VERSION ""

NS_ :

BS_:

BU_: ALARMS_RELAY RUR RUF LOGBOX HVAC CP6 CP10 RUC BC BMS1_SDB BMS2_SDB BMS0_SDB _TESTER NC_SENSOR IVS
VAL_TABLE_ Vis_Activation 1 "ON" 0 "OFF" ;
VAL_TABLE_ Vis_Blackout 1 "BLACKOUT" 0 "NO_BLACKOUT" ;
VAL_TABLE_ ___spare___ 3 "_SPARE_3" 2 "_SPARE_2" 1 "_SPARE_1" 0 "_SPARE_0" ;
VAL_TABLE_ HeaterWaterTemp 255 "NOT AVAILABLE" 254 "ERROR" ;

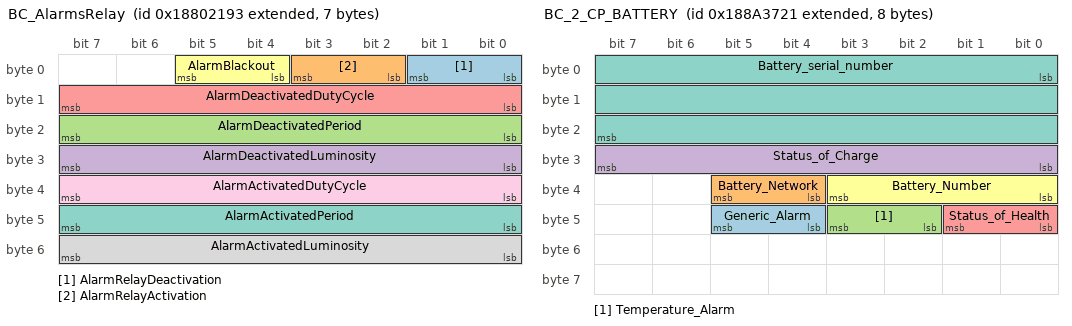
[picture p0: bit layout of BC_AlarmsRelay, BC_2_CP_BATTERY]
BO_ 2558534035 BC_AlarmsRelay: 7 BC
 SG_ AlarmRelayDeactivation : 0|2@1+ (1,0) [0|0] "bit"  ALARMS_RELAY
 SG_ AlarmRelayActivation : 2|2@1+ (1,0) [0|0] "bit"  ALARMS_RELAY
 SG_ AlarmDeactivatedPeriod : 16|8@1+ (1,0) [0|250] "1/10sec"  ALARMS_RELAY
 SG_ AlarmDeactivatedLuminosity : 24|8@1+ (0.4,0) [0|100] "%"  ALARMS_RELAY
 SG_ AlarmDeactivatedDutyCycle : 8|8@1+ (0.4,0) [0|100] "%"  ALARMS_RELAY
 SG_ AlarmBlackout : 4|2@1+ (1,0) [0|0] ""  ALARMS_RELAY
 SG_ AlarmActivatedPeriod : 40|8@1+ (1,0) [0|250] "1/10sec"  ALARMS_RELAY
 SG_ AlarmActivatedLuminosity : 48|8@1+ (0.4,0) [0|100] "%"  ALARMS_RELAY
 SG_ AlarmActivatedDutyCycle : 32|8@1+ (0.4,0) [0|100] "%"  ALARMS_RELAY

BO_ 2559194913 BC_2_CP_BATTERY: 8 BC
 SG_ Generic_Alarm : 44|2@1+ (1,0) [0|3] "-"  CP6,CP10,LOGBOX
 SG_ Battery_Network : 36|2@1+ (1,0) [0|3] "-"  CP6,CP10,LOGBOX
 SG_ Temperature_Alarm : 42|2@1+ (1,0) [0|3] "-"  CP6,CP10,LOGBOX
 SG_ Status_of_Charge : 24|8@1+ (1,0) [0|100] "%"  CP6,CP10,LOGBOX
 SG_ Status_of_Health : 40|2@1+ (1,0) [0|3] "-"  CP6,CP10,LOGBOX
 SG_ Battery_Number : 32|4@1+ (1,0) [0|15] "-"  CP6,CP10,LOGBOX
 SG_ Battery_serial_number : 0|24@1+ (1,0) [0|16777214] "-"  CP6,CP10,LOGBOX

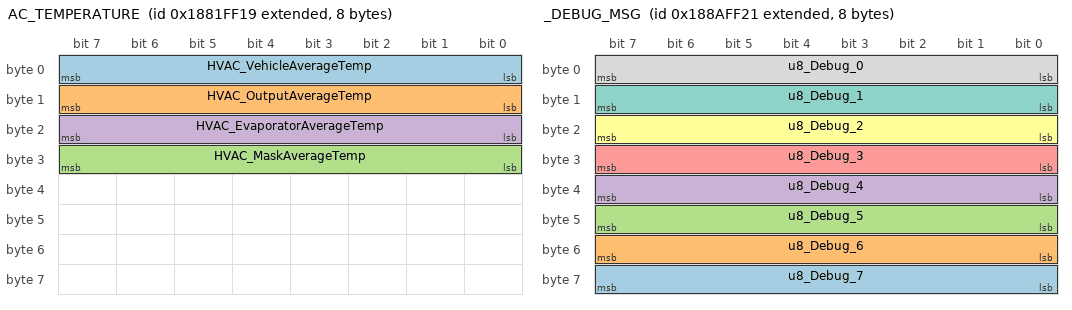
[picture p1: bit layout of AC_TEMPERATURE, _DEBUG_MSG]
BO_ 2558656281 AC_TEMPERATURE: 8 HVAC
 SG_ HVAC_VehicleAverageTemp : 0|8@1+ (1,-40) [-40|210] "°C"  BC,LOGBOX
 SG_ HVAC_OutputAverageTemp : 8|8@1+ (1,-40) [-40|210] "°C"  BC,LOGBOX
 SG_ HVAC_MaskAverageTemp : 24|8@1+ (1,-40) [-40|210] "°C"  BC,LOGBOX
 SG_ HVAC_EvaporatorAverageTemp : 16|8@1+ (1,-40) [-40|210] "°C"  BC,LOGBOX

BO_ 2559246113 _DEBUG_MSG: 8 BC
 SG_ u8_Debug_7 : 56|8@1+ (1,0) [0|255] "-"  LOGBOX
 SG_ u8_Debug_6 : 48|8@1+ (1,0) [0|255] "-"  LOGBOX
 SG_ u8_Debug_5 : 40|8@1+ (1,0) [0|255] "-"  LOGBOX
 SG_ u8_Debug_4 : 32|8@1+ (1,0) [0|255] "-"  LOGBOX
 SG_ u8_Debug_3 : 24|8@1+ (1,0) [0|255] "-"  LOGBOX
 SG_ u8_Debug_2 : 16|8@1+ (1,0) [0|255] "-"  LOGBOX
 SG_ u8_Debug_1 : 8|8@1+ (1,0) [0|255] "-"  LOGBOX
 SG_ u8_Debug_0 : 0|8@1+ (1,0) [0|255] "-"  LOGBOX

BO_ 2559129377 TRIP_PARTIALS: 8 BC
 SG_ Partial_km : 0|16@1+ (0.1,0) [0|6400] "km"  LOGBOX,CP6,CP10
 SG_ Partial_h : 16|16@1+ (0.1,0) [0|6400] "h"  LOGBOX,CP6,CP10

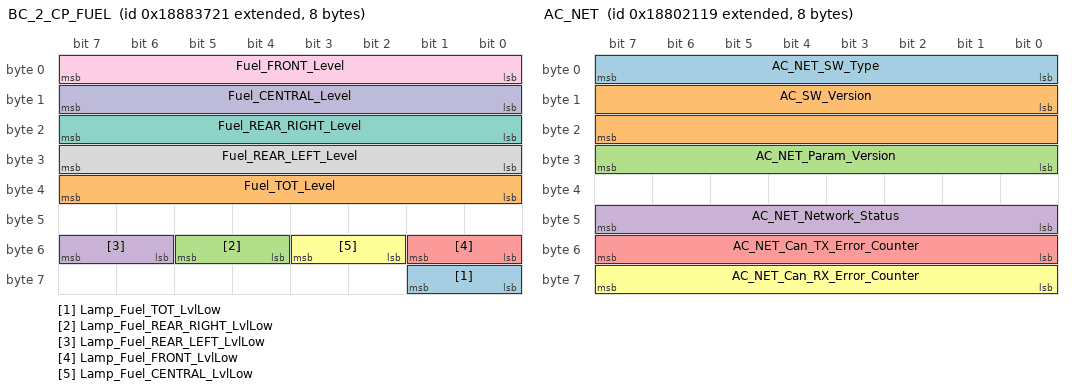
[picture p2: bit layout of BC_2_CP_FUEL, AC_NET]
BO_ 2559063841 BC_2_CP_FUEL: 8 BC
 SG_ Lamp_Fuel_TOT_LvlLow : 56|2@1+ (1,0) [0|3] "-"  IVS,LOGBOX,CP6,CP10
 SG_ Fuel_TOT_Level : 32|8@1+ (0.4,0) [0|100] "%"  LOGBOX,CP6,CP10
 SG_ Lamp_Fuel_REAR_RIGHT_LvlLow : 52|2@1+ (1,0) [0|3] "-"  LOGBOX,CP6,CP10
 SG_ Lamp_Fuel_REAR_LEFT_LvlLow : 54|2@1+ (1,0) [0|3] "-"  LOGBOX,CP6,CP10
 SG_ Lamp_Fuel_FRONT_LvlLow : 48|2@1+ (1,0) [0|3] "-"  LOGBOX,CP6,CP10
 SG_ Lamp_Fuel_CENTRAL_LvlLow : 50|2@1+ (1,0) [0|3] "-"  LOGBOX,CP6,CP10
 SG_ Fuel_REAR_RIGHT_Level : 16|8@1+ (0.4,0) [0|100] "%"  LOGBOX,CP6,CP10
 SG_ Fuel_REAR_LEFT_Level : 24|8@1+ (0.4,0) [0|100] "%"  LOGBOX,CP6,CP10
 SG_ Fuel_FRONT_Level : 0|8@1+ (0.4,0) [0|100] "%"  LOGBOX,CP6,CP10
 SG_ Fuel_CENTRAL_Level : 8|8@1+ (0.4,0) [0|100] "%"  LOGBOX,CP6,CP10

BO_ 2566834942 _DM1: 42 Vector__XXX
 SG_ SPN10_Low : 320|16@1+ (1,0) [0|65536] "-"  CP6,CP10,LOGBOX
 SG_ SPN9_Low : 288|16@1+ (1,0) [0|65536] "-"  CP6,CP10,LOGBOX
 SG_ SPN8_Low : 256|16@1+ (1,0) [0|65536] "-"  CP6,CP10,LOGBOX
 SG_ SPN7_Low : 224|16@1+ (1,0) [0|65536] "-"  CP6,CP10,LOGBOX
 SG_ SPN6_Low : 192|16@1+ (1,0) [0|65536] "-"  CP6,CP10,LOGBOX
 SG_ SPN5_Low : 144|16@1+ (1,0) [0|65536] "-"  CP6,CP10,LOGBOX
 SG_ SPN4_Low : 112|16@1+ (1,0) [0|65536] "-"  CP6,CP10,LOGBOX
 SG_ SPN3_Low : 80|16@1+ (1,0) [0|65536] "-"  CP6,CP10,LOGBOX
 SG_ SPN2_Low : 48|16@1+ (1,0) [0|65536] "-"  CP6,CP10,LOGBOX
 SG_ FailureModeIdentifier10 : 304|5@1+ (1,0) [0|31] "-"  CP6,CP10,LOGBOX
 SG_ FailureModeIdentifier9 : 272|5@1+ (1,0) [0|31] "-"  CP6,CP10,LOGBOX
 SG_ FailureModeIdentifier8 : 240|5@1+ (1,0) [0|31] "-"  CP6,CP10,LOGBOX
 SG_ FailureModeIdentifier7 : 208|5@1+ (1,0) [0|31] "-"  CP6,CP10,LOGBOX
 SG_ FailureModeIdentifier6 : 176|5@1+ (1,0) [0|31] "-"  CP6,CP10,LOGBOX
 SG_ FailureModeIdentifier5 : 160|5@1+ (1,0) [0|31] "-"  CP6,CP10,LOGBOX
 SG_ FailureModeIdentifier4 : 128|5@1+ (1,0) [0|31] "-"  CP6,CP10,LOGBOX
 SG_ FailureModeIdentifier3 : 96|5@1+ (1,0) [0|31] "-"  CP6,CP10,LOGBOX
 SG_ FlashRedStopLamp : 12|2@1+ (1,0) [0|3] "-"  CP6,CP10,LOGBOX
 SG_ FlashProtectLamp : 8|2@1+ (1,0) [0|3] "-"  CP6,CP10,LOGBOX
 SG_ FlashMalfuncIndicatorLamp : 14|2@1+ (1,0) [0|3] "-"  CP6,CP10,LOGBOX
 SG_ FlashAmberWarningLamp : 10|2@1+ (1,0) [0|3] "-"  CP6,CP10,LOGBOX
 SG_ MalfunctionIndicatorLampStatus : 6|2@1+ (1,0) [0|3] "-"  CP6,CP10,LOGBOX
 SG_ AmberWarningLampStatus : 2|2@1+ (1,0) [0|3] "-"  CP6,CP10,LOGBOX
 SG_ OccurenceCount1 : 40|7@1+ (1,0) [0|126] "-"  CP6,CP10,LOGBOX
 SG_ SPNConversionMethod1 : 47|1@1+ (1,0) [0|1] "-"  CP6,CP10,LOGBOX
 SG_ FailureModeIdentifier1 : 32|5@1+ (1,0) [0|31] "-"  CP6,CP10,LOGBOX
 SG_ SPN1_Low : 16|16@1+ (1,0) [0|65536] "-"  CP6,CP10,LOGBOX
 SG_ RedStopLampState : 4|2@1+ (1,0) [0|3] "-"  CP6,CP10,LOGBOX
 SG_ ProtectLampStatus : 0|2@1+ (1,0) [0|3] "-"  CP6,CP10,LOGBOX
 SG_ FailureModeIdentifier2 : 64|5@1+ (1,0) [0|31] "-"  CP6,CP10,LOGBOX
 SG_ SPNConversionMethod10 : 319|1@1+ (1,0) [0|1] "-"  CP6,CP10,LOGBOX
 SG_ SPNConversionMethod9 : 287|1@1+ (1,0) [0|1] "-"  CP6,CP10,LOGBOX
 SG_ SPNConversionMethod8 : 255|1@1+ (1,0) [0|1] "-"  CP6,CP10,LOGBOX
 SG_ SPNConversionMethod7 : 223|1@1+ (1,0) [0|1] "-"  CP6,CP10,LOGBOX
 SG_ SPNConversionMethod6 : 191|1@1+ (1,0) [0|1] "-"  CP6,CP10,LOGBOX
 SG_ SPNConversionMethod5 : 175|1@1+ (1,0) [0|1] "-"  CP6,CP10,LOGBOX
 SG_ SPNConversionMethod4 : 143|1@1+ (1,0) [0|1] "-"  CP6,CP10,LOGBOX
 SG_ SPNConversionMethod3 : 111|1@1+ (1,0) [0|1] "-"  CP6,CP10,LOGBOX
 SG_ SPNConversionMethod2 : 79|1@1+ (1,0) [0|1] "-"  CP6,CP10,LOGBOX
 SG_ OccurenceCount10 : 312|7@1+ (1,0) [0|126] "-"  CP6,CP10,LOGBOX
 SG_ OccurenceCount9 : 280|7@1+ (1,0) [0|126] "-"  CP6,CP10,LOGBOX
 SG_ OccurenceCount8 : 248|7@1+ (1,0) [0|126] "-"  CP6,CP10,LOGBOX
 SG_ OccurenceCount7 : 216|7@1+ (1,0) [0|126] "-"  CP6,CP10,LOGBOX
 SG_ OccurenceCount6 : 184|7@1+ (1,0) [0|126] "-"  CP6,CP10,LOGBOX
 SG_ OccurenceCount5 : 168|7@1+ (1,0) [0|126] "-"  CP6,CP10,LOGBOX
 SG_ OccurenceCount4 : 136|7@1+ (1,0) [0|126] "-"  CP6,CP10,LOGBOX
 SG_ OccurenceCount3 : 104|7@1+ (1,0) [0|126] "-"  CP6,CP10,LOGBOX
 SG_ OccurenceCount2 : 72|7@1+ (1,0) [0|126] "-"  CP6,CP10,LOGBOX
 SG_ SPN10_High : 309|3@1+ (1,0) [0|7] "-"  CP6,CP10,LOGBOX
 SG_ SPN9_High : 277|3@1+ (1,0) [0|7] "-"  CP6,CP10,LOGBOX
 SG_ SPN8_High : 245|3@1+ (1,0) [0|7] "-"  CP6,CP10,LOGBOX
 SG_ SPN7_High : 213|3@1+ (1,0) [0|7] "-"  CP6,CP10,LOGBOX
 SG_ SPN6_High : 181|3@1+ (1,0) [0|7] "-"  CP6,CP10,LOGBOX
 SG_ SPN5_High : 165|3@1+ (1,0) [0|7] "-"  CP6,CP10,LOGBOX
 SG_ SPN4_High : 133|3@1+ (1,0) [0|7] "-"  CP6,CP10,LOGBOX
 SG_ SPN3_High : 101|3@1+ (1,0) [0|7] "-"  CP6,CP10,LOGBOX
 SG_ SPN2_High : 69|3@1+ (1,0) [0|7] "-"  CP6,CP10,LOGBOX
 SG_ SPN1_High : 37|3@1+ (1,0) [0|7] "-"  CP6,CP10,LOGBOX

BO_ 2558533913 AC_NET: 8 HVAC
 SG_ AC_NET_SW_Type : 0|8@1+ (1,0) [0|255] "-"  LOGBOX,BC
 SG_ AC_SW_Version : 8|16@1+ (1,0) [0|65535] "-"  LOGBOX,BC
 SG_ AC_NET_Param_Version : 24|8@1+ (1,0) [0|0] "-"  LOGBOX,BC
 SG_ AC_NET_Network_Status : 40|8@1+ (1,0) [0|0] "-"  LOGBOX,BC
 SG_ AC_NET_Can_TX_Error_Counter : 48|8@1+ (1,0) [0|255] "-"  LOGBOX,BC
 SG_ AC_NET_Can_RX_Error_Counter : 56|8@1+ (1,0) [0|255] "-"  LOGBOX,BC

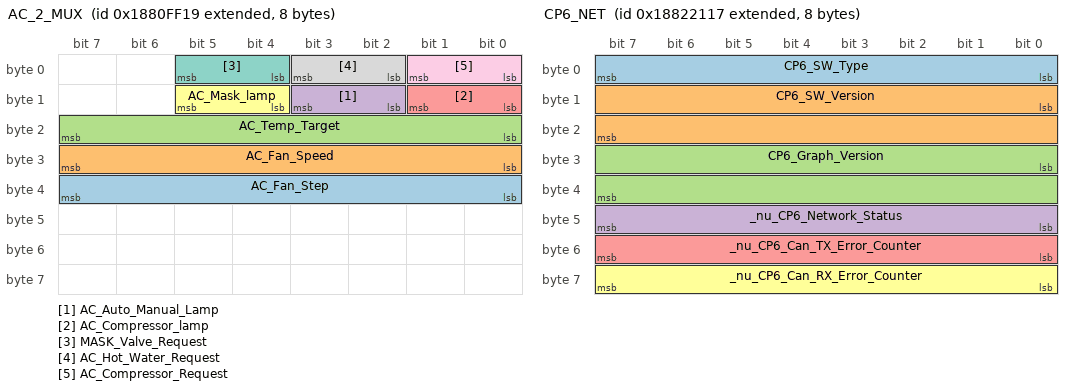
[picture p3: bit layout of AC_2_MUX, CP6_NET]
BO_ 2558590745 AC_2_MUX: 8 HVAC
 SG_ AC_Fan_Step : 32|8@1+ (1,0) [0|10] "step"  LOGBOX,CP6,CP10,BC
 SG_ AC_Fan_Speed : 24|8@1+ (0.4,0) [0|100] "%"  LOGBOX,CP6,CP10,BC
 SG_ AC_Temp_Target : 16|8@1+ (0.5,0) [0|30] "°C"  LOGBOX,CP6,CP10,BC
 SG_ AC_Auto_Manual_Lamp : 10|2@1+ (1,0) [0|3] "-"  LOGBOX,CP6,CP10,BC
 SG_ AC_Compressor_lamp : 8|2@1+ (1,0) [0|3] "-"  LOGBOX,CP6,CP10,BC
 SG_ AC_Mask_lamp : 12|2@1+ (1,0) [0|3] "-"  LOGBOX,CP6,CP10,BC
 SG_ MASK_Valve_Request : 4|2@1+ (1,0) [0|3] "-"  LOGBOX,CP6,CP10,BC
 SG_ AC_Hot_Water_Request : 2|2@1+ (1,0) [0|3] "-"  LOGBOX,CP6,CP10,BC
 SG_ AC_Compressor_Request : 0|2@1+ (1,0) [0|3] "-"  LOGBOX,CP6,CP10,BC

BO_ 2558664983 CP6_NET: 8 CP6
 SG_ CP6_SW_Type : 0|8@1+ (1,0) [0|255] "-"  LOGBOX,BC
 SG_ CP6_SW_Version : 8|16@1+ (1,0) [0|65535] "-"  LOGBOX,BC
 SG_ CP6_Graph_Version : 24|16@1+ (1,0) [0|65535] "-"  LOGBOX,BC
 SG_ _nu_CP6_Network_Status : 40|8@1+ (1,0) [0|255] "-"  LOGBOX,BC
 SG_ _nu_CP6_Can_TX_Error_Counter : 48|8@1+ (1,0) [0|255] "-"  LOGBOX,BC
 SG_ _nu_CP6_Can_RX_Error_Counter : 56|8@1+ (1,0) [0|255] "-"  LOGBOX,BC

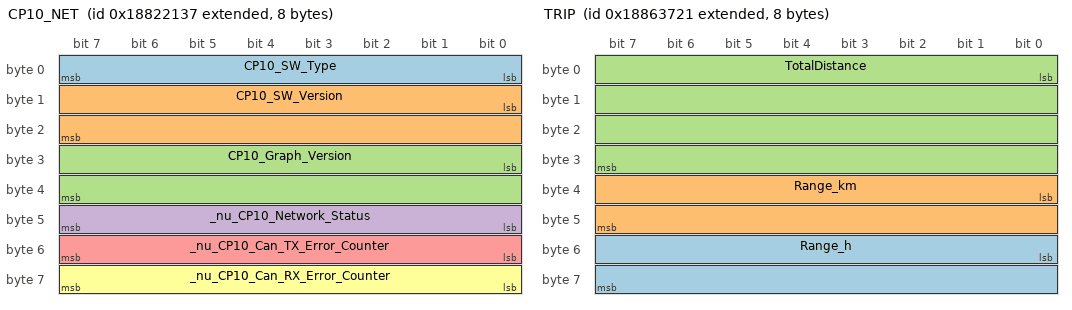
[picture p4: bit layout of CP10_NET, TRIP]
BO_ 2558665015 CP10_NET: 8 CP10
 SG_ CP10_SW_Type : 0|8@1+ (1,0) [0|255] "-"  LOGBOX,BC
 SG_ CP10_SW_Version : 8|16@1+ (1,0) [0|65535] "-"  LOGBOX,BC
 SG_ CP10_Graph_Version : 24|16@1+ (1,0) [0|65535] "-"  LOGBOX,BC
 SG_ _nu_CP10_Network_Status : 40|8@1+ (1,0) [0|255] "-"  LOGBOX,BC
 SG_ _nu_CP10_Can_TX_Error_Counter : 48|8@1+ (1,0) [0|255] "-"  LOGBOX,BC
 SG_ _nu_CP10_Can_RX_Error_Counter : 56|8@1+ (1,0) [0|255] "-"  LOGBOX,BC

BO_ 2558656289 BC_GATEWAY: 8 BC
 SG_ TachographVehicleSpeed_GTW : 16|16@1+ (0.00390625,0) [0|250.996] "km/h"  RUC,RUF,RUR,HVAC,LOGBOX,CP6,CP10
 SG_ EngSpeed_GTW : 0|16@1+ (0.125,0) [0|8031.875] "rpm"  RUC,RUF,RUR,HVAC,LOGBOX,CP6,CP10

BO_ 2566846241 VEP: 8 BC
 SG_ BatteryPotential : 0|8@1+ (0.2,0) [0|50] "V"  RUC,RUF,RUR,LOGBOX,CP6,CP10

BO_ 2558932769 TRIP: 8 BC
 SG_ Range_h : 48|16@1+ (0.1,0) [0|6400] "h"  LOGBOX,CP6,CP10
 SG_ Range_km : 32|16@1+ (0.1,0) [0|6400] "km"  LOGBOX,CP6,CP10
 SG_ TotalDistance : 0|32@1+ (0.005,0) [0|999999.9] "km"  HVAC,LOGBOX,CP6,CP10

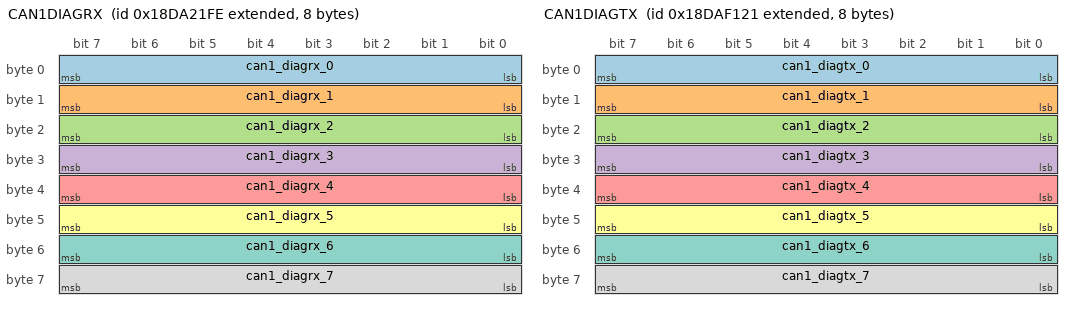
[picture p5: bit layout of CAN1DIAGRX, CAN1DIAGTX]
BO_ 2564432382 CAN1DIAGRX: 8 _TESTER
 SG_ can1_diagrx_0 : 0|8@1+ (1,0) [0|0] "-"  LOGBOX,BC
 SG_ can1_diagrx_1 : 8|8@1+ (1,0) [0|0] "-"  LOGBOX,BC
 SG_ can1_diagrx_2 : 16|8@1+ (1,0) [0|0] "-"  LOGBOX,BC
 SG_ can1_diagrx_3 : 24|8@1+ (1,0) [0|0] "-"  LOGBOX,BC
 SG_ can1_diagrx_4 : 32|8@1+ (1,0) [0|0] "-"  LOGBOX,BC
 SG_ can1_diagrx_5 : 40|8@1+ (1,0) [0|0] "-"  LOGBOX,BC
 SG_ can1_diagrx_6 : 48|8@1+ (1,0) [0|0] "-"  LOGBOX,BC
 SG_ can1_diagrx_7 : 56|8@1+ (1,0) [0|0] "-"  LOGBOX,BC

BO_ 2564485409 CAN1DIAGTX: 8 BC
 SG_ can1_diagtx_0 : 0|8@1+ (1,0) [0|0] "-"  LOGBOX,_TESTER
 SG_ can1_diagtx_1 : 8|8@1+ (1,0) [0|0] "-"  LOGBOX,_TESTER
 SG_ can1_diagtx_2 : 16|8@1+ (1,0) [0|0] "-"  LOGBOX,_TESTER
 SG_ can1_diagtx_3 : 24|8@1+ (1,0) [0|0] "-"  LOGBOX,_TESTER
 SG_ can1_diagtx_4 : 32|8@1+ (1,0) [0|0] "-"  LOGBOX,_TESTER
 SG_ can1_diagtx_5 : 40|8@1+ (1,0) [0|0] "-"  LOGBOX,_TESTER
 SG_ can1_diagtx_6 : 48|8@1+ (1,0) [0|0] "-"  LOGBOX,_TESTER
 SG_ can1_diagtx_7 : 56|8@1+ (1,0) [0|0] "-"  LOGBOX,_TESTER

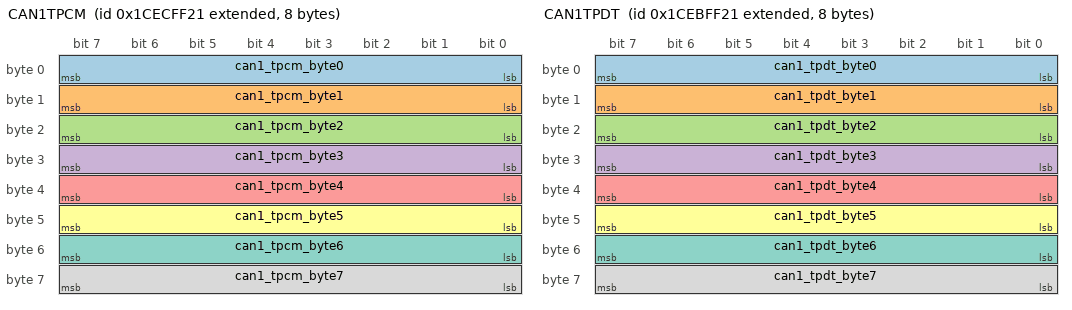
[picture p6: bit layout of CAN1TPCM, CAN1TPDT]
BO_ 2632777505 CAN1TPCM: 8 BC
 SG_ can1_tpcm_byte0 : 0|8@1+ (1,0) [0|0] "-"  LOGBOX,_TESTER
 SG_ can1_tpcm_byte1 : 8|8@1+ (1,0) [0|0] "-"  LOGBOX,_TESTER
 SG_ can1_tpcm_byte2 : 16|8@1+ (1,0) [0|0] "-"  LOGBOX,_TESTER
 SG_ can1_tpcm_byte3 : 24|8@1+ (1,0) [0|0] "-"  LOGBOX,_TESTER
 SG_ can1_tpcm_byte4 : 32|8@1+ (1,0) [0|0] "-"  LOGBOX,_TESTER
 SG_ can1_tpcm_byte5 : 40|8@1+ (1,0) [0|0] "-"  LOGBOX,_TESTER
 SG_ can1_tpcm_byte6 : 48|8@1+ (1,0) [0|0] "-"  LOGBOX,_TESTER
 SG_ can1_tpcm_byte7 : 56|8@1+ (1,0) [0|0] "-"  LOGBOX,_TESTER

BO_ 2632711969 CAN1TPDT: 8 BC
 SG_ can1_tpdt_byte0 : 0|8@1+ (1,0) [0|0] "-"  LOGBOX,_TESTER
 SG_ can1_tpdt_byte1 : 8|8@1+ (1,0) [0|0] "-"  LOGBOX,_TESTER
 SG_ can1_tpdt_byte2 : 16|8@1+ (1,0) [0|0] "-"  LOGBOX,_TESTER
 SG_ can1_tpdt_byte3 : 24|8@1+ (1,0) [0|0] "-"  LOGBOX,_TESTER
 SG_ can1_tpdt_byte4 : 32|8@1+ (1,0) [0|0] "-"  LOGBOX,_TESTER
 SG_ can1_tpdt_byte5 : 40|8@1+ (1,0) [0|0] "-"  LOGBOX,_TESTER
 SG_ can1_tpdt_byte6 : 48|8@1+ (1,0) [0|0] "-"  LOGBOX,_TESTER
 SG_ can1_tpdt_byte7 : 56|8@1+ (1,0) [0|0] "-"  LOGBOX,_TESTER

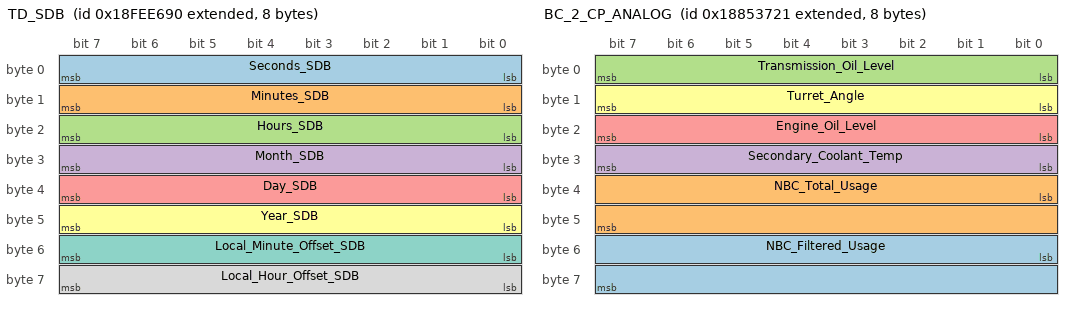
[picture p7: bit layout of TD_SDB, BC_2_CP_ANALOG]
BO_ 2566842000 TD_SDB: 8 LOGBOX
 SG_ Seconds_SDB : 0|8@1+ (0.25,0) [0|59.75] "s"  BC
 SG_ Minutes_SDB : 8|8@1+ (1,0) [0|59] "mun"  BC
 SG_ Hours_SDB : 16|8@1+ (1,0) [0|23] "-"  BC
 SG_ Month_SDB : 24|8@1+ (1,0) [1|12] "-"  BC
 SG_ Day_SDB : 32|8@1+ (0.25,0) [0.25|31.75] "-"  BC
 SG_ Year_SDB : 40|8@1+ (1,1985) [1985|2235] "-"  BC
 SG_ Local_Minute_Offset_SDB : 48|8@1+ (1,-125) [-59|59] "-"  BC
 SG_ Local_Hour_Offset_SDB : 56|8@1+ (1,-125) [-23|23] "-"  BC

BO_ 2558736161 BC_2_CP_ALARM: 8 BC
 SG_ Lamp_NC_Sensor_NC_Alarm : 44|2@1+ (1,0) [0|3] "-"  IVS,CP6,CP10,LOGBOX
 SG_ Lamp_Transmission_Oil_Level : 0|2@1+ (1,0) [0|3] "-"  CP6,CP10,LOGBOX
 SG_ Lamp_NC_Sensor_C_Alarm : 8|2@1+ (1,0) [0|3] "-"  CP6,CP10,LOGBOX
 SG_ Lamp_NC_Sensor_N_Alarm : 2|2@1+ (1,0) [0|3] "-"  CP6,CP10,LOGBOX
 SG_ Lamp_NBC_PreFilterClogged : 6|2@1+ (1,0) [0|3] "-"  CP6,CP10,LOGBOX
 SG_ Lamp_WaterInFuel : 54|2@1+ (1,0) [0|3] "-"  IVS,CP6,CP10,LOGBOX
 SG_ Lamp_Engine_Oil_Level : 10|2@1+ (1,0) [0|3] "-"  CP6,CP10,LOGBOX
 SG_ Lamp_Engine_AirFilter_Clogged : 12|2@1+ (1,0) [0|3] "-"  CP6,CP10,LOGBOX
 SG_ Lamp_Engine_Coolant_Level_Low : 14|2@1+ (1,0) [0|3] "-"  IVS,CP6,CP10,LOGBOX
 SG_ Lamp_Cooling_Fan_Fault : 16|2@1+ (1,0) [0|3] "-"  IVS,CP6,CP10,LOGBOX
 SG_ Lamp_Fuel_Filter_Clogged : 60|4@1+ (1,0) [0|15] "-"  IVS,CP6,CP10,LOGBOX
 SG_ Lamp_Services_AirPressure_Low : 20|2@1+ (1,0) [0|3] "-"  IVS,CP6,CP10,LOGBOX
 SG_ Lamp_Powersteering1LowPress : 28|2@1+ (1,0) [0|3] "-"  IVS,CP6,CP10,LOGBOX
 SG_ Lamp_Powersteering2LowPress : 30|2@1+ (1,0) [0|3] "-"  IVS,CP6,CP10,LOGBOX
 SG_ Lamp_PowersteeringLowOilLevel : 32|2@1+ (1,0) [0|3] "-"  IVS,CP6,CP10,LOGBOX
 SG_ Lamp_Pneumatic_Park_Brake : 34|2@1+ (1,0) [0|3] "-"  CP6,CP10,LOGBOX
 SG_ Lamp_Mechanical_Park_Brake : 38|2@1+ (1,0) [0|3] "-"  CP6,CP10,LOGBOX
 SG_ Lamp_NBC_Fault : 40|2@1+ (1,0) [0|3] "-"  CP6,CP10,LOGBOX
 SG_ Lamp_NBC_LowPressure : 42|2@1+ (1,0) [0|3] "-"  CP6,CP10,LOGBOX
 SG_ Lamp_NBC_FilterClogged : 4|2@1+ (1,0) [0|3] "-"  CP6,CP10,LOGBOX
 SG_ Lamp_Gear_Oil_Temp_High : 52|2@1+ (1,0) [0|3] "-"  IVS,CP6,CP10,LOGBOX
 SG_ Lamp_Brake_LowPressure : 56|4@1+ (1,0) [0|15] "-"  IVS,CP6,CP10,LOGBOX
 SG_ Lamp_Alternator : 46|2@1+ (1,0) [0|3] "-"  IVS,CP6,CP10,LOGBOX
 SG_ Lamp_Fuel_Temp_High : 50|2@1+ (1,0) [0|3] "-"  IVS,CP6,CP10,LOGBOX
 SG_ Lamp_NBC_FilterInstalled : 22|2@1+ (1,0) [0|3] "-"  CP6,CP10,LOGBOX
 SG_ Lamp_Battle_Short : 48|2@1+ (1,0) [0|3] "-"  IVS,CP6,CP10,LOGBOX
 SG_ Lamp_Battle_Switch : 24|2@1+ (1,0) [0|3] "-"  IVS,CP6,CP10,LOGBOX
 SG_ Lamp_Brake_LowOilLevel : 26|2@1+ (1,0) [0|3] "-"  IVS,CP6,CP10,LOGBOX
 SG_ Lamp_EngineCoolant1TempHigh : 36|2@1+ (1,0) [0|3] "-"  IVS,CP6,CP10,LOGBOX
 SG_ Lamp_EngineCoolant2TempHigh : 18|2@1+ (1,0) [0|3] "-"  CP6,CP10,LOGBOX

BO_ 2558867233 BC_2_CP_ANALOG: 8 BC
 SG_ NBC_Filtered_Usage : 48|16@1+ (0.1,0) [0|6400] "h"  CP6,CP10,LOGBOX
 SG_ NBC_Total_Usage : 32|16@1+ (0.1,0) [0|6400] "h"  CP6,CP10,LOGBOX
 SG_ Transmission_Oil_Level : 0|8@1+ (0.5,-62.5) [-62.5|62.5] "l"  CP6,CP10,LOGBOX
 SG_ Secondary_Coolant_Temp : 24|8@1+ (1,-40) [-40|210] "°C"  LOGBOX,CP6,CP10
 SG_ Engine_Oil_Level : 16|8@1+ (0.4,0) [0|100] "%"  LOGBOX,CP6,CP10
 SG_ Turret_Angle : 8|8@1+ (1.44,-180) [-180|180] "deg"  LOGBOX,CP6,CP10

BO_ 2558998305 WARNINGS: 8 BC
 SG_ POWERSTR_SPEED_TOO_HIGH : 7|1@1+ (1,0) [0|1] "-"  LOGBOX,CP6,CP10
 SG_ _nu_Warnings_bit63 : 63|1@1+ (1,0) [0|1] "-"  LOGBOX
 SG_ _nu_Warnings_bit62 : 62|1@1+ (1,0) [0|1] "-"  LOGBOX
 SG_ _nu_Warnings_bit61 : 61|1@1+ (1,0) [0|1] "-"  LOGBOX
 SG_ _nu_Warnings_bit60 : 60|1@1+ (1,0) [0|1] "-"  LOGBOX
 SG_ _nu_Warnings_bit59 : 59|1@1+ (1,0) [0|1] "-"  LOGBOX
 SG_ _nu_Warnings_bit58 : 58|1@1+ (1,0) [0|1] "-"  LOGBOX
 SG_ _nu_Warnings_bit57 : 57|1@1+ (1,0) [0|1] "-"  LOGBOX
 SG_ _nu_Warnings_bit56 : 56|1@1+ (1,0) [0|1] "-"  LOGBOX
 SG_ _nu_Warnings_bit55 : 55|1@1+ (1,0) [0|1] "-"  LOGBOX
 SG_ _nu_Warnings_bit54 : 54|1@1+ (1,0) [0|1] "-"  LOGBOX
 SG_ _nu_Warnings_bit53 : 53|1@1+ (1,0) [0|1] "-"  LOGBOX
 SG_ _nu_Warnings_bit52 : 52|1@1+ (1,0) [0|1] "-"  LOGBOX
 SG_ _nu_Warnings_bit51 : 51|1@1+ (1,0) [0|1] "-"  LOGBOX
 SG_ _nu_Warnings_bit50 : 50|1@1+ (1,0) [0|1] "-"  LOGBOX
 SG_ _nu_Warnings_bit49 : 49|1@1+ (1,0) [0|1] "-"  LOGBOX
 SG_ _nu_Warnings_bit48 : 48|1@1+ (1,0) [0|1] "-"  LOGBOX
 SG_ _nu_Warnings_bit47 : 47|1@1+ (1,0) [0|1] "-"  LOGBOX
 SG_ _nu_Warnings_bit46 : 46|1@1+ (1,0) [0|1] "-"  LOGBOX
 SG_ _nu_Warnings_bit45 : 45|1@1+ (1,0) [0|1] "-"  LOGBOX
 SG_ _nu_Warnings_bit44 : 44|1@1+ (1,0) [0|1] "-"  LOGBOX
 SG_ _nu_Warnings_bit43 : 43|1@1+ (1,0) [0|1] "-"  LOGBOX
 SG_ _nu_Warnings_bit42 : 42|1@1+ (1,0) [0|1] "-"  LOGBOX
 SG_ _nu_Warnings_bit41 : 41|1@1+ (1,0) [0|1] "-"  LOGBOX
 SG_ _nu_Warnings_bit40 : 40|1@1+ (1,0) [0|1] "-"  LOGBOX
 SG_ _nu_Warnings_bit39 : 39|1@1+ (1,0) [0|1] "-"  LOGBOX
 SG_ _nu_Warnings_bit38 : 38|1@1+ (1,0) [0|1] "-"  LOGBOX
 SG_ _nu_Warnings_bit37 : 37|1@1+ (1,0) [0|1] "-"  LOGBOX
 SG_ _nu_Warnings_bit36 : 36|1@1+ (1,0) [0|1] "-"  LOGBOX
 SG_ _nu_Warnings_bit35 : 35|1@1+ (1,0) [0|1] "-"  LOGBOX
 SG_ _nu_Warnings_bit34 : 34|1@1+ (1,0) [0|1] "-"  LOGBOX
 SG_ _nu_Warnings_bit33 : 33|1@1+ (1,0) [0|1] "-"  LOGBOX
 SG_ _nu_Warnings_bit32 : 32|1@1+ (1,0) [0|1] "-"  LOGBOX
 SG_ _nu_Warnings_bit31 : 31|1@1+ (1,0) [0|1] "-"  LOGBOX
 SG_ _nu_Warnings_bit30 : 30|1@1+ (1,0) [0|1] "-"  LOGBOX
 SG_ _nu_Warnings_bit18 : 18|1@1+ (1,0) [0|1] "-"  LOGBOX
 SG_ AUX_HEATER_TO_BE_START : 29|1@1+ (1,0) [0|1] "-"  LOGBOX
 SG_ AUX_HEATER_WARNING : 28|1@1+ (1,0) [0|1] "-"  LOGBOX
 SG_ GEARBOX_OVER_TEMP : 27|1@1+ (1,0) [0|1] "-"  LOGBOX
 SG_ LOW_GEARBOX_OIL_LEVEL : 26|1@1+ (1,0) [0|1] "-"  LOGBOX,CP6,CP10
 SG_ LOW_ENGINE_OIL_LEVEL : 25|1@1+ (1,0) [0|1] "-"  LOGBOX,CP6,CP10
 SG_ LOW_BATTERY : 24|1@1+ (1,0) [0|1] "-"  LOGBOX,CP6,CP10
 SG_ FIRE_ALARM : 23|1@1+ (1,0) [0|1] "-"  LOGBOX,CP6,CP10
 SG_ ENGINE_COOLANT_LEVEL_TOO_LOW : 22|1@1+ (1,0) [0|1] "-"  LOGBOX,CP6,CP10
 SG_ ENGINE_TEMPERATURE_TOO_HIGH : 21|1@1+ (1,0) [0|1] "-"  LOGBOX,CP6,CP10
 SG_ OIL_PRESSURE_LOW : 20|1@1+ (1,0) [0|1] "-"  LOGBOX,CP6,CP10
 SG_ ENGINE_OVERRUN_RETARDER_ACTIVE : 19|1@1+ (1,0) [0|1] "-"  LOGBOX,CP6,CP10
 SG_ GEARBOX_NOT_IN_NEUTRAL : 17|1@1+ (1,0) [0|1] "-"  LOGBOX,CP6,CP10
 SG_ BRAKE_NOT_PRESSED : 16|1@1+ (1,0) [0|1] "-"  LOGBOX,CP6,CP10
 SG_ SYSTEM_POWERED_FROM_EXT_SUPPLY : 15|1@1+ (1,0) [0|1] "-"  LOGBOX,CP6,CP10
 SG_ KEY_INSERTED : 14|1@1+ (1,0) [0|1] "-"  LOGBOX,CP6,CP10
 SG_ STARTER_OVERRIDE_IN_PROGRESS : 13|1@1+ (1,0) [0|1] "-"  LOGBOX,CP6,CP10
 SG_ HYDRONIC_SHUTDOWN_IN_PROGRESS : 12|1@1+ (1,0) [0|1] "-"  LOGBOX,CP6,CP10
 SG_ BRAKE_FAULT : 11|1@1+ (1,0) [0|1] "-"  LOGBOX,CP6,CP10
 SG_ DRIVING_WITH_PARK_BRAKE_ACTIVE : 10|1@1+ (1,0) [0|1] "-"  LOGBOX,CP6,CP10
 SG_ SERVICES_AIR_PRESS_LOW : 9|1@1+ (1,0) [0|1] "-"  LOGBOX,CP6,CP10
 SG_ ENGINE_NOT_STOP : 8|1@1+ (1,0) [0|1] "-"  LOGBOX,CP6,CP10
 SG_ DRIVER_HATCH_OPEN : 6|1@1+ (1,0) [0|1] "-"  LOGBOX,CP6,CP10
 SG_ DUST_EXTRACTION_OFF : 5|1@1+ (1,0) [0|1] "-"  LOGBOX,CP6,CP10
 SG_ FORD_MODE_ACTIVE : 4|1@1+ (1,0) [0|1] "-"  LOGBOX,CP6,CP10
 SG_ DANGEROUS_SPEED : 3|1@1+ (1,0) [0|1] "-"  LOGBOX,CP6,CP10
 SG_ SPEED_TOO_HIGH : 2|1@1+ (1,0) [0|1] "-"  LOGBOX,CP6,CP10
 SG_ EMERGENCY_CRANK_IN_PROGRESS : 1|1@1+ (1,0) [0|1] "-"  LOGBOX,CP6,CP10
 SG_ ENGINE_IS_OFF : 0|1@1+ (1,0) [0|1] "-"  LOGBOX,CP6,CP10

BO_ 2558801697 BC_2_CP_ICON: 8 BC
 SG_ EngineAlarm : 46|2@1+ (1,0) [0|3] "-"  IVS
 SG_ EngineOilPressureLow_BC : 42|2@1+ (1,0) [0|3] "-"  IVS
 SG_ EngineOilTemperatureHigh_BC : 40|2@1+ (1,0) [0|3] ""  IVS
 SG_ NBC_Generic_Fault : 38|2@1+ (1,0) [0|3] "-"  IVS,CP6,CP10,LOGBOX
 SG_ EngineEoilFilterClogged : 36|2@1+ (1,0) [0|3] "-"  IVS,CP6,CP10,LOGBOX
 SG_ NBC_FilterClogged_Status : 30|2@1+ (1,0) [0|3] "-"  CP6,CP10,LOGBOX
 SG_ NBC_FilterClogged_Alarm : 28|2@1+ (1,0) [0|3] "-"  CP6,CP10,LOGBOX
 SG_ Icon_Emergency_Direction : 4|2@1+ (1,0) [0|3] "-"  IVS,CP6,CP10,LOGBOX
 SG_ Icon_Light_Status : 20|4@1+ (1,0) [0|7] "-"  IVS,CP6,CP10,LOGBOX
 SG_ Icon_Left_Ammunition_Door : 14|2@1+ (1,0) [0|3] "-"  LOGBOX
 SG_ Icon_Retarder : 16|4@1+ (1,0) [0|15] "-"  LOGBOX,CP6,CP10
 SG_ Icon_Battery_Selected : 26|2@1+ (1,0) [0|3] "-"  LOGBOX,CP6,CP10
 SG_ Icon_Battery_Status : 24|2@1+ (1,0) [0|3] "-"  LOGBOX,CP6,CP10
 SG_ Icon_Driver_Hatch : 6|2@1+ (1,0) [0|3] "-"  LOGBOX,CP6,CP10
 SG_ Icon_Turret_Hatch_Right_Sts : 0|2@1+ (1,0) [0|3] "-"  LOGBOX,CP6,CP10
 SG_ Icon_Turret_Hatch_Left_Sts : 2|2@1+ (1,0) [0|3] "-"  LOGBOX,CP6,CP10
 SG_ Icon_Right_Ammunition_Door : 8|2@1+ (1,0) [0|3] "-"  LOGBOX,CP6,CP10
 SG_ Icon_Rear_Door : 12|2@1+ (1,0) [0|3] "-"  LOGBOX,CP6,CP10
 SG_ Icon_Rear_Lock : 44|2@1+ (1,0) [0|3] "-"  LOGBOX,CP6,CP10
 SG_ ColdStartHeaterStatus_BC : 48|4@1+ (1,0) [0|15] "-"  LOGBOX,CP6,CP10
 SG_ Icon_Payload_Door : 10|2@1+ (1,0) [0|3] "-"  LOGBOX,CP6,CP10
 SG_ Icon_CTIS_ProcessMode : 32|4@1+ (1,0) [0|15] "-"  LOGBOX,CP6,CP10

BO_ 2558670625 BC_2_CP_FBK_3: 8 BC
 SG_ Fbk_Clima_Vent_Step : 4|4@1+ (1,0) [0|10] "step"  LOGBOX,CP6,CP10
 SG_ Fbk_Clima_Menu : 14|2@1+ (1,0) [0|3] "-"  LOGBOX,CP6,CP10
 SG_ Fbk_Clima_Temp_Target : 8|4@1+ (1,16) [16|30] "°C"  LOGBOX,CP6,CP10
 SG_ Fbk_Clima_Compressor : 2|2@1+ (1,0) [0|3] "-"  LOGBOX,CP6,CP10
 SG_ Fbk_Clima_ON_AUTO_MAN : 0|2@1+ (1,0) [0|3] "-"  LOGBOX,CP6,CP10
 SG_ Fbk_Camera_Menu : 46|2@1+ (1,0) [0|3] "-"  LOGBOX,CP6,CP10
 SG_ Fbk_CrewAreaHeater : 12|2@1+ (1,0) [0|3] "-"  LOGBOX,CP6,CP10
 SG_ Fbk_NUC_Enable : 42|2@1+ (1,0) [0|3] "-"  LOGBOX,CP6,CP10
 SG_ Fbk_Polarity : 38|2@1+ (1,0) [0|3] "-"  LOGBOX,CP6,CP10
 SG_ Fbk_ROI : 36|2@1+ (1,0) [0|3] "-"  LOGBOX,CP6,CP10
 SG_ Fbk_TYPE : 34|2@1+ (1,0) [0|3] "-"  LOGBOX,CP6,CP10
 SG_ Fbk_ChangeView : 32|2@1+ (1,0) [0|3] "-"  LOGBOX,CP6,CP10
 SG_ Fbk_Sights_Washer : 44|2@1+ (1,0) [0|3] "-"  LOGBOX,CP6,CP10
 SG_ _nu_Fbk_Not_Used_3_16 : 16|2@1+ (1,0) [0|3] "-"  LOGBOX
 SG_ _nu_Fbk_Not_Used_3_18 : 18|2@1+ (1,0) [0|3] "-"  LOGBOX
 SG_ _nu_Fbk_Not_Used_3_20 : 20|2@1+ (1,0) [0|3] "-"  LOGBOX
 SG_ _nu_Fbk_Not_Used_1_22 : 22|2@1+ (1,0) [0|3] "-"  LOGBOX
 SG_ _nu_Fbk_Not_Used_3_24 : 24|2@1+ (1,0) [0|3] "-"  LOGBOX
 SG_ _nu_Fbk_Not_Used_3_26 : 26|2@1+ (1,0) [0|3] "-"  LOGBOX
 SG_ _nu_Fbk_Not_Used_3_28 : 28|2@1+ (1,0) [0|3] "-"  LOGBOX
 SG_ _nu_Fbk_Not_Used_3_30 : 30|2@1+ (1,0) [0|3] "-"  LOGBOX
 SG_ Fbk_PerimetralVision : 40|2@1+ (1,0) [0|3] "-"  LOGBOX,CP6,CP10
 SG_ Fbk_SelMonitor : 48|2@1+ (1,0) [0|3] "-"  LOGBOX,CP6,CP10
 SG_ Fbk_SelTlc : 50|2@1+ (1,0) [0|3] "-"  LOGBOX,CP6,CP10
 SG_ Fbk_SelCfg : 52|2@1+ (1,0) [0|3] "-"  LOGBOX,CP6,CP10
 SG_ Fbk_SaveCfg : 54|2@1+ (1,0) [0|3] "-"  LOGBOX,CP6,CP10
 SG_ Fbk_RestoreCfg : 56|2@1+ (1,0) [0|3] "-"  LOGBOX,CP6,CP10
 SG_ Fbk_HeaterTlc : 58|2@1+ (1,0) [0|3] "-"  LOGBOX,CP6,CP10
 SG_ Fbk_Overlay : 60|2@1+ (1,0) [0|3] "-"  LOGBOX,CP6,CP10
 SG_ Fbk_CameraCfg_Menu : 62|2@1+ (1,0) [0|3] "-"  LOGBOX,CP6,CP10

BO_ 2558605089 BC_2_CP_FBK_2: 8 BC
 SG_ Fbk_NBC_Menu : 46|2@1+ (1,0) [0|3] "-"  LOGBOX,CP6,CP10
 SG_ Fbk_Mask : 44|2@1+ (1,0) [0|3] "-"  LOGBOX,CP6,CP10
 SG_ Fbk_NBC_Ventilation_Low : 34|2@1+ (1,0) [0|3] "-"  LOGBOX,CP6,CP10
 SG_ Fbk_NBC_Ventilation_Fast : 36|2@1+ (1,0) [0|3] "-"  LOGBOX,CP6,CP10
 SG_ Fbk_NBC_FilterMode : 32|2@1+ (1,0) [0|3] "-"  LOGBOX,CP6,CP10
 SG_ Fbk_MechParkingBrake : 12|2@1+ (1,0) [0|3] "-"  LOGBOX,CP6,CP10
 SG_ Fbk_Retarder_Up : 4|2@1+ (1,0) [0|3] "-"  LOGBOX,CP6,CP10
 SG_ Fbk_Retarder_OnOff : 0|2@1+ (1,0) [0|3] "-"  LOGBOX,CP6,CP10
 SG_ Fbk_Retarder_Down : 2|2@1+ (1,0) [0|3] "-"  LOGBOX,CP6,CP10
 SG_ Fbk_CTIS_Menu : 30|2@1+ (1,0) [0|3] "-"  LOGBOX,CP6,CP10
 SG_ Fbk_Retarder_Menu : 14|2@1+ (1,0) [0|3] "-"  LOGBOX,CP6,CP10
 SG_ Fbk_CTIS_Check : 28|2@1+ (1,0) [0|3] "-"  LOGBOX,CP6,CP10
 SG_ Fbk_CTIS_Load : 26|2@1+ (1,0) [0|3] "-"  LOGBOX,CP6,CP10
 SG_ Fbk_CTIS_Emergency : 24|2@1+ (1,0) [0|3] "-"  LOGBOX,CP6,CP10
 SG_ Fbk_CTIS_Sand : 22|2@1+ (1,0) [0|3] "-"  LOGBOX,CP6,CP10
 SG_ Fbk_CTIS_Track : 20|2@1+ (1,0) [0|3] "-"  LOGBOX,CP6,CP10
 SG_ Fbk_CTIS_Road : 18|2@1+ (1,0) [0|3] "-"  LOGBOX,CP6,CP10
 SG_ Fbk_CTIS_ON : 16|2@1+ (1,0) [0|3] "-"  LOGBOX,CP6,CP10
 SG_ _nu_Fbk_Not_Used_2_06 : 6|2@1+ (1,0) [0|3] "-"  LOGBOX
 SG_ _nu_Fbk_Not_Used_2_08 : 8|2@1+ (1,0) [0|3] "-"  LOGBOX
 SG_ _nu_Fbk_Not_Used_2_10 : 10|2@1+ (1,0) [0|3] "-"  LOGBOX
 SG_ _nu_Fbk_Not_Used_2_38 : 38|2@1+ (1,0) [0|3] "-"  LOGBOX
 SG_ Fbk_NBCReset : 40|2@1+ (1,0) [0|3] "-"  LOGBOX,CP6,CP10
 SG_ _nu_Fbk_Not_Used_2_42 : 42|2@1+ (1,0) [0|3] "-"  LOGBOX
 SG_ _nu_Fbk_Not_Used_2_48 : 48|2@1+ (1,0) [0|3] "-"  LOGBOX
 SG_ _nu_Fbk_Not_Used_2_50 : 50|2@1+ (1,0) [0|3] "-"  LOGBOX
 SG_ _nu_Fbk_Not_Used_2_52 : 52|2@1+ (1,0) [0|3] "-"  LOGBOX
 SG_ _nu_Fbk_Not_Used_2_54 : 54|2@1+ (1,0) [0|3] "-"  LOGBOX
 SG_ _nu_Fbk_Not_Used_2_56 : 56|2@1+ (1,0) [0|3] "-"  LOGBOX
 SG_ _nu_Fbk_Not_Used_2_58 : 58|2@1+ (1,0) [0|3] "-"  LOGBOX
 SG_ _nu_Fbk_Not_Used_2_60 : 60|2@1+ (1,0) [0|3] "-"  LOGBOX
 SG_ _nu_Fbk_Not_Used_2_62 : 62|2@1+ (1,0) [0|3] "-"  LOGBOX

BO_ 2558539553 BC_2_CP_FBK_1: 8 BC
 SG_ Fbk_Emergency_Blinker : 0|2@1+ (1,0) [0|3] "-"  LOGBOX,CP6,CP10
 SG_ Fbk_Engine_Aux_Heater : 20|2@1+ (1,0) [0|3] "-"  LOGBOX,CP6,CP10
 SG_ Fbk_Driveline_Menu : 62|2@1+ (1,0) [0|3] "-"  LOGBOX,CP6,CP10
 SG_ Fbk_Aux_Menu : 30|2@1+ (1,0) [0|3] "-"  LOGBOX,CP6,CP10
 SG_ Fbk_Light_Menu : 14|2@1+ (1,0) [0|3] "-"  LOGBOX,CP6,CP10
 SG_ Fbk_Four_Axle : 52|2@1+ (1,0) [0|3] "-"  LOGBOX,CP6,CP10
 SG_ Fbk_Lock_Diff : 50|2@1+ (1,0) [0|3] "-"  LOGBOX,CP6,CP10
 SG_ Fbk_All_Wheel_Drive : 48|2@1+ (1,0) [0|3] "-"  LOGBOX,CP6,CP10
 SG_ Fbk_Ford_Mode : 22|2@1+ (1,0) [0|3] "-"  LOGBOX,CP6,CP10
 SG_ Fbk_Bilge_Pump_EngineBay : 24|2@1+ (1,0) [0|3] "-"  LOGBOX,CP6,CP10
 SG_ Fbk_Dust_Fan : 16|2@1+ (1,0) [0|3] "-"  LOGBOX,CP6,CP10
 SG_ Fbk_Warlight_B2 : 12|2@1+ (1,0) [0|3] "-"  LOGBOX,CP6,CP10
 SG_ Fbk_Warlight_B1 : 10|2@1+ (1,0) [0|3] "-"  LOGBOX,CP6,CP10
 SG_ Fbk_Low_Beam_Light : 6|2@1+ (1,0) [0|3] "-"  LOGBOX,CP6,CP10
 SG_ Fbk_Marker_Light : 4|2@1+ (1,0) [0|3] "-"  LOGBOX,CP6,CP10
 SG_ _nu_Fbk_Not_Used_1_02 : 2|2@1+ (1,0) [0|3] "-"  LOGBOX
 SG_ _nu_Fbk_Not_Used_1_08 : 8|2@1+ (1,0) [0|3] "-"  LOGBOX
 SG_ Fbk_Fuel_Pump : 18|2@1+ (1,0) [0|3] "-"  LOGBOX,CP6,CP10
 SG_ _nu_Fbk_Not_Used_1_26 : 26|2@1+ (1,0) [0|3] "-"  LOGBOX,CP6,CP10
 SG_ Fbk_TripReset : 28|2@1+ (1,0) [0|3] "-"  LOGBOX,CP6,CP10
 SG_ _nu_Fbk_Not_Used_1_32 : 32|2@1+ (1,0) [0|3] "-"  LOGBOX
 SG_ _nu_Fbk_Not_Used_1_34 : 34|2@1+ (1,0) [0|3] "-"  LOGBOX
 SG_ _nu_Fbk_Not_Used_1_36 : 36|2@1+ (1,0) [0|3] "-"  LOGBOX
 SG_ _nu_Fbk_Not_Used_1_38 : 38|2@1+ (1,0) [0|3] "-"  LOGBOX
 SG_ _nu_Fbk_Not_Used_1_40 : 40|2@1+ (1,0) [0|3] "-"  LOGBOX
 SG_ _nu_Fbk_Not_Used_1_42 : 42|2@1+ (1,0) [0|3] "-"  LOGBOX
 SG_ _nu_Fbk_Not_Used_1_44 : 44|2@1+ (1,0) [0|3] "-"  LOGBOX
 SG_ _nu_Fbk_Not_Used_1_46 : 46|2@1+ (1,0) [0|3] "-"  LOGBOX
 SG_ _nu_Fbk_Not_Used_1_54 : 54|2@1+ (1,0) [0|3] "-"  LOGBOX
 SG_ _nu_Fbk_Not_Used_1_56 : 56|2@1+ (1,0) [0|3] "-"  LOGBOX
 SG_ _nu_Fbk_Not_Used_1_58 : 58|2@1+ (1,0) [0|3] "-"  LOGBOX
 SG_ _nu_Fbk_Not_Used_1_60 : 60|2@1+ (1,0) [0|3] "-"  LOGBOX

BO_ 2558599447 CP6_2_BC_2: 8 CP6
 SG_ Btn_Clima_Vent_Up_CP6 : 19|1@1+ (1,0) [0|1] "-"  HVAC,LOGBOX,BC
 SG_ Btn_Clima_Vent_Down_CP6 : 18|1@1+ (1,0) [0|1] "-"  HVAC,LOGBOX,BC
 SG_ Btn_Clima_Temp_Up_CP6 : 21|1@1+ (1,0) [0|1] "-"  HVAC,LOGBOX,BC
 SG_ Btn_Clima_Temp_Down_CP6 : 20|1@1+ (1,0) [0|1] "-"  HVAC,LOGBOX,BC
 SG_ Btn_Clima_ON_AUTO_MAN_CP6 : 16|1@1+ (1,0) [0|1] "-"  HVAC,LOGBOX,BC
 SG_ Btn_Clima_Compressor_CP6 : 17|1@1+ (1,0) [0|1] "-"  HVAC,LOGBOX,BC
 SG_ Btn_CrewAreaHeater_CP6 : 22|1@1+ (1,0) [0|1] "-"  LOGBOX,BC
 SG_ Btn_NBC_Ventilation_Low_CP6 : 1|1@1+ (1,0) [0|1] "-"  LOGBOX,BC
 SG_ Btn_NBC_Ventilation_Fast_CP6 : 2|1@1+ (1,0) [0|1] "-"  LOGBOX,BC
 SG_ Btn_NBC_FilterMode_CP6 : 0|1@1+ (1,0) [0|1] "-"  LOGBOX,BC
 SG_ Btn_Mask_CP6 : 6|1@1+ (1,0) [0|1] "-"  HVAC,LOGBOX,BC
 SG_ Btn_NUC_Enable_CP6 : 37|1@1+ (1,0) [0|1] "-"  LOGBOX
 SG_ Btn_Polarity_CP6 : 35|1@1+ (1,0) [0|1] "-"  LOGBOX
 SG_ Btn_ROI_CP6 : 34|1@1+ (1,0) [0|1] "-"  LOGBOX
 SG_ Btn_TYPE_CP6 : 33|1@1+ (1,0) [0|1] "-"  LOGBOX
 SG_ Btn_ChangeView_CP6 : 32|1@1+ (1,0) [0|1] "-"  LOGBOX
 SG_ _nu_Btn_1_03_CP6 : 3|1@1+ (1,0) [0|1] "-"  LOGBOX
 SG_ Btn_NBCReset_CP6 : 4|1@1+ (1,0) [0|1] "-"  LOGBOX,BC
 SG_ _nu_Btn_1_05_CP6 : 5|1@1+ (1,0) [0|1] "-"  LOGBOX
 SG_ _nu_Btn_1_07_CP6 : 7|1@1+ (1,0) [0|1] "-"  LOGBOX
 SG_ _nu_Btn_1_08_CP6 : 8|1@1+ (1,0) [0|1] "-"  LOGBOX
 SG_ _nu_Btn_1_09_CP6 : 9|1@1+ (1,0) [0|1] "-"  LOGBOX
 SG_ _nu_Btn_1_10_CP6 : 10|1@1+ (1,0) [0|1] "-"  LOGBOX
 SG_ _nu_Btn_1_11_CP6 : 11|1@1+ (1,0) [0|1] "-"  LOGBOX
 SG_ _nu_Btn_1_12_CP6 : 12|1@1+ (1,0) [0|1] "-"  LOGBOX
 SG_ _nu_Btn_1_13_CP6 : 13|1@1+ (1,0) [0|1] "-"  LOGBOX
 SG_ _nu_Btn_1_14_CP6 : 14|1@1+ (1,0) [0|1] "-"  LOGBOX
 SG_ _nu_Btn_1_15_CP6 : 15|1@1+ (1,0) [0|1] "-"  LOGBOX
 SG_ _nu_Btn_1_23_CP6 : 23|1@1+ (1,0) [0|1] "-"  LOGBOX
 SG_ _nu_Btn_1_24_CP6 : 24|1@1+ (1,0) [0|1] "-"  LOGBOX
 SG_ _nu_Btn_1_25_CP6 : 25|1@1+ (1,0) [0|1] "-"  LOGBOX
 SG_ _nu_Btn_1_26_CP6 : 26|1@1+ (1,0) [0|1] "-"  LOGBOX
 SG_ _nu_Btn_1_27_CP6 : 27|1@1+ (1,0) [0|1] "-"  LOGBOX
 SG_ _nu_Btn_1_28_CP6 : 28|1@1+ (1,0) [0|1] "-"  LOGBOX
 SG_ _nu_Btn_1_29_CP6 : 29|1@1+ (1,0) [0|1] "-"  LOGBOX
 SG_ _nu_Btn_1_30_CP6 : 30|1@1+ (1,0) [0|1] "-"  LOGBOX
 SG_ _nu_Btn_1_31_CP6 : 31|1@1+ (1,0) [0|1] "-"  LOGBOX
 SG_ Btn_PerimetralVision_CP6 : 36|1@1+ (1,0) [0|1] "-"  LOGBOX
 SG_ Btn_SelMonitor_CP6 : 40|1@1+ (1,0) [0|1] "-"  LOGBOX
 SG_ _nu_Btn_1_39_CP6 : 39|1@1+ (1,0) [0|1] "-"  LOGBOX
 SG_ Btn_Sights_Washer_CP6 : 38|1@1+ (1,0) [0|1] "-"  LOGBOX,BC
 SG_ Btn_SelTlc_CP6 : 41|1@1+ (1,0) [0|1] "-"  LOGBOX
 SG_ Btn_SelCfg_CP6 : 42|1@1+ (1,0) [0|1] "-"  LOGBOX
 SG_ Btn_SaveCfg_CP6 : 43|1@1+ (1,0) [0|1] "-"  LOGBOX
 SG_ Btn_RestoreCfg_CP6 : 44|1@1+ (1,0) [0|1] "-"  LOGBOX
 SG_ Btn_HeaterTlc_CP6 : 45|1@1+ (1,0) [0|1] "-"  LOGBOX
 SG_ Btn_Overlay_CP6 : 46|1@1+ (1,0) [0|1] "-"  LOGBOX
 SG_ _nu_Btn_1_47_CP6 : 47|1@1+ (1,0) [0|1] "-"  LOGBOX
 SG_ _nu_Btn_1_48_CP6 : 48|1@1+ (1,0) [0|1] "-"  LOGBOX
 SG_ _nu_Btn_1_49_CP6 : 49|1@1+ (1,0) [0|1] "-"  LOGBOX
 SG_ _nu_Btn_1_50_CP6 : 50|1@1+ (1,0) [0|1] "-"  LOGBOX
 SG_ _nu_Btn_1_51_CP6 : 51|1@1+ (1,0) [0|1] "-"  LOGBOX
 SG_ _nu_Btn_1_52_CP6 : 52|1@1+ (1,0) [0|1] "-"  LOGBOX
 SG_ _nu_Btn_1_53_CP6 : 53|1@1+ (1,0) [0|1] "-"  LOGBOX
 SG_ _nu_Btn_1_54_CP6 : 54|1@1+ (1,0) [0|1] "-"  LOGBOX
 SG_ _nu_Btn_1_55_CP6 : 55|1@1+ (1,0) [0|1] "-"  LOGBOX
 SG_ _nu_Btn_1_56_CP6 : 56|1@1+ (1,0) [0|1] "-"  LOGBOX
 SG_ _nu_Btn_1_57_CP6 : 57|1@1+ (1,0) [0|1] "-"  LOGBOX
 SG_ _nu_Btn_1_58_CP6 : 58|1@1+ (1,0) [0|1] "-"  LOGBOX
 SG_ _nu_Btn_1_59_CP6 : 59|1@1+ (1,0) [0|1] "-"  LOGBOX
 SG_ _nu_Btn_1_60_CP6 : 60|1@1+ (1,0) [0|1] "-"  LOGBOX
 SG_ _nu_Btn_1_61_CP6 : 61|1@1+ (1,0) [0|1] "-"  LOGBOX
 SG_ _nu_Btn_1_62_CP6 : 62|1@1+ (1,0) [0|1] "-"  LOGBOX
 SG_ _nu_Btn_1_63_CP6 : 63|1@1+ (1,0) [0|1] "-"  LOGBOX

BO_ 2558533911 CP6_2_BC_1: 8 CP6
 SG_ Btn_EngineHeater_CP6 : 10|1@1+ (1,0) [0|1] "-"  LOGBOX,BC
 SG_ Btn_ParkingBrake_CP6 : 38|1@1+ (1,0) [0|1] "-"  LOGBOX,BC
 SG_ Btn_CTIS_Check_CP6 : 46|1@1+ (1,0) [0|1] "-"  LOGBOX,BC
 SG_ Btn_CTIS_Load_CP6 : 45|1@1+ (1,0) [0|1] "-"  LOGBOX,BC
 SG_ Btn_CTIS_Emergency_CP6 : 44|1@1+ (1,0) [0|1] "-"  LOGBOX,BC
 SG_ Btn_CTIS_Sand_CP6 : 43|1@1+ (1,0) [0|1] "-"  LOGBOX,BC
 SG_ Btn_CTIS_Track_CP6 : 42|1@1+ (1,0) [0|1] "-"  LOGBOX,BC
 SG_ Btn_CTIS_Road_Cp6 : 41|1@1+ (1,0) [0|1] "-"  LOGBOX,BC
 SG_ Btn_CTIS_ON_CP6 : 40|1@1+ (1,0) [0|1] "-"  LOGBOX,BC
 SG_ Btn_Retarder_Down_CP6 : 34|1@1+ (1,0) [0|1] "-"  LOGBOX,BC
 SG_ Btn_Retarder_Up_CP6 : 33|1@1+ (1,0) [0|1] "-"  LOGBOX,BC
 SG_ Btn_Retarder_Off_CP6 : 32|1@1+ (1,0) [0|1] "-"  LOGBOX,BC
 SG_ Btn_4th_Steering_Axle_CP6 : 26|1@1+ (1,0) [0|1] "-"  LOGBOX,BC
 SG_ Btn_Lock_Front_Diff_CP6 : 25|1@1+ (1,0) [0|1] "-"  LOGBOX,BC
 SG_ Btn_All_Wheel_Drive_CP6 : 24|1@1+ (1,0) [0|1] "-"  LOGBOX,BC
 SG_ Btn_Ford_Mode_CP6 : 11|1@1+ (1,0) [0|1] "-"  LOGBOX,BC
 SG_ Btn_Bilge_Pump_EngineBay_CP6 : 12|1@1+ (1,0) [0|1] "-"  LOGBOX,BC
 SG_ Btn_TripReset_CP6 : 14|1@1+ (1,0) [0|1] "-"  LOGBOX,BC
 SG_ Btn_Dust_Fan_CP6 : 8|1@1+ (1,0) [0|1] "-"  LOGBOX,BC
 SG_ Btn_FuelPumpCP6 : 9|1@1+ (1,0) [0|1] "-"  LOGBOX,BC
 SG_ Btn_Warlight_B2_CP6 : 6|1@1+ (1,0) [0|1] "-"  LOGBOX,BC
 SG_ Btn_Warlight_B1_CP6 : 5|1@1+ (1,0) [0|1] "-"  LOGBOX,BC
 SG_ Btn_Low_Beam_Light_CP6 : 3|1@1+ (1,0) [0|1] "-"  LOGBOX,BC
 SG_ Btn_Marker_Light_CP6 : 2|1@1+ (1,0) [0|1] "-"  LOGBOX,BC
 SG_ Btn_Emergency_Blinker_CP6 : 0|1@1+ (1,0) [0|1] "-"  LOGBOX,BC
 SG_ _nu_Btn_2_01_CP6 : 1|1@1+ (1,0) [0|1] "-"  LOGBOX
 SG_ _nu_Btn_2_04_CP6 : 4|1@1+ (1,0) [0|1] "-"  LOGBOX
 SG_ _nu_Btn_2_07_CP6 : 7|1@1+ (1,0) [0|1] "-"  LOGBOX
 SG_ Btn_Change_h_km_CP6 : 13|1@1+ (1,0) [0|1] "-"  LOGBOX,BC
 SG_ _nu_Btn_2_15_CP6 : 15|1@1+ (1,0) [0|1] "-"  LOGBOX
 SG_ _nu_Btn_2_16_CP6 : 16|1@1+ (1,0) [0|1] "-"  LOGBOX
 SG_ _nu_Btn_2_17_CP6 : 17|1@1+ (1,0) [0|1] "-"  LOGBOX
 SG_ _nu_Btn_2_18_CP6 : 18|1@1+ (1,0) [0|1] "-"  LOGBOX
 SG_ _nu_Btn_2_19_CP6 : 19|1@1+ (1,0) [0|1] "-"  LOGBOX
 SG_ _nu_Btn_2_20_CP6 : 20|1@1+ (1,0) [0|1] "-"  LOGBOX
 SG_ _nu_Btn_2_21_CP6 : 21|1@1+ (1,0) [0|1] "-"  LOGBOX
 SG_ _nu_Btn_2_22_CP6 : 22|1@1+ (1,0) [0|1] "-"  LOGBOX
 SG_ _nu_Btn_2_23_CP6 : 23|1@1+ (1,0) [0|1] "-"  LOGBOX
 SG_ _nu_Btn_2_27_CP6 : 27|1@1+ (1,0) [0|1] "-"  LOGBOX
 SG_ _nu_Btn_2_28_CP6 : 28|1@1+ (1,0) [0|1] "-"  LOGBOX
 SG_ _nu_Btn_2_29_CP6 : 29|1@1+ (1,0) [0|1] "-"  LOGBOX
 SG_ _nu_Btn_2_30_CP6 : 30|1@1+ (1,0) [0|1] "-"  LOGBOX
 SG_ _nu_Btn_2_31_CP6 : 31|1@1+ (1,0) [0|1] "-"  LOGBOX
 SG_ _nu_Btn_2_35_CP6 : 35|1@1+ (1,0) [0|1] "-"  LOGBOX
 SG_ _nu_Btn_2_36_CP6 : 36|1@1+ (1,0) [0|1] "-"  LOGBOX
 SG_ _nu_Btn_2_37_CP6 : 37|1@1+ (1,0) [0|1] "-"  LOGBOX
 SG_ _nu_Btn_2_39_CP6 : 39|1@1+ (1,0) [0|1] "-"  LOGBOX
 SG_ _nu_Btn_2_47_CP6 : 47|1@1+ (1,0) [0|1] "-"  LOGBOX
 SG_ _nu_Btn_2_48_CP6 : 48|1@1+ (1,0) [0|1] "-"  LOGBOX
 SG_ _nu_Btn_2_49_CP6 : 49|1@1+ (1,0) [0|1] "-"  LOGBOX
 SG_ _nu_Btn_2_50_CP6 : 50|1@1+ (1,0) [0|1] "-"  LOGBOX
 SG_ _nu_Btn_2_51_CP6 : 51|1@1+ (1,0) [0|1] "-"  LOGBOX
 SG_ _nu_Btn_2_52_CP6 : 52|1@1+ (1,0) [0|1] "-"  LOGBOX
 SG_ _nu_Btn_2_53_CP6 : 53|1@1+ (1,0) [0|1] "-"  LOGBOX
 SG_ _nu_Btn_2_54_CP6 : 54|1@1+ (1,0) [0|1] "-"  LOGBOX
 SG_ _nu_Btn_2_55_CP6 : 55|1@1+ (1,0) [0|1] "-"  LOGBOX
 SG_ _nu_Btn_2_56_CP6 : 56|1@1+ (1,0) [0|1] "-"  LOGBOX
 SG_ _nu_Btn_2_57_CP6 : 57|1@1+ (1,0) [0|1] "-"  LOGBOX
 SG_ _nu_Btn_2_58_CP6 : 58|1@1+ (1,0) [0|1] "-"  LOGBOX
 SG_ _nu_Btn_2_59_CP6 : 59|1@1+ (1,0) [0|1] "-"  LOGBOX
 SG_ _nu_Btn_2_60_CP6 : 60|1@1+ (1,0) [0|1] "-"  LOGBOX
 SG_ _nu_Btn_2_61_CP6 : 61|1@1+ (1,0) [0|1] "-"  LOGBOX
 SG_ _nu_Btn_2_62_CP6 : 62|1@1+ (1,0) [0|1] "-"  LOGBOX
 SG_ _nu_Btn_2_63_CP6 : 63|1@1+ (1,0) [0|1] "-"  LOGBOX

BO_ 2558599479 CP10_2_BC_2: 8 CP10
 SG_ Btn_NBC_Ventilation_Low_CP10 : 1|1@1+ (1,0) [0|1] "-"  LOGBOX,BC
 SG_ Btn_NBC_Ventilation_Fast_CP10 : 2|1@1+ (1,0) [0|1] "-"  LOGBOX,BC
 SG_ Btn_NBC_FilterMode_CP10 : 0|1@1+ (1,0) [0|1] "-"  LOGBOX,BC
 SG_ Btn_Mask_CP10 : 6|1@1+ (1,0) [0|1] "-"  HVAC,LOGBOX,BC
 SG_ Btn_CrewAreaHeater_CP10 : 22|1@1+ (1,0) [0|1] "-"  LOGBOX,BC
 SG_ Btn_Clima_Vent_Up_CP10 : 19|1@1+ (1,0) [0|1] "-"  HVAC,LOGBOX,BC
 SG_ Btn_Clima_Vent_Down_CP10 : 18|1@1+ (1,0) [0|1] "-"  HVAC,LOGBOX,BC
 SG_ Btn_Clima_Temp_Up_CP10 : 21|1@1+ (1,0) [0|1] "-"  HVAC,LOGBOX,BC
 SG_ Btn_Clima_Temp_Down_CP10 : 20|1@1+ (1,0) [0|1] "-"  HVAC,LOGBOX,BC
 SG_ Btn_Clima_ON_AUTO_MAN_CP10 : 16|1@1+ (1,0) [0|1] "-"  HVAC,LOGBOX,BC
 SG_ Btn_Clima_Compressor_CP10 : 17|1@1+ (1,0) [0|1] "-"  HVAC,LOGBOX,BC
 SG_ Btn_NUC_Enable_CP10 : 37|1@1+ (1,0) [0|1] "-"  LOGBOX,BC
 SG_ Btn_Polarity_CP10 : 35|1@1+ (1,0) [0|1] "-"  LOGBOX,BC
 SG_ Btn_ROI_CP10 : 34|1@1+ (1,0) [0|1] "-"  LOGBOX,BC
 SG_ Btn_TYPE_CP10 : 33|1@1+ (1,0) [0|1] "-"  LOGBOX,BC
 SG_ Btn_ChangeView_CP10 : 32|1@1+ (1,0) [0|1] "-"  LOGBOX,BC
 SG_ _nu_Btn_1_03_CP10 : 3|1@1+ (1,0) [0|1] "-"  LOGBOX
 SG_ Btn_NBCReset_CP10 : 4|1@1+ (1,0) [0|1] "-"  LOGBOX,BC
 SG_ _nu_Btn_1_05_CP10 : 5|1@1+ (1,0) [0|1] "-"  LOGBOX
 SG_ _nu_Btn_1_07_CP10 : 7|1@1+ (1,0) [0|1] "-"  LOGBOX
 SG_ _nu_Btn_1_08_CP10 : 8|1@1+ (1,0) [0|1] "-"  LOGBOX
 SG_ _nu_Btn_1_09_CP10 : 9|1@1+ (1,0) [0|1] "-"  LOGBOX
 SG_ _nu_Btn_1_10_CP10 : 10|1@1+ (1,0) [0|1] "-"  LOGBOX
 SG_ _nu_Btn_1_11_CP10 : 11|1@1+ (1,0) [0|1] "-"  LOGBOX
 SG_ _nu_Btn_1_12_CP10 : 12|1@1+ (1,0) [0|1] "-"  LOGBOX
 SG_ _nu_Btn_1_13_CP10 : 13|1@1+ (1,0) [0|1] "-"  LOGBOX
 SG_ _nu_Btn_1_14_CP10 : 14|1@1+ (1,0) [0|1] "-"  LOGBOX
 SG_ _nu_Btn_1_15_CP10 : 15|1@1+ (1,0) [0|1] "-"  LOGBOX
 SG_ _nu_Btn_1_23_CP10 : 23|1@1+ (1,0) [0|1] "-"  LOGBOX
 SG_ _nu_Btn_1_24_CP10 : 24|1@1+ (1,0) [0|1] "-"  LOGBOX
 SG_ _nu_Btn_1_25_CP10 : 25|1@1+ (1,0) [0|1] "-"  LOGBOX
 SG_ _nu_Btn_1_26_CP10 : 26|1@1+ (1,0) [0|1] "-"  LOGBOX
 SG_ _nu_Btn_1_27_CP10 : 27|1@1+ (1,0) [0|1] "-"  LOGBOX
 SG_ _nu_Btn_1_28_CP10 : 28|1@1+ (1,0) [0|1] "-"  LOGBOX
 SG_ _nu_Btn_1_29_CP10 : 29|1@1+ (1,0) [0|1] "-"  LOGBOX
 SG_ _nu_Btn_1_30_CP10 : 30|1@1+ (1,0) [0|1] "-"  LOGBOX
 SG_ _nu_Btn_1_31_CP10 : 31|1@1+ (1,0) [0|1] "-"  LOGBOX
 SG_ Btn_PerimetralVision_CP10 : 36|1@1+ (1,0) [0|1] "-"  LOGBOX,BC
 SG_ Btn_SelMonitor_CP10 : 40|1@1+ (1,0) [0|1] "-"  LOGBOX,BC
 SG_ _nu_Btn_1_39_CP10 : 39|1@1+ (1,0) [0|1] "-"  LOGBOX
 SG_ Btn_Sights_Washer_CP10 : 38|1@1+ (1,0) [0|1] "-"  LOGBOX,BC
 SG_ Btn_SelTlc_CP10 : 41|1@1+ (1,0) [0|1] "-"  LOGBOX,BC
 SG_ Btn_SelCfg_CP10 : 42|1@1+ (1,0) [0|1] "-"  LOGBOX,BC
 SG_ Btn_SaveCfg_CP10 : 43|1@1+ (1,0) [0|1] "-"  LOGBOX,BC
 SG_ Btn_RestoreCfg_CP10 : 44|1@1+ (1,0) [0|1] "-"  LOGBOX,BC
 SG_ Btn_HeaterTlc_CP10 : 45|1@1+ (1,0) [0|1] "-"  LOGBOX
 SG_ Btn_Overlay_CP10 : 46|1@1+ (1,0) [0|1] "-"  LOGBOX
 SG_ _nu_Btn_1_47_CP10 : 47|1@1+ (1,0) [0|1] "-"  LOGBOX
 SG_ _nu_Btn_1_48_CP10 : 48|1@1+ (1,0) [0|1] "-"  LOGBOX
 SG_ _nu_Btn_1_49_CP10 : 49|1@1+ (1,0) [0|1] "-"  LOGBOX
 SG_ _nu_Btn_1_50_CP10 : 50|1@1+ (1,0) [0|1] "-"  LOGBOX
 SG_ _nu_Btn_1_51_CP10 : 51|1@1+ (1,0) [0|1] "-"  LOGBOX
 SG_ _nu_Btn_1_52_CP10 : 52|1@1+ (1,0) [0|1] "-"  LOGBOX
 SG_ _nu_Btn_1_53_CP10 : 53|1@1+ (1,0) [0|1] "-"  LOGBOX
 SG_ _nu_Btn_1_54_CP10 : 54|1@1+ (1,0) [0|1] "-"  LOGBOX
 SG_ _nu_Btn_1_55_CP10 : 55|1@1+ (1,0) [0|1] "-"  LOGBOX
 SG_ _nu_Btn_1_56_CP10 : 56|1@1+ (1,0) [0|1] "-"  LOGBOX
 SG_ _nu_Btn_1_57_CP10 : 57|1@1+ (1,0) [0|1] "-"  LOGBOX
 SG_ _nu_Btn_1_58_CP10 : 58|1@1+ (1,0) [0|1] "-"  LOGBOX
 SG_ _nu_Btn_1_59_CP10 : 59|1@1+ (1,0) [0|1] "-"  LOGBOX
 SG_ _nu_Btn_1_60_CP10 : 60|1@1+ (1,0) [0|1] "-"  LOGBOX
 SG_ _nu_Btn_1_61_CP10 : 61|1@1+ (1,0) [0|1] "-"  LOGBOX
 SG_ _nu_Btn_1_62_CP10 : 62|1@1+ (1,0) [0|1] "-"  LOGBOX
 SG_ _nu_Btn_1_63_CP10 : 63|1@1+ (1,0) [0|1] "-"  LOGBOX

CM_ "Secondary data bus";
CM_ BU_ RUR "Remote Unit Rear (MUX slave)";
CM_ BU_ RUF "Remote Unit Front (MUX slave)";
CM_ BU_ LOGBOX "Logbox";
CM_ BU_ HVAC "Air Conditioning Can Control System";
CM_ BU_ CP6 "Control Panel 6''";
CM_ BU_ CP10 "Control Panel 10''";
CM_ BU_ RUC "Remote Unit Central (MUX slave)";
CM_ BU_ BC "Body Computer";
CM_ BU_ BMS1_SDB "BMS1 (Extra battery)";
CM_ BU_ BMS2_SDB "BMS2 (Extra battery)";
CM_ BU_ BMS0_SDB "BMSx (Normal or Extra battery)";
CM_ BU_ _TESTER "Strumento di diagnosi per configurazione telecamere.
Potrà essere sostituito dal BC.";
CM_ BU_ NC_SENSOR "Nuclear and Chemical sensor";
CM_ BU_ IVS "Switch Video System";
CM_ BO_ 2559194913 "Message used for collecting all the batteries information";
CM_ SG_ 2559194913 Generic_Alarm "The signal shall be set by the BODY to define the generic battery alarm.
";
CM_ SG_ 2559194913 Battery_Network "The signal shall be set by the BODY to define the battery network
";
CM_ SG_ 2559194913 Temperature_Alarm "The signal shall be set by the BODY to define the temperature alarm.
";
CM_ SG_ 2559194913 Status_of_Charge "This parameter contains the ratio of the remaining capacity of the battery to the full capacity expressed as a percentage.";
CM_ SG_ 2559194913 Status_of_Health "This parameter contains a value relating to the state of health of the battery based on defined thresholds of the ratio of full capacity to design capacity.";
CM_ SG_ 2559194913 Battery_Number "The signal shall be set by the BODY to define the battery position in the network";
CM_ SG_ 2559194913 Battery_serial_number "This parameter contains the manufactured serial number of the battery. The lowest 21 bits of this 24 bit serial number are also used in the J1939 NAME – see 2.1.";
CM_ BO_ 2558656281 "Message used for the HVAC temperatures";
CM_ SG_ 2558656281 HVAC_VehicleAverageTemp "Vehicle average temperature (HVAC air input);";
CM_ SG_ 2558656281 HVAC_OutputAverageTemp "Output average temperature (HVAC air output “ARIA TRATTATA”);";
CM_ SG_ 2558656281 HVAC_MaskAverageTemp "Masks average temperature (HVAC mask air output”);";
CM_ SG_ 2558656281 HVAC_EvaporatorAverageTemp "Evaporator average temperature (“ARIA SCAMBIATORE”);";
CM_ SG_ 2559246113 u8_Debug_7 "DEBUG variable 7";
CM_ SG_ 2559246113 u8_Debug_6 "DEBUG variable 6";
CM_ SG_ 2559246113 u8_Debug_5 "DEBUG variable 5";
CM_ SG_ 2559246113 u8_Debug_4 "DEBUG variable 4";
CM_ SG_ 2559246113 u8_Debug_3 "DEBUG variable 3";
CM_ SG_ 2559246113 u8_Debug_2 "DEBUG variable 2";
CM_ SG_ 2559246113 u8_Debug_1 "DEBUG variable 1";
CM_ SG_ 2559246113 u8_Debug_0 "DEBUG variable 0";
CM_ BO_ 2559129377 "TRIP PARTIAL";
CM_ SG_ 2559129377 Partial_km "The signal shall be set by the BODY to define the Partial Mileage.
SPN 918";
CM_ SG_ 2559129377 Partial_h "The signal shall be set by the BODY to define the Partial Engine Hours.";
CM_ BO_ 2559063841 "Message used for collecting all the fuel tank information";
CM_ SG_ 2559063841 Lamp_Fuel_TOT_LvlLow "The signal shall be set by the BODY to define the Total Tank Fuel Level Low Alarm status.";
CM_ SG_ 2559063841 Fuel_TOT_Level "The signal shall be set by the BODY to define the Total Fuel Level current filtered value [%].";
CM_ SG_ 2559063841 Lamp_Fuel_REAR_RIGHT_LvlLow "The signal shall be set by the BODY to define the Rear RightTank Fuel Level Low Alarm status.";
CM_ SG_ 2559063841 Lamp_Fuel_REAR_LEFT_LvlLow "The signal shall be set by the BODY to define the Rear Left Tank Fuel Level Low Alarm status.";
CM_ SG_ 2559063841 Lamp_Fuel_FRONT_LvlLow "The signal shall be set by the BODY to define the Front Tank Fuel Level Low Alarm status.";
CM_ SG_ 2559063841 Lamp_Fuel_CENTRAL_LvlLow "The signal shall be set by the BODY to define the Central Tank Fuel Level Low Alarm status.";
CM_ SG_ 2559063841 Fuel_REAR_RIGHT_Level "The signal shall be set by the BODY to define the Rear Right Tank Fuel Level current filtered value [%].";
CM_ SG_ 2559063841 Fuel_REAR_LEFT_Level "The signal shall be set by the BODY to define the Rear Left Tank Fuel Level current filtered value [%].";
CM_ SG_ 2559063841 Fuel_FRONT_Level "The signal shall be set by the BODY to define the Front Tank Fuel Level current filtered value [%].";
CM_ SG_ 2559063841 Fuel_CENTRAL_Level "The signal shall be set by the BODY to define the Central Tank Fuel Level current filtered value [%].";
CM_ BO_ 2566834942 "Active diagnostic trouble codes";
CM_ SG_ 2566834942 SPN10_Low "SPN #10 (Conversion Version 4)";
CM_ SG_ 2566834942 SPN9_Low "SPN #9 (Conversion Version 4)";
CM_ SG_ 2566834942 SPN8_Low "SPN #8 (Conversion Version 4)";
CM_ SG_ 2566834942 SPN7_Low "SPN #7 (Conversion Version 4)";
CM_ SG_ 2566834942 SPN6_Low "SPN #6 (Conversion Version 4)";
CM_ SG_ 2566834942 SPN5_Low "SPN #5 (Conversion Version 4)";
CM_ SG_ 2566834942 SPN4_Low "SPN #4 (Conversion Version 4)";
CM_ SG_ 2566834942 SPN3_Low "SPN #3 (Conversion Version 4)";
CM_ SG_ 2566834942 SPN2_Low "SPN #2 (Conversion Version 4)";
CM_ SG_ 2566834942 FailureModeIdentifier10 "The FMI defines the type of failure detected in the subsystem identified by an SPN.";
CM_ SG_ 2566834942 FailureModeIdentifier9 "The FMI defines the type of failure detected in the subsystem identified by an SPN.";
CM_ SG_ 2566834942 FailureModeIdentifier8 "The FMI defines the type of failure detected in the subsystem identified by an SPN.";
CM_ SG_ 2566834942 FailureModeIdentifier7 "The FMI defines the type of failure detected in the subsystem identified by an SPN.";
CM_ SG_ 2566834942 FailureModeIdentifier6 "The FMI defines the type of failure detected in the subsystem identified by an SPN.";
CM_ SG_ 2566834942 FailureModeIdentifier5 "The FMI defines the type of failure detected in the subsystem identified by an SPN.";
CM_ SG_ 2566834942 FailureModeIdentifier4 "The FMI defines the type of failure detected in the subsystem identified by an SPN.";
CM_ SG_ 2566834942 FailureModeIdentifier3 "The FMI defines the type of failure detected in the subsystem identified by an SPN.";
CM_ SG_ 2566834942 FlashRedStopLamp "This parameter provides the capability to flash the RSL (SPN 3039).";
CM_ SG_ 2566834942 FlashProtectLamp "This parameter provides the capability to flash the engine protect lamp (SPN 3041).";
CM_ SG_ 2566834942 FlashMalfuncIndicatorLamp "This parameter provides the capability to flash the MIL (SPN 3038).";
CM_ SG_ 2566834942 FlashAmberWarningLamp "This parameter provides the capability to flash the AWL (SPN 3040). ";
CM_ SG_ 2566834942 MalfunctionIndicatorLampStatus "A lamp used to relay only emissions-related trouble code information.";
CM_ SG_ 2566834942 AmberWarningLampStatus "This lamp is used to relay trouble code information that is reporting a problem with the vehicle system but the vehicle neednot be immediately stopped.";
CM_ SG_ 2566834942 OccurenceCount1 "The 7 bit occurence count field contains the number of times a fault has gone from active to previously active.";
CM_ SG_ 2566834942 SPNConversionMethod1 "SPN Conversion Method";
CM_ SG_ 2566834942 FailureModeIdentifier1 "The FMI defines the type of failure detected in the subsystem identified by an SPN.";
CM_ SG_ 2566834942 SPN1_Low "SPN #1 (Conversion Version 4)";
CM_ SG_ 2566834942 RedStopLampState "This lamp is uesed to relay trouble code information that is of a severe enought condition that it warrants stopping the vehicle.";
CM_ SG_ 2566834942 ProtectLampStatus "This lamp is used to relay trouble code informatio that is reporting a problem with a vehicle system that is most probably not electronic subsystem related.";
CM_ SG_ 2566834942 FailureModeIdentifier2 "The FMI defines the type of failure detected in the subsystem identified by an SPN.";
CM_ SG_ 2566834942 SPNConversionMethod10 "SPN Conversion Method";
CM_ SG_ 2566834942 SPNConversionMethod9 "SPN Conversion Method";
CM_ SG_ 2566834942 SPNConversionMethod8 "SPN Conversion Method";
CM_ SG_ 2566834942 SPNConversionMethod7 "SPN Conversion Method";
CM_ SG_ 2566834942 SPNConversionMethod6 "SPN Conversion Method";
CM_ SG_ 2566834942 SPNConversionMethod5 "SPN Conversion Method";
CM_ SG_ 2566834942 SPNConversionMethod4 "SPN Conversion Method";
CM_ SG_ 2566834942 SPNConversionMethod3 "SPN Conversion Method";
CM_ SG_ 2566834942 SPNConversionMethod2 "SPN Conversion Method";
CM_ SG_ 2566834942 OccurenceCount10 "The 7 bit occurence count field contains the number of times a fault has gone from active to previously active.";
CM_ SG_ 2566834942 OccurenceCount9 "The 7 bit occurence count field contains the number of times a fault has gone from active to previously active.";
CM_ SG_ 2566834942 OccurenceCount8 "The 7 bit occurence count field contains the number of times a fault has gone from active to previously active.";
CM_ SG_ 2566834942 OccurenceCount7 "The 7 bit occurence count field contains the number of times a fault has gone from active to previously active.";
CM_ SG_ 2566834942 OccurenceCount6 "The 7 bit occurence count field contains the number of times a fault has gone from active to previously active.";
CM_ SG_ 2566834942 OccurenceCount5 "The 7 bit occurence count field contains the number of times a fault has gone from active to previously active.";
CM_ SG_ 2566834942 OccurenceCount4 "The 7 bit occurence count field contains the number of times a fault has gone from active to previously active.";
CM_ SG_ 2566834942 OccurenceCount3 "The 7 bit occurence count field contains the number of times a fault has gone from active to previously active.";
CM_ SG_ 2566834942 OccurenceCount2 "The 7 bit occurence count field contains the number of times a fault has gone from active to previously active.";
CM_ SG_ 2566834942 SPN10_High "SPN #10 (Conversion Version 4)";
CM_ SG_ 2566834942 SPN9_High "SPN #9 (Conversion Version 4)";
CM_ SG_ 2566834942 SPN8_High "SPN #8 (Conversion Version 4)";
CM_ SG_ 2566834942 SPN7_High "SPN #7 (Conversion Version 4)";
CM_ SG_ 2566834942 SPN6_High "SPN #6 (Conversion Version 4)";
CM_ SG_ 2566834942 SPN5_High "SPN #5 (Conversion Version 4)";
CM_ SG_ 2566834942 SPN4_High "SPN #4 (Conversion Version 4)";
CM_ SG_ 2566834942 SPN3_High "SPN #3 (Conversion Version 4)";
CM_ SG_ 2566834942 SPN2_High "SPN #2 (Conversion Version 4)";
CM_ SG_ 2566834942 SPN1_High "SPN #1 (Conversion Version 4)";
CM_ BO_ 2558533913 "Message used for the HVAC status";
CM_ SG_ 2558533913 AC_NET_SW_Type "Tipo sw - per il progetto NBC il tipo sw deve essere 2.";
CM_ SG_ 2558533913 AC_SW_Version "Versione SW";
CM_ SG_ 2558533913 AC_NET_Param_Version "Versione dei parametri";
CM_ SG_ 2558533913 AC_NET_Network_Status "Network Status";
CM_ SG_ 2558533913 AC_NET_Can_TX_Error_Counter "CAN error counter";
CM_ SG_ 2558533913 AC_NET_Can_RX_Error_Counter "CAN error counter";
CM_ BO_ 2558590745 "Message used for the HVAC feedback";
CM_ SG_ 2558590745 AC_Fan_Step "The signal shall be used by the BODY to know the HVAC Ventilation Step request.";
CM_ SG_ 2558590745 AC_Fan_Speed "The signal shall be used by the BODY to know the HVAC Ventilation Speed request.";
CM_ SG_ 2558590745 AC_Temp_Target "The signal shall be used by the BODY to know the HVAC Target Temperature request.";
CM_ SG_ 2558590745 AC_Auto_Manual_Lamp "The signal shall be used by the BODY to know the HVAC request of Status lamp activation/deactivation.";
CM_ SG_ 2558590745 AC_Compressor_lamp "The signal shall be used by the BODY to know the HVAC request of Compressor lamp activation/deactivation.";
CM_ SG_ 2558590745 AC_Mask_lamp "The signal shall be used by the BODY to know the Mask functionalities status.";
CM_ SG_ 2558590745 MASK_Valve_Request "The signal indicates the status of the Mask valve (activated/deactivated).";
CM_ SG_ 2558590745 AC_Hot_Water_Request "The signal shall be used by the BODY to know the HVAC request of Water Heater Valve activation/deactivation.";
CM_ SG_ 2558590745 AC_Compressor_Request "The signal shall be used by the BODY to know the HVAC request of Compressor activation/deactivation.";
CM_ SG_ 2558664983 CP6_SW_Type "Tipo sw - per il progetto NBC il tipo sw deve essere 2.";
CM_ SG_ 2558664983 CP6_SW_Version "Versione SW";
CM_ SG_ 2558664983 CP6_Graph_Version "Contiene la versione della grafica del CP6";
CM_ SG_ 2558664983 _nu_CP6_Network_Status "Network Status";
CM_ SG_ 2558664983 _nu_CP6_Can_TX_Error_Counter "CAN error counter";
CM_ SG_ 2558664983 _nu_CP6_Can_RX_Error_Counter "CAN error counter";
CM_ SG_ 2558665015 CP10_SW_Type "Tipo sw - per il progetto NBC il tipo sw deve essere 2.";
CM_ SG_ 2558665015 CP10_SW_Version "Versione SW";
CM_ SG_ 2558665015 CP10_Graph_Version "Contiene la versione della grafica del CP10";
CM_ SG_ 2558665015 _nu_CP10_Network_Status "Network Status";
CM_ SG_ 2558665015 _nu_CP10_Can_TX_Error_Counter "CAN error counter";
CM_ SG_ 2558665015 _nu_CP10_Can_RX_Error_Counter "CAN error counter";
CM_ BO_ 2558656289 "BC GATEWAY";
CM_ SG_ 2558656289 TachographVehicleSpeed_GTW "Speed of the vehicle registered by the tachograph.
See also SPN 1624";
CM_ SG_ 2558656289 EngSpeed_GTW "Actual engine speed which is calculated over a minimum crankshaft angle of 720 degrees divided by the number of
cylinders.
See also SPN 190";
CM_ BO_ 2566846241 "Battery potential";
CM_ SG_ 2566846241 BatteryPotential "Battery potential calculated by body computer.";
CM_ BO_ 2558932769 "TRIP";
CM_ SG_ 2558932769 Range_h "The signal shall be set by the BODY to define the Expected Hours Range.";
CM_ SG_ 2558932769 Range_km "The signal shall be set by the BODY to define the Expected Mileage Range.";
CM_ SG_ 2558932769 TotalDistance "The signal shall be set by the BODY to define the Total Mileage.";
CM_ BO_ 2564432382 "Diagnostic message - used for tester communication";
CM_ SG_ 2564432382 can1_diagrx_0 "Diagnostic signal - used for tester communication";
CM_ SG_ 2564432382 can1_diagrx_1 "Diagnostic signal - used for tester communication";
CM_ SG_ 2564432382 can1_diagrx_2 "Diagnostic signal - used for tester communication";
CM_ SG_ 2564432382 can1_diagrx_3 "Diagnostic signal - used for tester communication";
CM_ SG_ 2564432382 can1_diagrx_4 "Diagnostic signal - used for tester communication";
CM_ SG_ 2564432382 can1_diagrx_5 "Diagnostic signal - used for tester communication";
CM_ SG_ 2564432382 can1_diagrx_6 "Diagnostic signal - used for tester communication";
CM_ SG_ 2564432382 can1_diagrx_7 "Diagnostic signal - used for tester communication";
CM_ BO_ 2564485409 "Diagnostic message - used for tester communication";
CM_ SG_ 2564485409 can1_diagtx_0 "Diagnostic signal - used for tester communication";
CM_ SG_ 2564485409 can1_diagtx_1 "Diagnostic signal - used for tester communication";
CM_ SG_ 2564485409 can1_diagtx_2 "Diagnostic signal - used for tester communication";
CM_ SG_ 2564485409 can1_diagtx_3 "Diagnostic signal - used for tester communication";
CM_ SG_ 2564485409 can1_diagtx_4 "Diagnostic signal - used for tester communication";
CM_ SG_ 2564485409 can1_diagtx_5 "Diagnostic signal - used for tester communication";
CM_ SG_ 2564485409 can1_diagtx_6 "Diagnostic signal - used for tester communication";
CM_ SG_ 2564485409 can1_diagtx_7 "Diagnostic signal - used for tester communication";
CM_ BO_ 2632777505 "Diagnostic message - used for tester communication";
CM_ SG_ 2632777505 can1_tpcm_byte0 "Diagnostic signal - used for tester communication";
CM_ SG_ 2632777505 can1_tpcm_byte1 "Diagnostic signal - used for tester communication";
CM_ SG_ 2632777505 can1_tpcm_byte2 "Diagnostic signal - used for tester communication";
CM_ SG_ 2632777505 can1_tpcm_byte3 "Diagnostic signal - used for tester communication";
CM_ SG_ 2632777505 can1_tpcm_byte4 "Diagnostic signal - used for tester communication";
CM_ SG_ 2632777505 can1_tpcm_byte5 "Diagnostic signal - used for tester communication";
CM_ SG_ 2632777505 can1_tpcm_byte6 "Diagnostic signal - used for tester communication";
CM_ SG_ 2632777505 can1_tpcm_byte7 "Diagnostic signal - used for tester communication";
CM_ BO_ 2632711969 "Diagnostic message - used for tester communication";
CM_ SG_ 2632711969 can1_tpdt_byte0 "Diagnostic signal - used for tester communication";
CM_ SG_ 2632711969 can1_tpdt_byte1 "Diagnostic signal - used for tester communication";
CM_ SG_ 2632711969 can1_tpdt_byte2 "Diagnostic signal - used for tester communication";
CM_ SG_ 2632711969 can1_tpdt_byte3 "Diagnostic signal - used for tester communication";
CM_ SG_ 2632711969 can1_tpdt_byte4 "Diagnostic signal - used for tester communication";
CM_ SG_ 2632711969 can1_tpdt_byte5 "Diagnostic signal - used for tester communication";
CM_ SG_ 2632711969 can1_tpdt_byte6 "Diagnostic signal - used for tester communication";
CM_ SG_ 2632711969 can1_tpdt_byte7 "Diagnostic signal - used for tester communication";
CM_ BO_ 2566842000 "Time and Date";
CM_ SG_ 2566842000 Seconds_SDB "To be completed";
CM_ SG_ 2566842000 Minutes_SDB "To be completed";
CM_ SG_ 2566842000 Hours_SDB "To be completed";
CM_ SG_ 2566842000 Month_SDB "To be completed";
CM_ SG_ 2566842000 Day_SDB "To be completed";
CM_ SG_ 2566842000 Year_SDB "To be completed";
CM_ SG_ 2566842000 Local_Minute_Offset_SDB "To be completed";
CM_ SG_ 2566842000 Local_Hour_Offset_SDB "To be completed";
CM_ BO_ 2558736161 "Message used for collecting all the alarm for the display";
CM_ SG_ 2558736161 Lamp_NC_Sensor_NC_Alarm "The signal shall be set by the BODY to define the generic battery alarm.
";
CM_ SG_ 2558736161 Lamp_Transmission_Oil_Level "The signal shall be set by the BODY to define the Engine Oil Level lamp command.";
CM_ SG_ 2558736161 Lamp_NC_Sensor_C_Alarm "The signal shall be set by the BODY to define the generic battery alarm.
";
CM_ SG_ 2558736161 Lamp_NC_Sensor_N_Alarm "The signal shall be set by the BODY to define the generic battery alarm.
";
CM_ SG_ 2558736161 Lamp_NBC_PreFilterClogged "The signal shall be used by the BODY to require the NBC Filter Clogged lamp.";
CM_ SG_ 2558736161 Lamp_WaterInFuel "The signal shall be set by the BODY to define the WIF light lamp command.";
CM_ SG_ 2558736161 Lamp_Engine_Oil_Level "The signal shall be set by the BODY to define the Engine Oil Level lamp command.";
CM_ SG_ 2558736161 Lamp_Engine_AirFilter_Clogged "The signal shall be set by the BODY to define the Engine Air Filter Clogged lamp command.";
CM_ SG_ 2558736161 Lamp_Engine_Coolant_Level_Low "The signal shall be set by the BODY to define the Engine Coolant Level Low lamp command.";
CM_ SG_ 2558736161 Lamp_Cooling_Fan_Fault "The signal shall be used to know the Cooling Fan Oil Pressure Error lamp command";
CM_ SG_ 2558736161 Lamp_Fuel_Filter_Clogged "The signal shall be set by the BODY to define the Fuel Filter Clogged lamp command.";
CM_ SG_ 2558736161 Lamp_Services_AirPressure_Low "The signal shall be set by the BODY to define whether the air pressure is high or low.";
CM_ SG_ 2558736161 Lamp_Powersteering1LowPress "The signal shall be set by the BODY to define the Power Steering Circuit 1 lamp command.";
CM_ SG_ 2558736161 Lamp_Powersteering2LowPress "The signal shall be set by the BODY to define the Power Steering Circuit 2 lamp command.";
CM_ SG_ 2558736161 Lamp_PowersteeringLowOilLevel "The signal shall be set by the BODY to define the Power Steering Oil Level lamp command.";
CM_ SG_ 2558736161 Lamp_Pneumatic_Park_Brake "The signal shall be set by the BODY to define a feedback to CP about the Pneumatic Park Brake activation/deactivation status.";
CM_ SG_ 2558736161 Lamp_Mechanical_Park_Brake "The signal shall be set by the BODY to define a feedback to CP about the Electrical Park Brake activation/deactivation status.";
CM_ SG_ 2558736161 Lamp_NBC_Fault "The signal shall be used by the BODY to require the NBC Fault lamp.";
CM_ SG_ 2558736161 Lamp_NBC_LowPressure "The signal shall be used by the BODY to require the NBC Low Pressure  lamp.";
CM_ SG_ 2558736161 Lamp_NBC_FilterClogged "The signal shall be used by the BODY to require the NBC Filter Clogged lamp.";
CM_ SG_ 2558736161 Lamp_Gear_Oil_Temp_High "The signal shall be set by the BODY to define the Transmission Oil Temperature lamp command.";
CM_ SG_ 2558736161 Lamp_Brake_LowPressure "The signal shall be set by the BODY to define the Brakes Oil Level Status lamp command.";
CM_ SG_ 2558736161 Lamp_Alternator "The signal shall be set by the BODY to define the Alternator Not Charging lamp command.";
CM_ SG_ 2558736161 Lamp_Fuel_Temp_High "The signal shall be set by the BODY to define the Fuel Temperature lamp command.";
CM_ SG_ 2558736161 Lamp_NBC_FilterInstalled "The signal shall be set by the BODY to indicate that the NBC cartridges are available and installed";
CM_ SG_ 2558736161 Lamp_Battle_Short "The signal shall be set by the BODY to define the Short Battle Status lamp command.
";
CM_ SG_ 2558736161 Lamp_Battle_Switch "The signal shall be set by the BODY to define the Battle Switch Status lamp command.
";
CM_ SG_ 2558736161 Lamp_Brake_LowOilLevel "The signal shall be set by the BODY to define the Brakes Oil Level Status lamp command.";
CM_ SG_ 2558736161 Lamp_EngineCoolant1TempHigh "The signal shall be set by the BODY to indicate the secondary circuit cooling status.";
CM_ SG_ 2558736161 Lamp_EngineCoolant2TempHigh "The signal shall be set by the BODY to indicate the engine cooling status.";
CM_ BO_ 2558867233 "Message used for collecting all the analogic signals for the display";
CM_ SG_ 2558867233 NBC_Filtered_Usage "The signal shall be set by the BODY to define the NBC total filtered usage.";
CM_ SG_ 2558867233 NBC_Total_Usage "The signal shall be set by the BODY to define the NBC total usage.";
CM_ SG_ 2558867233 Transmission_Oil_Level "The signal shall be set by the BODY to define the Engine Oil Level current value [%]";
CM_ SG_ 2558867233 Secondary_Coolant_Temp "Temperature of liquid found in engine cooling system.

See also SPN 110";
CM_ SG_ 2558867233 Engine_Oil_Level "The signal shall be set by the BODY to define the Engine Oil Level current value [%]";
CM_ SG_ 2558867233 Turret_Angle "The signal shall be set by the BODY to define the current Turret Position (deg).";
CM_ BO_ 2558998305 "Message used for collecting the warning messages for the display";
CM_ SG_ 2558998305 POWERSTR_SPEED_TOO_HIGH "The signal shall be set by the BODY to define the Dangerous Speed Warning due to PowerSteering status activation/deactivation command for the Control Panels.";
CM_ SG_ 2558998305 _nu_Warnings_bit63 "Not used warning";
CM_ SG_ 2558998305 _nu_Warnings_bit62 "Not used warning";
CM_ SG_ 2558998305 _nu_Warnings_bit61 "Not used warning";
CM_ SG_ 2558998305 _nu_Warnings_bit60 "Not used warning";
CM_ SG_ 2558998305 _nu_Warnings_bit59 "Not used warning";
CM_ SG_ 2558998305 _nu_Warnings_bit58 "Not used warning";
CM_ SG_ 2558998305 _nu_Warnings_bit57 "Not used warning";
CM_ SG_ 2558998305 _nu_Warnings_bit56 "Not used warning";
CM_ SG_ 2558998305 _nu_Warnings_bit55 "Not used warning";
CM_ SG_ 2558998305 _nu_Warnings_bit54 "Not used warning";
CM_ SG_ 2558998305 _nu_Warnings_bit53 "Not used warning";
CM_ SG_ 2558998305 _nu_Warnings_bit52 "Not used warning";
CM_ SG_ 2558998305 _nu_Warnings_bit51 "Not used warning";
CM_ SG_ 2558998305 _nu_Warnings_bit50 "Not used warning";
CM_ SG_ 2558998305 _nu_Warnings_bit49 "Not used warning";
CM_ SG_ 2558998305 _nu_Warnings_bit48 "Not used warning";
CM_ SG_ 2558998305 _nu_Warnings_bit47 "Not used warning";
CM_ SG_ 2558998305 _nu_Warnings_bit46 "Not used warning";
CM_ SG_ 2558998305 _nu_Warnings_bit45 "Not used warning";
CM_ SG_ 2558998305 _nu_Warnings_bit44 "Not used warning";
CM_ SG_ 2558998305 _nu_Warnings_bit43 "Not used warning";
CM_ SG_ 2558998305 _nu_Warnings_bit42 "Not used warning";
CM_ SG_ 2558998305 _nu_Warnings_bit41 "Not used warning";
CM_ SG_ 2558998305 _nu_Warnings_bit40 "Not used warning";
CM_ SG_ 2558998305 _nu_Warnings_bit39 "Not used warning";
CM_ SG_ 2558998305 _nu_Warnings_bit38 "Not used warning";
CM_ SG_ 2558998305 _nu_Warnings_bit37 "Not used warning";
CM_ SG_ 2558998305 _nu_Warnings_bit36 "Not used warning";
CM_ SG_ 2558998305 _nu_Warnings_bit35 "Not used warning";
CM_ SG_ 2558998305 _nu_Warnings_bit34 "Not used warning";
CM_ SG_ 2558998305 _nu_Warnings_bit33 "Not used warning";
CM_ SG_ 2558998305 _nu_Warnings_bit32 "Not used warning";
CM_ SG_ 2558998305 _nu_Warnings_bit31 "Not used warning";
CM_ SG_ 2558998305 _nu_Warnings_bit30 "Not used warning";
CM_ SG_ 2558998305 _nu_Warnings_bit18 "Not used warning";
CM_ SG_ 2558998305 AUX_HEATER_TO_BE_START "The signal shall be set by the BODY to define the 'ACCENDERE IL RISCALDATORE AUSILIARIO' Warning activation/deactivation command for the Control Panels.";
CM_ SG_ 2558998305 AUX_HEATER_WARNING "The signal shall be set by the BODY to define the 'CONSIGLIABILE ACCENDERE IL RISCALDATORE AUSILIARIO' Warning activation/deactivation command for the Control Panels.";
CM_ SG_ 2558998305 GEARBOX_OVER_TEMP "The signal shall be set by the BODY to define the 'SOVRATEMPERATURA OLIO CAMBIO' Warning activation/deactivation command for the Control Panels.";
CM_ SG_ 2558998305 LOW_GEARBOX_OIL_LEVEL "The signal shall be set by the BODY to define the 'BASSO LIVELLO OLIO CAMBIO' Warning activation/deactivation command for the Control Panels.";
CM_ SG_ 2558998305 LOW_ENGINE_OIL_LEVEL "The signal shall be set by the BODY to define the 'BASSO LIVELLO OLIO MOTORE' Warning activation/deactivation command for the Control Panels.";
CM_ SG_ 2558998305 LOW_BATTERY "The signal shall be set by the BODY to define the 'TENSIONE BATTERIA TROPPO BASSA' Warning activation/deactivation command for the Control Panels.";
CM_ SG_ 2558998305 FIRE_ALARM "The signal shall be set by the BODY to define the 'INCENDIO IN CORSO' Warning activation/deactivation command for the Control Panels.";
CM_ SG_ 2558998305 ENGINE_COOLANT_LEVEL_TOO_LOW "The signal shall be set by the BODY to define the 'BASSO LIVELLO LIQUIDO RAFFREDDAMENTO PRIMARIO  – SPEGNERE IL MOTORE' Warning activation/deactivation command for the Control Panels.";
CM_ SG_ 2558998305 ENGINE_TEMPERATURE_TOO_HIGH "The signal shall be set by the BODY to define the 'ALTA TEMPERATURE OLIO MOTORE  – SPEGNERE IL MOTORE' Warning activation/deactivation command for the Control Panels.";
CM_ SG_ 2558998305 OIL_PRESSURE_LOW "The signal shall be set by the BODY to define the 'BASSA PRESSIONE OLIO – SPEGNERE IL MOTORE' Warning activation/deactivation command for the Control Panels.";
CM_ SG_ 2558998305 ENGINE_OVERRUN_RETARDER_ACTIVE "The signal shall be set by the BODY to define the 'INSERIMENTO AUTOMATICO DEL RETARDER PER FUORIGIRI MOTORE' Warning activation/deactivation command for the Control Panels.";
CM_ SG_ 2558998305 GEARBOX_NOT_IN_NEUTRAL "The signal shall be set by the BODY to define the 'CAMBIO NON IN FOLLE' Warning activation/deactivation command for the Control Panels.";
CM_ SG_ 2558998305 BRAKE_NOT_PRESSED "The signal shall be set by the BODY to define the 'PEDALE FRENO NON PREMUTO' Warning activation/deactivation command for the Control Panels.";
CM_ SG_ 2558998305 SYSTEM_POWERED_FROM_EXT_SUPPLY "The signal shall be set by the BODY to define the 'SISTEMA ACCESO DA ALIMENTAZIONE ESTERNA' Warning activation/deactivation command for the Control Panels.";
CM_ SG_ 2558998305 KEY_INSERTED "The signal shall be set by the BODY to define the 'RIMUOVERE LA CHIAVE PER SPEGNERE IL SISTEMA' Warning activation/deactivation command for the Control Panels.";
CM_ SG_ 2558998305 STARTER_OVERRIDE_IN_PROGRESS "The signal shall be set by the BODY to define the 'AVVIAMENTO DI EMERGENZA ABILITATO' Warning activation/deactivation command for the Control Panels.";
CM_ SG_ 2558998305 HYDRONIC_SHUTDOWN_IN_PROGRESS "The signal shall be set by the BODY to define the 'LAVAGGIO RISCALDATORE AUSILIARIO IN CORSO' Warning activation/deactivation command for the Control Panels.";
CM_ SG_ 2558998305 BRAKE_FAULT "The signal shall be set by the BODY to define the 'AVARIA SISTEMA FRENANTE' Warning activation/deactivation command for the Control Panels.";
CM_ SG_ 2558998305 DRIVING_WITH_PARK_BRAKE_ACTIVE "The signal shall be set by the BODY to define the 'GUIDA CON FRENO A MANO INSERITO' Warning activation/deactivation command for the Control Panels.";
CM_ SG_ 2558998305 SERVICES_AIR_PRESS_LOW "The signal shall be set by the BODY to define the 'PRESSIONE ARIA SERVIZI TROPPO BASSA' Warning activation/deactivation command for the Control Panels.";
CM_ SG_ 2558998305 ENGINE_NOT_STOP "The signal shall be set by the BODY to define the 'IMPOSSIBILE SPEGNERE MOTORE' Warning activation/deactivation command for the Control Panels.";
CM_ SG_ 2558998305 DRIVER_HATCH_OPEN "The signal shall be set by the BODY to define the 'BOTOLA PILOTA APERTA' Warning activation/deactivation command for the Control Panels.";
CM_ SG_ 2558998305 DUST_EXTRACTION_OFF "The signal shall be set by the BODY to define the 'ESTRATTORE POLVERE SPENTO' Warning activation/deactivation command for the Control Panels.";
CM_ SG_ 2558998305 FORD_MODE_ACTIVE "The signal shall be set by the BODY to define the 'MODALITA' GUADO ATTIVA' Warning activation/deactivation command for the Control Panels.";
CM_ SG_ 2558998305 DANGEROUS_SPEED "The signal shall be set by the BODY to define the 'VELOCITA' PERICOLOSA' Warning activation/deactivation command for the Control Panels.";
CM_ SG_ 2558998305 SPEED_TOO_HIGH "The signal shall be set by the BODY to define the 'VELOCITA' TROPPO ALTA' Warning activation/deactivation command for the Control Panels.";
CM_ SG_ 2558998305 EMERGENCY_CRANK_IN_PROGRESS "The signal shall be set by the BODY to define the 'AVVIAMENTO DI EMERGENZA IN CORSO' Warning activation/deactivation command for the Control Panels.";
CM_ SG_ 2558998305 ENGINE_IS_OFF "The signal shall be set by the BODY to define the 'MOTORE SPENTO' Warning activation/deactivation command for the Control Panels.";
CM_ BO_ 2558801697 "Message used for collecting the icon for the display";
CM_ SG_ 2558801697 EngineAlarm "The signal shall be set by the BODY to define the generic engine alarm.";
CM_ SG_ 2558801697 EngineOilPressureLow_BC "The signal shall be used to control the Engine Oil Pressure Low lamp command.";
CM_ SG_ 2558801697 EngineOilTemperatureHigh_BC "The signal shall be used by the CPx to know the Engile Oil Temperature lamp command.";
CM_ SG_ 2558801697 NBC_Generic_Fault "The signal shall be set by the BODY to define the generic battery alarm.";
CM_ SG_ 2558801697 EngineEoilFilterClogged "The signal shall be set by the BODY to define the generic battery alarm.";
CM_ SG_ 2558801697 NBC_FilterClogged_Status "The signal shall be set by the BODY to define the generic battery alarm.";
CM_ SG_ 2558801697 NBC_FilterClogged_Alarm "The signal shall be set by the BODY to define the generic battery alarm.";
CM_ SG_ 2558801697 Icon_Emergency_Direction "The signal shall be set by the BODY to define the emergency or the direction light status.";
CM_ SG_ 2558801697 Icon_Light_Status "This signal is used to indicate the lamp to be displayed on the CP to indicate the light status";
CM_ SG_ 2558801697 Icon_Left_Ammunition_Door "The signal shall be set by the BODY to command the Left Ammunition Door icon on the Control Panels.";
CM_ SG_ 2558801697 Icon_Retarder "The signal shall be set by the BODY to define the Retarder Icon activation/deactivation command for the Control Panels.

The values of the signal shall be:
- Off
- Bar25%
- Bar50%
- Bar75%
- Bar100%
- Bar125%
Please, see also SYS_CAN_0280";
CM_ SG_ 2558801697 Icon_Battery_Selected "The signal shall be set by the BODY to command the cranking battery icon on the Control Panels.";
CM_ SG_ 2558801697 Icon_Battery_Status "The signal shall be set by the BODY to command the normal battery icon on the Control Panels.";
CM_ SG_ 2558801697 Icon_Driver_Hatch "The signal shall be set by the BODY to command the Driver Door icon on the Control Panels.
";
CM_ SG_ 2558801697 Icon_Turret_Hatch_Right_Sts "The signal shall be set by the BODY to command the Turret right hatch icon on the Control Panels.
";
CM_ SG_ 2558801697 Icon_Turret_Hatch_Left_Sts "The signal shall be set by the BODY to command the Turret left hatch  icon on the Control Panels.
";
CM_ SG_ 2558801697 Icon_Right_Ammunition_Door "The signal shall be set by the BODY to command the Right Ammunition load Door icon on the Control Panels.";
CM_ SG_ 2558801697 Icon_Rear_Door "The signal shall be set by the BODY to command the Rear Door icon on the Control Panels.
";
CM_ SG_ 2558801697 Icon_Rear_Lock "The signal shall be set by the BODY to command the Rear Door lock icon on the Control Panels.
";
CM_ SG_ 2558801697 ColdStartHeaterStatus_BC "The signal shall be used to know the Cold Start Heater Status sent by the body computer";
CM_ SG_ 2558801697 Icon_Payload_Door "The signal shall be set by the BODY to command the Payload Door icon on the Control Panels.
";
CM_ SG_ 2558801697 Icon_CTIS_ProcessMode "Signal used to indicate the CTIS Process mode";
CM_ BO_ 2558670625 "Message used for collecting the body computer feedback for the display";
CM_ SG_ 2558670625 Fbk_Clima_Vent_Step "The signal shall be set by the BODY to define the Climate Ventilation Step command.
";
CM_ SG_ 2558670625 Fbk_Clima_Menu "The signal shall be set by the BODY to define the Climate Menu lamp command.";
CM_ SG_ 2558670625 Fbk_Clima_Temp_Target "The signal shall be set by the BODY to define the Climate Target Temperature command.
";
CM_ SG_ 2558670625 Fbk_Clima_Compressor "The signal shall be set by the BODY to define the Climate Compressor lamp command.";
CM_ SG_ 2558670625 Fbk_Clima_ON_AUTO_MAN "The signal shall be set by the BODY to define the Climate Menu lamp command.";
CM_ SG_ 2558670625 Fbk_Camera_Menu "The signal shall be set by the BODY to define the Camera Menu lamp command.";
CM_ SG_ 2558670625 Fbk_CrewAreaHeater "Signal used to indicate the hydronic heater lamp status";
CM_ SG_ 2558670625 Fbk_NUC_Enable "The signal shall be set by the BODY to define the NUC activation/deactivation.";
CM_ SG_ 2558670625 Fbk_Polarity "The signal shall be set by the BODY to define the polarity selection (between black hot and white hot).";
CM_ SG_ 2558670625 Fbk_ROI "The signal shall be set by the BODY to define the ROI selection (between TOP HALF, CENTER BLOCK, BOTTOM HALF and FULL SCREEN).";
CM_ SG_ 2558670625 Fbk_TYPE "The signal shall be set by the BODY to define the TYPE selection (between OPTICAL and THERMAL).";
CM_ SG_ 2558670625 Fbk_ChangeView "The signal shall be set by the BODY to define the driver mode view (1, 2, 3 or 4).";
CM_ SG_ 2558670625 Fbk_Sights_Washer "The signal shall be set by the BODY to define the Sight Washer lamp command.";
CM_ SG_ 2558670625 _nu_Fbk_Not_Used_3_16 "Feedback not used";
CM_ SG_ 2558670625 _nu_Fbk_Not_Used_3_18 "Feedback not used";
CM_ SG_ 2558670625 _nu_Fbk_Not_Used_3_20 "Feedback not used";
CM_ SG_ 2558670625 _nu_Fbk_Not_Used_1_22 "Feedback not used";
CM_ SG_ 2558670625 _nu_Fbk_Not_Used_3_24 "Feedback not used";
CM_ SG_ 2558670625 _nu_Fbk_Not_Used_3_26 "Feedback not used";
CM_ SG_ 2558670625 _nu_Fbk_Not_Used_3_28 "Feedback not used";
CM_ SG_ 2558670625 _nu_Fbk_Not_Used_3_30 "Feedback not used";
CM_ SG_ 2558670625 Fbk_PerimetralVision "The signal shall be set by the BODY to define the perimetral vision lamp command.";
CM_ SG_ 2558670625 Fbk_SelMonitor "The signal shall be set by the BODY to define the monitor selection lamp command.";
CM_ SG_ 2558670625 Fbk_SelTlc "The signal shall be set by the BODY to define the camera selection lamp command.";
CM_ SG_ 2558670625 Fbk_SelCfg "The signal shall be set by the BODY to define the configuration selection lamp command.";
CM_ SG_ 2558670625 Fbk_SaveCfg "The signal shall be set by the BODY to define the save configuration lamp command.";
CM_ SG_ 2558670625 Fbk_RestoreCfg "The signal shall be set by the BODY to define the restore configuration lamp command.";
CM_ SG_ 2558670625 Fbk_HeaterTlc "The signal shall be set by the BODY to define the camera heater lamp command.";
CM_ SG_ 2558670625 Fbk_Overlay "The signal shall be set by the BODY to define the overlay lamp command and  the Vuhlcan viewer lamp command.";
CM_ SG_ 2558670625 Fbk_CameraCfg_Menu "The signal shall be set by the BODY to define the Camera Configuraionr Menu lamp command.";
CM_ BO_ 2558605089 "Message used for collecting the body computer feedback for the display";
CM_ SG_ 2558605089 Fbk_NBC_Menu "Signal used to indicate the NBC menu status";
CM_ SG_ 2558605089 Fbk_Mask "Signal used to indicate the Mask lamp status";
CM_ SG_ 2558605089 Fbk_NBC_Ventilation_Low "Signal used to indicate if the NBC low ventilation mode is active or not";
CM_ SG_ 2558605089 Fbk_NBC_Ventilation_Fast "Signal used to indicate if the NBC fast ventilation mode is active or not";
CM_ SG_ 2558605089 Fbk_NBC_FilterMode "Signal used to indicate the NBC filter modes";
CM_ SG_ 2558605089 Fbk_MechParkingBrake "The signal shall be set by the BODY to define a feedback to CP about the Mechanical Park Brake activation/deactivation status.";
CM_ SG_ 2558605089 Fbk_Retarder_Up "The signal shall be set by the BODY to define the pushbutton 'Retarder Up' status.";
CM_ SG_ 2558605089 Fbk_Retarder_OnOff "The signal shall be set by the BODY to define the pushbutton 'Retarder On/Off' status.";
CM_ SG_ 2558605089 Fbk_Retarder_Down "The signal shall be set by the BODY to define the pushbutton 'Retarder Down' status.";
CM_ SG_ 2558605089 Fbk_CTIS_Menu "The signal shall be set by the BODY to define the Ctis Menu lamp command.";
CM_ SG_ 2558605089 Fbk_Retarder_Menu "The signal shall be set by the BODY to define whether a request of Retarder is present.";
CM_ SG_ 2558605089 Fbk_CTIS_Check "The signal shall be set by the BODY to define the Ctis Check lamp command.
";
CM_ SG_ 2558605089 Fbk_CTIS_Load "The signal shall be set by the BODY to define the Ctis Load lamp command.";
CM_ SG_ 2558605089 Fbk_CTIS_Emergency "The signal shall be set by the BODY to define the Ctis Emergency lamp command.";
CM_ SG_ 2558605089 Fbk_CTIS_Sand "The signal shall be set by the BODY to define the Ctis Sand lamp command.";
CM_ SG_ 2558605089 Fbk_CTIS_Track "The signal shall be set by the BODY to define the Ctis Track lamp command.";
CM_ SG_ 2558605089 Fbk_CTIS_Road "The signal shall be set by the BODY to define the Ctis Road lamp command.";
CM_ SG_ 2558605089 Fbk_CTIS_ON "The signal shall be set by the BODY to define the Ctis On lamp command.";
CM_ SG_ 2558605089 _nu_Fbk_Not_Used_2_06 "Feedback not used";
CM_ SG_ 2558605089 _nu_Fbk_Not_Used_2_08 "Feedback not used";
CM_ SG_ 2558605089 _nu_Fbk_Not_Used_2_10 "Feedback not used";
CM_ SG_ 2558605089 _nu_Fbk_Not_Used_2_38 "Feedback not used";
CM_ SG_ 2558605089 Fbk_NBCReset "The signal shall be set by the BODY to define the NBC reset lamp command.";
CM_ SG_ 2558605089 _nu_Fbk_Not_Used_2_42 "Feedback not used";
CM_ SG_ 2558605089 _nu_Fbk_Not_Used_2_48 "Feedback not used";
CM_ SG_ 2558605089 _nu_Fbk_Not_Used_2_50 "Feedback not used";
CM_ SG_ 2558605089 _nu_Fbk_Not_Used_2_52 "Feedback not used";
CM_ SG_ 2558605089 _nu_Fbk_Not_Used_2_54 "Feedback not used";
CM_ SG_ 2558605089 _nu_Fbk_Not_Used_2_56 "Feedback not used";
CM_ SG_ 2558605089 _nu_Fbk_Not_Used_2_58 "Feedback not used";
CM_ SG_ 2558605089 _nu_Fbk_Not_Used_2_60 "Feedback not used";
CM_ SG_ 2558605089 _nu_Fbk_Not_Used_2_62 "Feedback not used";
CM_ BO_ 2558539553 "Message used for collecting the body computer feedback for the display";
CM_ SG_ 2558539553 Fbk_Emergency_Blinker "The signal shall be set by the BODY to define whether the emergency blinker is active or not.";
CM_ SG_ 2558539553 Fbk_Engine_Aux_Heater "The signal shall be set by the BODY to define a feedback to CP about the user last Engine Auxiliary Heater request.";
CM_ SG_ 2558539553 Fbk_Driveline_Menu "The signal shall be set by the BODY to define the Driveline Menu lamp command.";
CM_ SG_ 2558539553 Fbk_Aux_Menu "The signal shall be set by the BODY to define the Aux Menu lamp command.";
CM_ SG_ 2558539553 Fbk_Light_Menu "The signal shall be set by the BODY to define the Light Menu lamp command.";
CM_ SG_ 2558539553 Fbk_Four_Axle "The signal shall be set by the BODY to define the Fourth Axle Steering lamp command.";
CM_ SG_ 2558539553 Fbk_Lock_Diff "The signal shall be set by the BODY to define the Differential Lock lamp command.";
CM_ SG_ 2558539553 Fbk_All_Wheel_Drive "The signal shall be set by the BODY to define the All Wheel Drive lamp command.";
CM_ SG_ 2558539553 Fbk_Ford_Mode "The signal shall be set by the BODY to define the Ford Mode lamp command.";
CM_ SG_ 2558539553 Fbk_Bilge_Pump_EngineBay "The signal shall be set by the BODY to define the Engine Bay Bilge Pump lamp command.";
CM_ SG_ 2558539553 Fbk_Dust_Fan "The signal shall be set by the BODY to define the Dust Extraction Fan lamp command.";
CM_ SG_ 2558539553 Fbk_Warlight_B2 "The signal shall be set by the BODY to define whether the War_2 mode is active or not and the War2 light lamp command.";
CM_ SG_ 2558539553 Fbk_Warlight_B1 "The signal shall be set by the BODY to define whether the War1 mode is active or not and the War1 light lamp command.";
CM_ SG_ 2558539553 Fbk_Low_Beam_Light "The signal shall be set by the BODY to define whether the Night mode is active or not and the Low Beam light lamp command.";
CM_ SG_ 2558539553 Fbk_Marker_Light "The signal shall be set by the BODY to define whether the Dusk mode is active or not and the Marker light lamp command.";
CM_ SG_ 2558539553 _nu_Fbk_Not_Used_1_02 "Feedback not used";
CM_ SG_ 2558539553 _nu_Fbk_Not_Used_1_08 "Feedback not used";
CM_ SG_ 2558539553 Fbk_Fuel_Pump "The signal shall be set by the BODY to define the fuel pump lamp command.";
CM_ SG_ 2558539553 _nu_Fbk_Not_Used_1_26 "Feedback not used";
CM_ SG_ 2558539553 Fbk_TripReset "The signal shall be set by the BODY to define the FBK Trip Reset command.";
CM_ SG_ 2558539553 _nu_Fbk_Not_Used_1_32 "Feedback not used";
CM_ SG_ 2558539553 _nu_Fbk_Not_Used_1_34 "Feedback not used";
CM_ SG_ 2558539553 _nu_Fbk_Not_Used_1_36 "Feedback not used";
CM_ SG_ 2558539553 _nu_Fbk_Not_Used_1_38 "Feedback not used";
CM_ SG_ 2558539553 _nu_Fbk_Not_Used_1_40 "Feedback not used";
CM_ SG_ 2558539553 _nu_Fbk_Not_Used_1_42 "Feedback not used";
CM_ SG_ 2558539553 _nu_Fbk_Not_Used_1_44 "Feedback not used";
CM_ SG_ 2558539553 _nu_Fbk_Not_Used_1_46 "Feedback not used";
CM_ SG_ 2558539553 _nu_Fbk_Not_Used_1_54 "Feedback not used";
CM_ SG_ 2558539553 _nu_Fbk_Not_Used_1_56 "Feedback not used";
CM_ SG_ 2558539553 _nu_Fbk_Not_Used_1_58 "Feedback not used";
CM_ SG_ 2558539553 _nu_Fbk_Not_Used_1_60 "Feedback not used";
CM_ BO_ 2558599447 "Message used for collecting the bushbutton status coming from the CP6 for the BC";
CM_ SG_ 2558599447 Btn_Clima_Vent_Up_CP6 "The signal shall be used to know when the user's request of Clima Ventilation UP activation/deactivation coming from CP6.";
CM_ SG_ 2558599447 Btn_Clima_Vent_Down_CP6 "The signal shall be used to know when the user's request of Clima Ventilation DOWN  activation/deactivation coming from CP6.";
CM_ SG_ 2558599447 Btn_Clima_Temp_Up_CP6 "The signal shall be used to know when the user's request of Clima Temperature UP activation/deactivation coming from CP6.";
CM_ SG_ 2558599447 Btn_Clima_Temp_Down_CP6 "The signal shall be used to know when the user's request of Clima Temperature DOWN activation/deactivation coming from CP6.";
CM_ SG_ 2558599447 Btn_Clima_ON_AUTO_MAN_CP6 "The signal shall be used to know when the user's request of HVAC activation/deactivation coming from CP6.";
CM_ SG_ 2558599447 Btn_Clima_Compressor_CP6 "The signal shall be used to know when the user's request of HVAC AC activation/deactivation coming from CP6.";
CM_ SG_ 2558599447 Btn_CrewAreaHeater_CP6 "The signal shall be used to know when the user's request of Hydronic Crew Area Heater activation/deactivation coming from CP6.";
CM_ SG_ 2558599447 Btn_NBC_Ventilation_Low_CP6 "The signal shall be set by the CP6 to define the user's request of low NBC ventilation activation/deactivation";
CM_ SG_ 2558599447 Btn_NBC_Ventilation_Fast_CP6 "The signal shall be set by the CP10 to define the user's request of low NBC ventilation activation/deactivation";
CM_ SG_ 2558599447 Btn_NBC_FilterMode_CP6 "The signal shall be set by the CP6 to define the user's request of NBC filter mode activation/deactivation.";
CM_ SG_ 2558599447 Btn_Mask_CP6 "The signal shall be set by the CP6 to define the user's request of Mask functionalities activation/deactivation.";
CM_ SG_ 2558599447 Btn_NUC_Enable_CP6 "The signal shall be set by the CP6 to define the user's request of the NUC activation/deactivation.";
CM_ SG_ 2558599447 Btn_Polarity_CP6 "The signal shall be set by the CP6 to define the user's request of the polarity selection (between black hot and white hot).";
CM_ SG_ 2558599447 Btn_ROI_CP6 "The signal shall be set by the CP6 to define the user's request of the ROI selection (between TOP HALF, CENTER BLOCK, BOTTOM HALF and FULL SCREEN).";
CM_ SG_ 2558599447 Btn_TYPE_CP6 "The signal shall be set by the CP6 to define the user's request of the TYPE selection (between OPTICAL and THERMAL).";
CM_ SG_ 2558599447 Btn_ChangeView_CP6 "The signal shall be set by the CP6 to define the user's request to change view.";
CM_ SG_ 2558599447 _nu_Btn_1_03_CP6 "Not used button";
CM_ SG_ 2558599447 Btn_NBCReset_CP6 "The signal shall be set by the CP6 to define the user's request of NBC Counter Reset.";
CM_ SG_ 2558599447 _nu_Btn_1_05_CP6 "Not used button";
CM_ SG_ 2558599447 _nu_Btn_1_07_CP6 "Not used button";
CM_ SG_ 2558599447 _nu_Btn_1_08_CP6 "Not used button";
CM_ SG_ 2558599447 _nu_Btn_1_09_CP6 "Not used button";
CM_ SG_ 2558599447 _nu_Btn_1_10_CP6 "Not used button";
CM_ SG_ 2558599447 _nu_Btn_1_11_CP6 "Not used button";
CM_ SG_ 2558599447 _nu_Btn_1_12_CP6 "Not used button";
CM_ SG_ 2558599447 _nu_Btn_1_13_CP6 "Not used button";
CM_ SG_ 2558599447 _nu_Btn_1_14_CP6 "Not used button";
CM_ SG_ 2558599447 _nu_Btn_1_15_CP6 "Not used button";
CM_ SG_ 2558599447 _nu_Btn_1_23_CP6 "Not used button";
CM_ SG_ 2558599447 _nu_Btn_1_24_CP6 "Not used button";
CM_ SG_ 2558599447 _nu_Btn_1_25_CP6 "Not used button";
CM_ SG_ 2558599447 _nu_Btn_1_26_CP6 "Not used button";
CM_ SG_ 2558599447 _nu_Btn_1_27_CP6 "Not used button";
CM_ SG_ 2558599447 _nu_Btn_1_28_CP6 "Not used button";
CM_ SG_ 2558599447 _nu_Btn_1_29_CP6 "Not used button";
CM_ SG_ 2558599447 _nu_Btn_1_30_CP6 "Not used button";
CM_ SG_ 2558599447 _nu_Btn_1_31_CP6 "Not used button";
CM_ SG_ 2558599447 Btn_PerimetralVision_CP6 "The signal shall be set by the CP6 to define the user's request to perimetral vision.";
CM_ SG_ 2558599447 Btn_SelMonitor_CP6 "The signal shall be used to know when the user's request to change the monitor to be configured coming from CP6.";
CM_ SG_ 2558599447 _nu_Btn_1_39_CP6 "Not used button";
CM_ SG_ 2558599447 Btn_Sights_Washer_CP6 "The signal shall be used to know when the user's request of Sight Wsher activation/deactivation coming from CP6.";
CM_ SG_ 2558599447 Btn_SelTlc_CP6 "The signal shall be used to know when the user's request to change the camera for the selected monitor coming from CP6.";
CM_ SG_ 2558599447 Btn_SelCfg_CP6 "The signal shall be used to know when the user's request to change the configuration to be modified coming from CP6.";
CM_ SG_ 2558599447 Btn_SaveCfg_CP6 "The signal shall be used to know when the user's request to save the modified configuration coming from CP6.";
CM_ SG_ 2558599447 Btn_RestoreCfg_CP6 "The signal shall be used to know when the user's request to restore the factory configuration coming from CP6.";
CM_ SG_ 2558599447 Btn_HeaterTlc_CP6 "The signal shall be used to know when the user's request to heat the camera coming from CP6.";
CM_ SG_ 2558599447 Btn_Overlay_CP6 "The signal shall be used to know when the user's request to activate the overlay function coming from CP6.";
CM_ SG_ 2558599447 _nu_Btn_1_47_CP6 "Not used button";
CM_ SG_ 2558599447 _nu_Btn_1_48_CP6 "Not used button";
CM_ SG_ 2558599447 _nu_Btn_1_49_CP6 "Not used button";
CM_ SG_ 2558599447 _nu_Btn_1_50_CP6 "Not used button";
CM_ SG_ 2558599447 _nu_Btn_1_51_CP6 "Not used button";
CM_ SG_ 2558599447 _nu_Btn_1_52_CP6 "Not used button";
CM_ SG_ 2558599447 _nu_Btn_1_53_CP6 "Not used button";
CM_ SG_ 2558599447 _nu_Btn_1_54_CP6 "Not used button";
CM_ SG_ 2558599447 _nu_Btn_1_55_CP6 "Not used button";
CM_ SG_ 2558599447 _nu_Btn_1_56_CP6 "Not used button";
CM_ SG_ 2558599447 _nu_Btn_1_57_CP6 "Not used button";
CM_ SG_ 2558599447 _nu_Btn_1_58_CP6 "Not used button";
CM_ SG_ 2558599447 _nu_Btn_1_59_CP6 "Not used button";
CM_ SG_ 2558599447 _nu_Btn_1_60_CP6 "Not used button";
CM_ SG_ 2558599447 _nu_Btn_1_61_CP6 "Not used button";
CM_ SG_ 2558599447 _nu_Btn_1_62_CP6 "Not used button";
CM_ SG_ 2558599447 _nu_Btn_1_63_CP6 "Not used button";
CM_ BO_ 2558533911 "Message used for collecting the bushbutton status coming from the CP6 for the BC";
CM_ SG_ 2558533911 Btn_EngineHeater_CP6 "The signal shall be used to know when the user's request of engine auxiliary heater activation/deactivation coming from CP6.";
CM_ SG_ 2558533911 Btn_ParkingBrake_CP6 "The signal shall be used by the BODY to know the user's request of Pneumatic ParkBrake activation/deactivation coming from CP6.";
CM_ SG_ 2558533911 Btn_CTIS_Check_CP6 "The signal shall be used to know when the user's request of CTIS Check Mode selection  coming from CP6.";
CM_ SG_ 2558533911 Btn_CTIS_Load_CP6 "The signal shall be used to know when the user's request of CTIS Load Mode selection coming from CP6.";
CM_ SG_ 2558533911 Btn_CTIS_Emergency_CP6 "The signal shall be used to know when the user's request of CTIS Emergency Mode activation/deactivation coming from CP6.";
CM_ SG_ 2558533911 Btn_CTIS_Sand_CP6 "The signal shall be used to know when the user's request of CTIS Sand Mode activation/deactivation coming from CP6.";
CM_ SG_ 2558533911 Btn_CTIS_Track_CP6 "The signal shall be used to know when the user's request of CTIS Track Mode activation/deactivation coming from CP6.";
CM_ SG_ 2558533911 Btn_CTIS_Road_Cp6 "The signal shall be used to know when the user's request of CTIS Road Mode activation/deactivation coming from CP6.";
CM_ SG_ 2558533911 Btn_CTIS_ON_CP6 "The signal shall be used to know when the user's request of CTIS  activation/deactivation coming from CP6.";
CM_ SG_ 2558533911 Btn_Retarder_Down_CP6 "The signal shall be used by the BODY to know the user's request of Retarder reduction coming from CP6.";
CM_ SG_ 2558533911 Btn_Retarder_Up_CP6 "The signal shall be used to know when the user's request of Retarder Up activation/deactivation coming from CP6.";
CM_ SG_ 2558533911 Btn_Retarder_Off_CP6 "The signal shall be used to know when the user's request of Retarder Off activation/deactivation coming from CP6.";
CM_ SG_ 2558533911 Btn_4th_Steering_Axle_CP6 "The signal shall be used to know when the user's request of Fourth Steering Axle activation/deactivation coming from CP6.";
CM_ SG_ 2558533911 Btn_Lock_Front_Diff_CP6 "The signal shall be used to know when the user's request of Differential Lock activation/deactivation coming from CP6.";
CM_ SG_ 2558533911 Btn_All_Wheel_Drive_CP6 "The signal shall be used to know when the user's request of AWD activation/deactivation coming from CP6.";
CM_ SG_ 2558533911 Btn_Ford_Mode_CP6 "The signal shall be used to know when the user's request of Ford Mode activation/deactivation coming from CP6.";
CM_ SG_ 2558533911 Btn_Bilge_Pump_EngineBay_CP6 "The signal shall be used to know when the user's request of Engine Bay Bilge Pump activation/deactivation coming from CP6.";
CM_ SG_ 2558533911 Btn_TripReset_CP6 "The signal shall be used by the BODY to know the user's request of resetting the Partial Mileage and Partial Hours counter coming from CP6.";
CM_ SG_ 2558533911 Btn_Dust_Fan_CP6 "The signal shall be used to know when the user's request of Dust Extraction activation/deactivation coming from CP6.";
CM_ SG_ 2558533911 Btn_FuelPumpCP6 "The signal shall be used to know when the user's request of fuel pump activation/deactivation coming from CP6.";
CM_ SG_ 2558533911 Btn_Warlight_B2_CP6 "The signal shall be used to know when the user's request of War 2 Light   activation/deactivation coming from CP6.";
CM_ SG_ 2558533911 Btn_Warlight_B1_CP6 "The signal shall be used to know when the user's request of War 1 Light  activation/deactivation coming from CP6.";
CM_ SG_ 2558533911 Btn_Low_Beam_Light_CP6 "The signal shall be used to know when the user's request of Low Beam Light activation/deactivation coming from CP6.";
CM_ SG_ 2558533911 Btn_Marker_Light_CP6 "The signal shall be used to know when the user's request of Marker Light activation/deactivation coming from CP6.";
CM_ SG_ 2558533911 Btn_Emergency_Blinker_CP6 "The signal shall be used to know when the user's request of Emergency Light activation/deactivation coming from CP6.";
CM_ SG_ 2558533911 _nu_Btn_2_01_CP6 "Not used button";
CM_ SG_ 2558533911 _nu_Btn_2_04_CP6 "Not used button";
CM_ SG_ 2558533911 _nu_Btn_2_07_CP6 "Not used button";
CM_ SG_ 2558533911 Btn_Change_h_km_CP6 "The signal shall be used by the BODY to know the user's request of changing between hour and km visualization from CP6.";
CM_ SG_ 2558533911 _nu_Btn_2_15_CP6 "Not used button";
CM_ SG_ 2558533911 _nu_Btn_2_16_CP6 "Not used button";
CM_ SG_ 2558533911 _nu_Btn_2_17_CP6 "Not used button";
CM_ SG_ 2558533911 _nu_Btn_2_18_CP6 "Not used button";
CM_ SG_ 2558533911 _nu_Btn_2_19_CP6 "Not used button";
CM_ SG_ 2558533911 _nu_Btn_2_20_CP6 "Not used button";
CM_ SG_ 2558533911 _nu_Btn_2_21_CP6 "Not used button";
CM_ SG_ 2558533911 _nu_Btn_2_22_CP6 "Not used button";
CM_ SG_ 2558533911 _nu_Btn_2_23_CP6 "Not used button";
CM_ SG_ 2558533911 _nu_Btn_2_27_CP6 "Not used button";
CM_ SG_ 2558533911 _nu_Btn_2_28_CP6 "Not used button";
CM_ SG_ 2558533911 _nu_Btn_2_29_CP6 "Not used button";
CM_ SG_ 2558533911 _nu_Btn_2_30_CP6 "Not used button";
CM_ SG_ 2558533911 _nu_Btn_2_31_CP6 "Not used button";
CM_ SG_ 2558533911 _nu_Btn_2_35_CP6 "Not used button";
CM_ SG_ 2558533911 _nu_Btn_2_36_CP6 "Not used button";
CM_ SG_ 2558533911 _nu_Btn_2_37_CP6 "Not used button";
CM_ SG_ 2558533911 _nu_Btn_2_39_CP6 "Not used button";
CM_ SG_ 2558533911 _nu_Btn_2_47_CP6 "Not used button";
CM_ SG_ 2558533911 _nu_Btn_2_48_CP6 "Not used button";
CM_ SG_ 2558533911 _nu_Btn_2_49_CP6 "Not used button";
CM_ SG_ 2558533911 _nu_Btn_2_50_CP6 "Not used button";
CM_ SG_ 2558533911 _nu_Btn_2_51_CP6 "Not used button";
CM_ SG_ 2558533911 _nu_Btn_2_52_CP6 "Not used button";
CM_ SG_ 2558533911 _nu_Btn_2_53_CP6 "Not used button";
CM_ SG_ 2558533911 _nu_Btn_2_54_CP6 "Not used button";
CM_ SG_ 2558533911 _nu_Btn_2_55_CP6 "Not used button";
CM_ SG_ 2558533911 _nu_Btn_2_56_CP6 "Not used button";
CM_ SG_ 2558533911 _nu_Btn_2_57_CP6 "Not used button";
CM_ SG_ 2558533911 _nu_Btn_2_58_CP6 "Not used button";
CM_ SG_ 2558533911 _nu_Btn_2_59_CP6 "Not used button";
CM_ SG_ 2558533911 _nu_Btn_2_60_CP6 "Not used button";
CM_ SG_ 2558533911 _nu_Btn_2_61_CP6 "Not used button";
CM_ SG_ 2558533911 _nu_Btn_2_62_CP6 "Not used button";
CM_ SG_ 2558533911 _nu_Btn_2_63_CP6 "Not used button";
CM_ BO_ 2558599479 "Message used for collecting the bushbutton status coming from the CP10 for the BC";
CM_ SG_ 2558599479 Btn_NBC_Ventilation_Low_CP10 "The signal shall be set by the CP10 to define the user's request of low NBC ventilation activation/deactivation.";
CM_ SG_ 2558599479 Btn_NBC_Ventilation_Fast_CP10 "The signal shall be set by the CP10 to define the user's request of fast NBC ventilation activation/deactivation.";
CM_ SG_ 2558599479 Btn_NBC_FilterMode_CP10 "The signal shall be set by the CP10 to define the user's request of NBC filter mode activation/deactivation.";
CM_ SG_ 2558599479 Btn_Mask_CP10 "The signal shall be set by the CP10 to define the user's request of Mask functionalities activation/deactivation.";
CM_ SG_ 2558599479 Btn_CrewAreaHeater_CP10 "The signal shall be used to know when the user's request of Hydronic Crew Area Heater activation/deactivation coming from CP10.";
CM_ SG_ 2558599479 Btn_Clima_Vent_Up_CP10 "The signal shall be used to know when the user's request of Clima Ventilation UP  activation/deactivation coming from CP10.";
CM_ SG_ 2558599479 Btn_Clima_Vent_Down_CP10 "The signal shall be used to know when the user's request of Clima Ventilation DOWN activation/deactivation coming from CP10.";
CM_ SG_ 2558599479 Btn_Clima_Temp_Up_CP10 "The signal shall be used to know when the user's request of Clima Temperature UP activation/deactivation coming from CP10.";
CM_ SG_ 2558599479 Btn_Clima_Temp_Down_CP10 "The signal shall be used to know when the user's request of Clima Temperature DOWN activation/deactivation coming from CP10.";
CM_ SG_ 2558599479 Btn_Clima_ON_AUTO_MAN_CP10 "The signal shall be used to know when the user's request of HVAC activation/deactivation coming from CP10.";
CM_ SG_ 2558599479 Btn_Clima_Compressor_CP10 "The signal shall be used to know when the user's request of HVAC AC activation/deactivation coming from CP10.";
CM_ SG_ 2558599479 Btn_NUC_Enable_CP10 "The signal shall be set by the CP10 to define the user's request of the NUC activation/deactivation.";
CM_ SG_ 2558599479 Btn_Polarity_CP10 "The signal shall be set by the CP10 to define the user's request of the polarity selection (between black hot and white hot).";
CM_ SG_ 2558599479 Btn_ROI_CP10 "The signal shall be set by the CP10 to define the user's request of the ROI selection (between TOP HALF, CENTER BLOCK, BOTTOM HALF and FULL SCREEN).";
CM_ SG_ 2558599479 Btn_TYPE_CP10 "The signal shall be set by the CP10 to define the user's request of the TYPE selection (between OPTICAL and THERMAL).";
CM_ SG_ 2558599479 Btn_ChangeView_CP10 "The signal shall be set by the CP10 to define the user's request to change view.";
CM_ SG_ 2558599479 _nu_Btn_1_03_CP10 "Not used button";
CM_ SG_ 2558599479 Btn_NBCReset_CP10 "The signal shall be set by the CP10 to define the user's request of NBC Counter Reset.";
CM_ SG_ 2558599479 _nu_Btn_1_05_CP10 "Not used button";
CM_ SG_ 2558599479 _nu_Btn_1_07_CP10 "Not used button";
CM_ SG_ 2558599479 _nu_Btn_1_08_CP10 "Not used button";
CM_ SG_ 2558599479 _nu_Btn_1_09_CP10 "Not used button";
CM_ SG_ 2558599479 _nu_Btn_1_10_CP10 "Not used button";
CM_ SG_ 2558599479 _nu_Btn_1_11_CP10 "Not used button";
CM_ SG_ 2558599479 _nu_Btn_1_12_CP10 "Not used button";
CM_ SG_ 2558599479 _nu_Btn_1_13_CP10 "Not used button";
CM_ SG_ 2558599479 _nu_Btn_1_14_CP10 "Not used button";
CM_ SG_ 2558599479 _nu_Btn_1_15_CP10 "Not used button";
CM_ SG_ 2558599479 _nu_Btn_1_23_CP10 "Not used button";
CM_ SG_ 2558599479 _nu_Btn_1_24_CP10 "Not used button";
CM_ SG_ 2558599479 _nu_Btn_1_25_CP10 "Not used button";
CM_ SG_ 2558599479 _nu_Btn_1_26_CP10 "Not used button";
CM_ SG_ 2558599479 _nu_Btn_1_27_CP10 "Not used button";
CM_ SG_ 2558599479 _nu_Btn_1_28_CP10 "Not used button";
CM_ SG_ 2558599479 _nu_Btn_1_29_CP10 "Not used button";
CM_ SG_ 2558599479 _nu_Btn_1_30_CP10 "Not used button";
CM_ SG_ 2558599479 _nu_Btn_1_31_CP10 "Not used button";
CM_ SG_ 2558599479 Btn_PerimetralVision_CP10 "The signal shall be set by the CP10 to define the user's request to perimetral vision.";
CM_ SG_ 2558599479 Btn_SelMonitor_CP10 "The signal shall be used to know when the user's request to change the monitor to be configured coming from CP10.";
CM_ SG_ 2558599479 _nu_Btn_1_39_CP10 "Not used button";
CM_ SG_ 2558599479 Btn_Sights_Washer_CP10 "The signal shall be used to know when the user's request of Sight Wsher activation/deactivation coming from CP10.";
CM_ SG_ 2558599479 Btn_SelTlc_CP10 "The signal shall be used to know when the user's request to change the camera for the selected monitor coming from CP10.";
CM_ SG_ 2558599479 Btn_SelCfg_CP10 "The signal shall be used to know when the user's request to change the configuration to be modified coming from CP10.";
CM_ SG_ 2558599479 Btn_SaveCfg_CP10 "The signal shall be used to know when the user's request to save the modified configuration coming from CP10.";
CM_ SG_ 2558599479 Btn_RestoreCfg_CP10 "The signal shall be used to know when the user's request to restore the factory configuration coming from CP10.";
CM_ SG_ 2558599479 Btn_HeaterTlc_CP10 "The signal shall be used to know when the user's request to heat the camera coming from CP10.";
CM_ SG_ 2558599479 Btn_Overlay_CP10 "The signal shall be used to know when the user's request to activate the overlay function coming from CP10.";
CM_ SG_ 2558599479 _nu_Btn_1_47_CP10 "Not used button";
CM_ SG_ 2558599479 _nu_Btn_1_48_CP10 "Not used button";
CM_ SG_ 2558599479 _nu_Btn_1_49_CP10 "Not used button";
CM_ SG_ 2558599479 _nu_Btn_1_50_CP10 "Not used button";
CM_ SG_ 2558599479 _nu_Btn_1_51_CP10 "Not used button";
CM_ SG_ 2558599479 _nu_Btn_1_52_CP10 "Not used button";
CM_ SG_ 2558599479 _nu_Btn_1_53_CP10 "Not used button";
CM_ SG_ 2558599479 _nu_Btn_1_54_CP10 "Not used button";
CM_ SG_ 2558599479 _nu_Btn_1_55_CP10 "Not used button";
CM_ SG_ 2558599479 _nu_Btn_1_56_CP10 "Not used button";
CM_ SG_ 2558599479 _nu_Btn_1_57_CP10 "Not used button";
CM_ SG_ 2558599479 _nu_Btn_1_58_CP10 "Not used button";
CM_ SG_ 2558599479 _nu_Btn_1_59_CP10 "Not used button";
CM_ SG_ 2558599479 _nu_Btn_1_60_CP10 "Not used button";
CM_ SG_ 2558599479 _nu_Btn_1_61_CP10 "Not used button";
CM_ SG_ 2558599479 _nu_Btn_1_62_CP10 "Not used button";
CM_ SG_ 2558599479 _nu_Btn_1_63_CP10 "Not used button";
BA_DEF_  "ProtocolType" STRING ;
BA_DEF_  "BusType" STRING ;
BA_DEF_  "DBName" STRING ;
BA_DEF_  "DatabaseVersion" STRING ;
BA_DEF_ BO_  "GenMsgCycleTimeFast" INT 0 3600000;
BA_DEF_ BO_  "GenMsgDelayTime" INT 0 3600000;
BA_DEF_ BO_  "GenMsgStartDelayTime" INT 0 10000;
BA_DEF_ BO_  "GenMsgSendType" ENUM  "cyclic","reserved","cyclicIfActive","reserved","reserved","reserved","reserved","reserved","noMsgSendType";
BA_DEF_ BO_  "GenMsgCycleTime" INT 0 3600000;
BA_DEF_ BO_  "GenMsgILSupport" ENUM  "No","Yes";
BA_DEF_ BO_  "VFrameFormat" ENUM  "StandardCAN","ExtendedCAN","reserved","J1939PG";
BA_DEF_ BO_  "GenMsgSendTypex" ENUM  "cyclic","reserved","cyclicIfActive","reserved","reserved","reserved","reserved","reserved","noMsgSendType";
BA_DEF_ BO_  "GenMsgRequestable" INT 0 1;
BA_DEF_ BO_  "GenMsgSencmype" ENUM  "cyclic","reserved","cyclicIfActive","reserved","reserved","reserved","reserved","reserved","noMsgSencmype";
BA_DEF_ BO_  "GenMsgSencmypex" ENUM  "cyclic","reserved","cyclicIfActive","reserved","reserved","reserved","reserved","reserved","noMsgSencmype";
BA_DEF_ BU_  "NmStationAddress" INT 0 255;
BA_DEF_ BU_  "ILUsed" ENUM  "Yes","No";
BA_DEF_ BU_  "NodeLayerModules" STRING ;
BA_DEF_ BU_  "NmJ1939Function" INT 0 255;
BA_DEF_ SG_  "GenSigSendType" ENUM  "Cyclic","OnWrite","reserved","OnChange","reserved","reserved","reserved","NoSigSendType";
BA_DEF_ SG_  "GenSigStartValue" INT 0 10000;
BA_DEF_ SG_  "GenSigEVName" STRING ;
BA_DEF_ SG_  "GenSigILSupport" ENUM  "Yes","No";
BA_DEF_ SG_  "GenSigSendTypex" ENUM  "Cyclic","OnWrite","reserved","OnChange","reserved","reserved","reserved","NoSigSendType";
BA_DEF_ SG_  "SigType" ENUM  "Default","Range","RangeSigned","ASCII","Discrete","Control","ReferencePGN","DTC","StringDelimiter","StringLength","StringLengthControl";
BA_DEF_ SG_  "GenSigSencmype" ENUM  "Cyclic","OnWrite","reserved","OnChange","reserved","reserved","reserved","NoSigSencmype";
BA_DEF_ SG_  "GenSigSencmypex" ENUM  "Cyclic","OnWrite","reserved","OnChange","reserved","reserved","reserved","NoSigSencmype";
BA_DEF_DEF_  "ProtocolType" "J1939";
BA_DEF_DEF_  "BusType" "CAN";
BA_DEF_DEF_  "DBName" "";
BA_DEF_DEF_  "DatabaseVersion" "";
BA_DEF_DEF_  "GenMsgCycleTimeFast" 0;
BA_DEF_DEF_  "GenMsgDelayTime" 0;
BA_DEF_DEF_  "GenMsgStartDelayTime" 0;
BA_DEF_DEF_  "GenMsgSendType" "noMsgSendType";
BA_DEF_DEF_  "GenMsgCycleTime" 0;
BA_DEF_DEF_  "GenMsgILSupport" "Yes";
BA_DEF_DEF_  "VFrameFormat" "J1939PG";
BA_DEF_DEF_  "GenMsgSendTypex" "noMsgSendType";
BA_DEF_DEF_  "GenMsgRequestable" 1;
BA_DEF_DEF_  "GenMsgSencmype" "noMsgSencmype";
BA_DEF_DEF_  "GenMsgSencmypex" "noMsgSencmype";
BA_DEF_DEF_  "NmStationAddress" 254;
BA_DEF_DEF_  "ILUsed" "Yes";
BA_DEF_DEF_  "NodeLayerModules" "CANoeILNLVector.dll";
BA_DEF_DEF_  "NmJ1939Function" 0;
BA_DEF_DEF_  "GenSigSendType" "NoSigSendType";
BA_DEF_DEF_  "GenSigStartValue" 0;
BA_DEF_DEF_  "GenSigEVName" "Env@Nodename_@Signame";
BA_DEF_DEF_  "GenSigILSupport" "Yes";
BA_DEF_DEF_  "GenSigSendTypex" "NoSigSendType";
BA_DEF_DEF_  "SigType" "Default";
BA_DEF_DEF_  "GenSigSencmype" "NoSigSencmype";
BA_DEF_DEF_  "GenSigSencmypex" "NoSigSencmype";
BA_ "DatabaseVersion" "5dD";
BA_ "ProtocolType" "CAN";
BA_ "DBName" "C2_SDB";
BA_ "NmStationAddress" BU_ ALARMS_RELAY 147;
BA_ "NmStationAddress" BU_ RUR 140;
BA_ "NmStationAddress" BU_ RUF 137;
BA_ "NmStationAddress" BU_ LOGBOX 28;
BA_ "NmStationAddress" BU_ HVAC 25;
BA_ "NmStationAddress" BU_ CP6 23;
BA_ "NmStationAddress" BU_ CP10 55;
BA_ "NmStationAddress" BU_ RUC 138;
BA_ "NmStationAddress" BU_ BC 33;
BA_ "NmStationAddress" BU_ BMS1_SDB 161;
BA_ "NmStationAddress" BU_ BMS2_SDB 162;
BA_ "NmJ1939Function" BU_ _TESTER 255;
BA_ "NmStationAddress" BU_ _TESTER 29;
BA_ "NmStationAddress" BU_ NC_SENSOR 193;
BA_ "NmStationAddress" BU_ IVS 84;
BA_ "GenMsgCycleTime" BO_ 2558534035 100;
BA_ "GenMsgSendTypex" BO_ 2559194913 0;
BA_ "GenMsgCycleTime" BO_ 2559194913 100;
BA_ "GenMsgSendType" BO_ 2559194913 0;
BA_ "GenMsgSendTypex" BO_ 2558656281 0;
BA_ "GenMsgCycleTime" BO_ 2558656281 1000;
BA_ "GenMsgSendType" BO_ 2558656281 0;
BA_ "GenMsgCycleTime" BO_ 2559246113 100;
BA_ "GenMsgSendType" BO_ 2559246113 2;
BA_ "GenMsgSendTypex" BO_ 2559129377 0;
BA_ "GenMsgCycleTime" BO_ 2559129377 1000;
BA_ "GenMsgSendType" BO_ 2559129377 0;
BA_ "GenMsgSendTypex" BO_ 2559063841 0;
BA_ "GenMsgCycleTime" BO_ 2559063841 100;
BA_ "GenMsgSendType" BO_ 2559063841 0;
BA_ "GenMsgCycleTime" BO_ 2566834942 1000;
BA_ "GenMsgSendTypex" BO_ 2558533913 0;
BA_ "GenMsgCycleTime" BO_ 2558533913 1000;
BA_ "GenMsgSendType" BO_ 2558533913 0;
BA_ "GenMsgSendTypex" BO_ 2558590745 0;
BA_ "GenMsgCycleTime" BO_ 2558590745 100;
BA_ "GenMsgSendType" BO_ 2558590745 0;
BA_ "GenMsgCycleTime" BO_ 2558664983 1000;
BA_ "GenMsgSendType" BO_ 2558664983 0;
BA_ "GenMsgCycleTime" BO_ 2558665015 1000;
BA_ "GenMsgSendType" BO_ 2558665015 0;
BA_ "GenMsgSendTypex" BO_ 2558656289 0;
BA_ "GenMsgCycleTime" BO_ 2558656289 100;
BA_ "GenMsgSendType" BO_ 2558656289 0;
BA_ "GenMsgSendTypex" BO_ 2566846241 0;
BA_ "GenMsgCycleTime" BO_ 2566846241 100;
BA_ "GenMsgSendType" BO_ 2566846241 0;
BA_ "GenMsgSendTypex" BO_ 2558932769 0;
BA_ "GenMsgCycleTime" BO_ 2558932769 1000;
BA_ "GenMsgSendType" BO_ 2558932769 0;
BA_ "GenMsgCycleTime" BO_ 2566842000 1000;
BA_ "GenMsgSendType" BO_ 2566842000 2;
BA_ "GenMsgSendTypex" BO_ 2558736161 0;
BA_ "GenMsgCycleTime" BO_ 2558736161 100;
BA_ "GenMsgSendType" BO_ 2558736161 0;
BA_ "GenMsgSendTypex" BO_ 2558867233 0;
BA_ "GenMsgCycleTime" BO_ 2558867233 100;
BA_ "GenMsgSendType" BO_ 2558867233 0;
BA_ "GenMsgSendTypex" BO_ 2558998305 0;
BA_ "GenMsgCycleTime" BO_ 2558998305 1000;
BA_ "GenMsgSendType" BO_ 2558998305 0;
BA_ "GenMsgSendTypex" BO_ 2558801697 0;
BA_ "GenMsgCycleTime" BO_ 2558801697 100;
BA_ "GenMsgSendType" BO_ 2558801697 0;
BA_ "GenMsgSendTypex" BO_ 2558670625 0;
BA_ "GenMsgCycleTime" BO_ 2558670625 100;
BA_ "GenMsgSendType" BO_ 2558670625 0;
BA_ "GenMsgSendTypex" BO_ 2558605089 0;
BA_ "GenMsgCycleTime" BO_ 2558605089 100;
BA_ "GenMsgSendType" BO_ 2558605089 0;
BA_ "GenMsgSendTypex" BO_ 2558539553 0;
BA_ "GenMsgCycleTime" BO_ 2558539553 100;
BA_ "GenMsgSendType" BO_ 2558539553 0;
BA_ "GenMsgCycleTime" BO_ 2558599447 100;
BA_ "GenMsgSendType" BO_ 2558599447 0;
BA_ "GenMsgCycleTime" BO_ 2558533911 100;
BA_ "GenMsgSendType" BO_ 2558533911 0;
BA_ "GenMsgCycleTime" BO_ 2558599479 100;
BA_ "GenMsgSendType" BO_ 2558599479 0;
BA_ "GenSigStartValue" SG_ 2558656281 HVAC_VehicleAverageTemp 40;
BA_ "GenSigStartValue" SG_ 2558656281 HVAC_OutputAverageTemp 40;
BA_ "GenSigStartValue" SG_ 2558656281 HVAC_MaskAverageTemp 40;
BA_ "GenSigStartValue" SG_ 2558656281 HVAC_EvaporatorAverageTemp 40;
BA_ "GenSigStartValue" SG_ 2566842000 Month_SDB 1;
BA_ "GenSigStartValue" SG_ 2566842000 Day_SDB 1;
BA_ "GenSigStartValue" SG_ 2566842000 Local_Minute_Offset_SDB 125;
BA_ "GenSigStartValue" SG_ 2566842000 Local_Hour_Offset_SDB 125;
BA_ "GenSigStartValue" SG_ 2558867233 Transmission_Oil_Level 125;
BA_ "GenSigStartValue" SG_ 2558867233 Secondary_Coolant_Temp 40;
BA_ "GenSigStartValue" SG_ 2558867233 Turret_Angle 125;
VAL_ 2558534035 AlarmRelayDeactivation 1 "ON" 0 "OFF" ;
VAL_ 2558534035 AlarmRelayActivation 1 "ON" 0 "OFF" ;
VAL_ 2558534035 AlarmBlackout 1 "BLACKOUT" 0 "NO_BLACKOUT" ;
VAL_ 2559194913 Generic_Alarm 3 "NOT_AVAILABLE" 2 "NOT_USED" 1 "ALARM_ON" 0 "ALARM_OFF" ;
VAL_ 2559194913 Battery_Network 3 "NOT_AVAILABLE" 2 "VDB" 1 "ADB" 0 "SDB" ;
VAL_ 2559194913 Temperature_Alarm 3 "NOT_AVAILABLE" 2 "ALARM_HIGH_TEMPERATURE" 1 "WARNING_LOW_TEMPERATURE" 0 "ALARM_OFF" ;
VAL_ 2559194913 Status_of_Health 3 "NotAvailable" 2 "Health_is_good" 1 "Health_is_medium" 0 "Health_is_poor" ;
VAL_ 2559194913 Battery_Number 15 "NOT_AVAILABLE" 14 "NOT_USED" 13 "NOT_USED" 12 "NOT_USED" 11 "NOT_USED" 10 "NOT_USED" 9 "NOT_USED" 8 "NOT_USED" 7 "POSITION_8" 6 "POSITION_7" 5 "POSITION_6" 4 "POSITION_5" 3 "POSITION_4" 2 "POSITION_3" 1 "POSITION_2" 0 "POSITION_1" ;
VAL_ 2559063841 Lamp_Fuel_TOT_LvlLow 3 "NOT_AVAILABLE" 2 "LAMP_BLINK" 1 "LAMP_ON" 0 "LAMP_OFF" ;
VAL_ 2559063841 Lamp_Fuel_REAR_RIGHT_LvlLow 3 "NOT_AVAILABLE" 2 "LAMP_BLINK" 1 "LAMP_ON" 0 "LAMP_OFF" ;
VAL_ 2559063841 Lamp_Fuel_REAR_LEFT_LvlLow 3 "NOT_AVAILABLE" 2 "LAMP_BLINK" 1 "LAMP_ON" 0 "LAMP_OFF" ;
VAL_ 2559063841 Lamp_Fuel_FRONT_LvlLow 3 "NOT_AVAILABLE" 2 "LAMP_BLINK" 1 "LAMP_ON" 0 "LAMP_OFF" ;
VAL_ 2559063841 Lamp_Fuel_CENTRAL_LvlLow 3 "NOT_AVAILABLE" 2 "LAMP_BLINK" 1 "LAMP_ON" 0 "LAMP_OFF" ;
VAL_ 2566834942 FailureModeIdentifier10 31 "NotAvailable" 30 "NotAvailable" 29 "NotAvailable" 28 "NotAvailable" 27 "NotAvailable" 26 "NotAvailable" 25 "NotAvailable" 24 "NotAvailable" 23 "NotAvailable" 22 "NotAvailable" 21 "NotAvailable" 20 "NotAvailable" 19 "ReceivedNetworkDataInError" 18 "BelowNormalModeratelySevere" 17 "BelowNormalLeastSevere" 16 "AboveNormalModeratelySevere" 15 "AboveNormalLeastSevere" 14 "SpecialIntstructions" 13 "OutOfCalibration" 12 "BadIntelligentDevice" 11 "RootCauseNotKnown" 10 "AbnormalRateOfChange" 9 "AbnormalUpdateRate" 8 "AbnormalFrequency" 7 "MechanicalSystemNotResponding" 6 "CurrentAboveNormal" 5 "CurrentBelowNormal" 4 "VoltageBelowNormal" 3 "VoltageAboveNormal" 2 "DataErratic" 1 "BelowNormalMostSevere" 0 "AboveNormalMostSevere" ;
VAL_ 2566834942 FailureModeIdentifier9 31 "NotAvailable" 30 "NotAvailable" 29 "NotAvailable" 28 "NotAvailable" 27 "NotAvailable" 26 "NotAvailable" 25 "NotAvailable" 24 "NotAvailable" 23 "NotAvailable" 22 "NotAvailable" 21 "NotAvailable" 20 "NotAvailable" 19 "ReceivedNetworkDataInError" 18 "BelowNormalModeratelySevere" 17 "BelowNormalLeastSevere" 16 "AboveNormalModeratelySevere" 15 "AboveNormalLeastSevere" 14 "SpecialIntstructions" 13 "OutOfCalibration" 12 "BadIntelligentDevice" 11 "RootCauseNotKnown" 10 "AbnormalRateOfChange" 9 "AbnormalUpdateRate" 8 "AbnormalFrequency" 7 "MechanicalSystemNotResponding" 6 "CurrentAboveNormal" 5 "CurrentBelowNormal" 4 "VoltageBelowNormal" 3 "VoltageAboveNormal" 2 "DataErratic" 1 "BelowNormalMostSevere" 0 "AboveNormalMostSevere" ;
VAL_ 2566834942 FailureModeIdentifier8 31 "NotAvailable" 30 "NotAvailable" 29 "NotAvailable" 28 "NotAvailable" 27 "NotAvailable" 26 "NotAvailable" 25 "NotAvailable" 24 "NotAvailable" 23 "NotAvailable" 22 "NotAvailable" 21 "NotAvailable" 20 "NotAvailable" 19 "ReceivedNetworkDataInError" 18 "BelowNormalModeratelySevere" 17 "BelowNormalLeastSevere" 16 "AboveNormalModeratelySevere" 15 "AboveNormalLeastSevere" 14 "SpecialIntstructions" 13 "OutOfCalibration" 12 "BadIntelligentDevice" 11 "RootCauseNotKnown" 10 "AbnormalRateOfChange" 9 "AbnormalUpdateRate" 8 "AbnormalFrequency" 7 "MechanicalSystemNotResponding" 6 "CurrentAboveNormal" 5 "CurrentBelowNormal" 4 "VoltageBelowNormal" 3 "VoltageAboveNormal" 2 "DataErratic" 1 "BelowNormalMostSevere" 0 "AboveNormalMostSevere" ;
VAL_ 2566834942 FailureModeIdentifier7 31 "NotAvailable" 30 "NotAvailable" 29 "NotAvailable" 28 "NotAvailable" 27 "NotAvailable" 26 "NotAvailable" 25 "NotAvailable" 24 "NotAvailable" 23 "NotAvailable" 22 "NotAvailable" 21 "NotAvailable" 20 "NotAvailable" 19 "ReceivedNetworkDataInError" 18 "BelowNormalModeratelySevere" 17 "BelowNormalLeastSevere" 16 "AboveNormalModeratelySevere" 15 "AboveNormalLeastSevere" 14 "SpecialIntstructions" 13 "OutOfCalibration" 12 "BadIntelligentDevice" 11 "RootCauseNotKnown" 10 "AbnormalRateOfChange" 9 "AbnormalUpdateRate" 8 "AbnormalFrequency" 7 "MechanicalSystemNotResponding" 6 "CurrentAboveNormal" 5 "CurrentBelowNormal" 4 "VoltageBelowNormal" 3 "VoltageAboveNormal" 2 "DataErratic" 1 "BelowNormalMostSevere" 0 "AboveNormalMostSevere" ;
VAL_ 2566834942 FailureModeIdentifier6 31 "NotAvailable" 30 "NotAvailable" 29 "NotAvailable" 28 "NotAvailable" 27 "NotAvailable" 26 "NotAvailable" 25 "NotAvailable" 24 "NotAvailable" 23 "NotAvailable" 22 "NotAvailable" 21 "NotAvailable" 20 "NotAvailable" 19 "ReceivedNetworkDataInError" 18 "BelowNormalModeratelySevere" 17 "BelowNormalLeastSevere" 16 "AboveNormalModeratelySevere" 15 "AboveNormalLeastSevere" 14 "SpecialIntstructions" 13 "OutOfCalibration" 12 "BadIntelligentDevice" 11 "RootCauseNotKnown" 10 "AbnormalRateOfChange" 9 "AbnormalUpdateRate" 8 "AbnormalFrequency" 7 "MechanicalSystemNotResponding" 6 "CurrentAboveNormal" 5 "CurrentBelowNormal" 4 "VoltageBelowNormal" 3 "VoltageAboveNormal" 2 "DataErratic" 1 "BelowNormalMostSevere" 0 "AboveNormalMostSevere" ;
VAL_ 2566834942 FailureModeIdentifier5 31 "NotAvailable" 30 "NotAvailable" 29 "NotAvailable" 28 "NotAvailable" 27 "NotAvailable" 26 "NotAvailable" 25 "NotAvailable" 24 "NotAvailable" 23 "NotAvailable" 22 "NotAvailable" 21 "NotAvailable" 20 "NotAvailable" 19 "ReceivedNetworkDataInError" 18 "BelowNormalModeratelySevere" 17 "BelowNormalLeastSevere" 16 "AboveNormalModeratelySevere" 15 "AboveNormalLeastSevere" 14 "SpecialIntstructions" 13 "OutOfCalibration" 12 "BadIntelligentDevice" 11 "RootCauseNotKnown" 10 "AbnormalRateOfChange" 9 "AbnormalUpdateRate" 8 "AbnormalFrequency" 7 "MechanicalSystemNotResponding" 6 "CurrentAboveNormal" 5 "CurrentBelowNormal" 4 "VoltageBelowNormal" 3 "VoltageAboveNormal" 2 "DataErratic" 1 "BelowNormalMostSevere" 0 "AboveNormalMostSevere" ;
VAL_ 2566834942 FailureModeIdentifier4 31 "NotAvailable" 30 "NotAvailable" 29 "NotAvailable" 28 "NotAvailable" 27 "NotAvailable" 26 "NotAvailable" 25 "NotAvailable" 24 "NotAvailable" 23 "NotAvailable" 22 "NotAvailable" 21 "NotAvailable" 20 "NotAvailable" 19 "ReceivedNetworkDataInError" 18 "BelowNormalModeratelySevere" 17 "BelowNormalLeastSevere" 16 "AboveNormalModeratelySevere" 15 "AboveNormalLeastSevere" 14 "SpecialIntstructions" 13 "OutOfCalibration" 12 "BadIntelligentDevice" 11 "RootCauseNotKnown" 10 "AbnormalRateOfChange" 9 "AbnormalUpdateRate" 8 "AbnormalFrequency" 7 "MechanicalSystemNotResponding" 6 "CurrentAboveNormal" 5 "CurrentBelowNormal" 4 "VoltageBelowNormal" 3 "VoltageAboveNormal" 2 "DataErratic" 1 "BelowNormalMostSevere" 0 "AboveNormalMostSevere" ;
VAL_ 2566834942 FailureModeIdentifier3 31 "NotAvailable" 30 "NotAvailable" 29 "NotAvailable" 28 "NotAvailable" 27 "NotAvailable" 26 "NotAvailable" 25 "NotAvailable" 24 "NotAvailable" 23 "NotAvailable" 22 "NotAvailable" 21 "NotAvailable" 20 "NotAvailable" 19 "ReceivedNetworkDataInError" 18 "BelowNormalModeratelySevere" 17 "BelowNormalLeastSevere" 16 "AboveNormalModeratelySevere" 15 "AboveNormalLeastSevere" 14 "SpecialIntstructions" 13 "OutOfCalibration" 12 "BadIntelligentDevice" 11 "RootCauseNotKnown" 10 "AbnormalRateOfChange" 9 "AbnormalUpdateRate" 8 "AbnormalFrequency" 7 "MechanicalSystemNotResponding" 6 "CurrentAboveNormal" 5 "CurrentBelowNormal" 4 "VoltageBelowNormal" 3 "VoltageAboveNormal" 2 "DataErratic" 1 "BelowNormalMostSevere" 0 "AboveNormalMostSevere" ;
VAL_ 2566834942 FlashRedStopLamp 3 "UnavailableDoNotFlash" 2 "Reserved" 1 "FastFlash" 0 "SlowFlash" ;
VAL_ 2566834942 FlashProtectLamp 3 "UnavailableDoNotFlash" 2 "Reserved" 1 "FastFlash" 0 "SlowFlash" ;
VAL_ 2566834942 FlashMalfuncIndicatorLamp 3 "UnavailableDoNotFlash" 2 "Reserved" 1 "FastFlash" 0 "SlowFlash" ;
VAL_ 2566834942 FlashAmberWarningLamp 3 "UnavailableDoNotFlash" 2 "Reserved" 1 "FastFlash" 0 "SlowFlash" ;
VAL_ 2566834942 MalfunctionIndicatorLampStatus 3 "NotAvailable" 2 "Reserved" 1 "LampOn" 0 "LampOff" ;
VAL_ 2566834942 AmberWarningLampStatus 3 "NotAvailable" 2 "Reserved" 1 "LampOn" 0 "LampOff" ;
VAL_ 2566834942 SPNConversionMethod1 1 "Version_1_2_3_format" 0 "Old_conversion_method" ;
VAL_ 2566834942 FailureModeIdentifier1 31 "NotAvailable" 30 "NotAvailable" 29 "NotAvailable" 28 "NotAvailable" 27 "NotAvailable" 26 "NotAvailable" 25 "NotAvailable" 24 "NotAvailable" 23 "NotAvailable" 22 "NotAvailable" 21 "NotAvailable" 20 "NotAvailable" 19 "ReceivedNetworkDataInError" 18 "BelowNormalModeratelySevere" 17 "BelowNormalLeastSevere" 16 "AboveNormalModeratelySevere" 15 "AboveNormalLeastSevere" 14 "SpecialIntstructions" 13 "OutOfCalibration" 12 "BadIntelligentDevice" 11 "RootCauseNotKnown" 10 "AbnormalRateOfChange" 9 "AbnormalUpdateRate" 8 "AbnormalFrequency" 7 "MechanicalSystemNotResponding" 6 "CurrentAboveNormal" 5 "CurrentBelowNormal" 4 "VoltageBelowNormal" 3 "VoltageAboveNormal" 2 "DataErratic" 1 "BelowNormalMostSevere" 0 "AboveNormalMostSevere" ;
VAL_ 2566834942 RedStopLampState 3 "NotAvailable" 2 "Reserved" 1 "LampOn" 0 "LampOff" ;
VAL_ 2566834942 ProtectLampStatus 3 "NotAvailable" 2 "Reserved" 1 "LampOn" 0 "LampOff" ;
VAL_ 2566834942 FailureModeIdentifier2 31 "NotAvailable" 30 "NotAvailable" 29 "NotAvailable" 28 "NotAvailable" 27 "NotAvailable" 26 "NotAvailable" 25 "NotAvailable" 24 "NotAvailable" 23 "NotAvailable" 22 "NotAvailable" 21 "NotAvailable" 20 "NotAvailable" 19 "ReceivedNetworkDataInError" 18 "BelowNormalModeratelySevere" 17 "BelowNormalLeastSevere" 16 "AboveNormalModeratelySevere" 15 "AboveNormalLeastSevere" 14 "SpecialIntstructions" 13 "OutOfCalibration" 12 "BadIntelligentDevice" 11 "RootCauseNotKnown" 10 "AbnormalRateOfChange" 9 "AbnormalUpdateRate" 8 "AbnormalFrequency" 7 "MechanicalSystemNotResponding" 6 "CurrentAboveNormal" 5 "CurrentBelowNormal" 4 "VoltageBelowNormal" 3 "VoltageAboveNormal" 2 "DataErratic" 1 "BelowNormalMostSevere" 0 "AboveNormalMostSevere" ;
VAL_ 2566834942 SPNConversionMethod10 1 "Version_1_2_3_format" 0 "Old_conversion_method" ;
VAL_ 2566834942 SPNConversionMethod9 1 "Version_1_2_3_format" 0 "Old_conversion_method" ;
VAL_ 2566834942 SPNConversionMethod8 1 "Version_1_2_3_format" 0 "Old_conversion_method" ;
VAL_ 2566834942 SPNConversionMethod7 1 "Version_1_2_3_format" 0 "Old_conversion_method" ;
VAL_ 2566834942 SPNConversionMethod6 1 "Version_1_2_3_format" 0 "Old_conversion_method" ;
VAL_ 2566834942 SPNConversionMethod5 1 "Version_1_2_3_format" 0 "Old_conversion_method" ;
VAL_ 2566834942 SPNConversionMethod4 1 "Version_1_2_3_format" 0 "Old_conversion_method" ;
VAL_ 2566834942 SPNConversionMethod3 1 "Version_1_2_3_format" 0 "Old_conversion_method" ;
VAL_ 2566834942 SPNConversionMethod2 1 "Version_1_2_3_format" 0 "Old_conversion_method" ;
VAL_ 2558533913 AC_NET_SW_Type 3 "NOT_OK" 2 "OK_x_C2" 1 "NOT_OK" 0 "NOT_OK" ;
VAL_ 2558533913 AC_NET_Network_Status 3 "NOT_AVAILABLE" 2 "KEEP_ALIVE" 1 "READY_TO_SLEEP" 0 "NORMAL" ;
VAL_ 2558590745 AC_Auto_Manual_Lamp 3 "NOT_AVAILABLE" 2 "LAMP_MANUAL" 1 "LAMP_AUTO" 0 "LAMP_OFF" ;
VAL_ 2558590745 AC_Compressor_lamp 3 "NOT_AVAILABLE" 2 "LAMP_BLINK" 1 "LAMP_ON" 0 "LAMP_OFF" ;
VAL_ 2558590745 AC_Mask_lamp 3 "NOT_AVAILABLE" 2 "LAMP_BLINK" 1 "LAMP_ON" 0 "LAMP_OFF" ;
VAL_ 2558590745 MASK_Valve_Request 3 "FAULT" 2 "NOT_USED" 1 "ON" 0 "OFF" ;
VAL_ 2558590745 AC_Hot_Water_Request 3 "FAULT" 2 "NOT_USED" 1 "ON" 0 "OFF" ;
VAL_ 2558590745 AC_Compressor_Request 3 "FAULT" 2 "NOT_USED" 1 "ON" 0 "OFF" ;
VAL_ 2558664983 CP6_SW_Type 3 "NOT_OK" 2 "OK_x_C2" 1 "NOT_OK" 0 "NOT_OK" ;
VAL_ 2558664983 _nu_CP6_Network_Status 3 "NOT_AVAILABLE" 2 "KEEP_ALIVE" 1 "READY_TO_SLEEP" 0 "NORMAL" ;
VAL_ 2558665015 CP10_SW_Type 3 "NOT_OK" 2 "OK_x_C2" 1 "NOT_OK" 0 "NOT_OK" ;
VAL_ 2558665015 _nu_CP10_Network_Status 3 "NOT_AVAILABLE" 2 "KEEP_ALIVE" 1 "READY_TO_SLEEP" 0 "NORMAL" ;
VAL_ 2558736161 Lamp_NC_Sensor_NC_Alarm 3 "NOT_AVAILABLE" 2 "LAMP_BLINK" 1 "LAMP_ON" 0 "LAMP_OFF" ;
VAL_ 2558736161 Lamp_Transmission_Oil_Level 3 "NOT_AVAILABLE" 2 "LAMP_BLINK" 1 "LAMP_ON" 0 "LAMP_OFF" ;
VAL_ 2558736161 Lamp_NC_Sensor_C_Alarm 3 "NOT_AVAILABLE" 2 "LAMP_BLINK" 1 "LAMP_ON" 0 "LAMP_OFF" ;
VAL_ 2558736161 Lamp_NC_Sensor_N_Alarm 3 "NOT_AVAILABLE" 2 "LAMP_BLINK" 1 "LAMP_ON" 0 "LAMP_OFF" ;
VAL_ 2558736161 Lamp_NBC_PreFilterClogged 3 "NOT_AVAILABLE" 2 "LAMP_BLINK" 1 "LAMP_ON" 0 "LAMP_OFF" ;
VAL_ 2558736161 Lamp_WaterInFuel 3 "NOT_AVAILABLE" 2 "LAMP_BLINK" 1 "LAMP_ON" 0 "LAMP_OFF" ;
VAL_ 2558736161 Lamp_Engine_Oil_Level 3 "NOT_AVAILABLE" 2 "LAMP_BLINK" 1 "LAMP_ON" 0 "LAMP_OFF" ;
VAL_ 2558736161 Lamp_Engine_AirFilter_Clogged 3 "NOT_AVAILABLE" 2 "LAMP_BLINK" 1 "LAMP_ON" 0 "LAMP_OFF" ;
VAL_ 2558736161 Lamp_Engine_Coolant_Level_Low 3 "NOT_AVAILABLE" 2 "LAMP_RED_ON" 1 "LAMP_YELLOW_ON" 0 "LAMP_OFF" ;
VAL_ 2558736161 Lamp_Cooling_Fan_Fault 3 "NOT_AVAILABLE" 2 "LAMP_RED_ON" 1 "LAMP_YELLOW_ON" 0 "LAMP_OFF" ;
VAL_ 2558736161 Lamp_Fuel_Filter_Clogged 7 "NOT_USED" 6 "NOT_USED" 5 "NOT_USED" 4 "NOT_USED" 3 "LAMP_ALLFILTER_ERROR_ON" 2 "LAMP_PREFILTER_ERROR_ON" 1 "LAMP_FILTER_ERROR_ON" 0 "LAMP_OFF" ;
VAL_ 2558736161 Lamp_Services_AirPressure_Low 3 "NOT_AVAILABLE" 2 "LAMP_BLINK" 1 "LAMP_ON" 0 "LAMP_OFF" ;
VAL_ 2558736161 Lamp_Powersteering1LowPress 3 "NOT_AVAILABLE" 2 "LAMP_BLINK" 1 "LAMP_ON" 0 "LAMP_OFF" ;
VAL_ 2558736161 Lamp_Powersteering2LowPress 3 "NOT_AVAILABLE" 2 "LAMP_BLINK" 1 "LAMP_ON" 0 "LAMP_OFF" ;
VAL_ 2558736161 Lamp_PowersteeringLowOilLevel 3 "NOT_AVAILABLE" 2 "LAMP_BLINK" 1 "LAMP_ON" 0 "LAMP_OFF" ;
VAL_ 2558736161 Lamp_Pneumatic_Park_Brake 3 "NOT_AVAILABLE" 2 "LAMP_BLINK" 1 "LAMP_ON" 0 "LAMP_OFF" ;
VAL_ 2558736161 Lamp_Mechanical_Park_Brake 3 "NOT_AVAILABLE" 2 "LAMP_BLINK" 1 "LAMP_ON" 0 "LAMP_OFF" ;
VAL_ 2558736161 Lamp_NBC_Fault 3 "NOT_AVAILABLE" 2 "LAMP_BLINK" 1 "LAMP_ON" 0 "LAMP_OFF" ;
VAL_ 2558736161 Lamp_NBC_LowPressure 3 "NOT_AVAILABLE" 2 "LAMP_BLINK" 1 "LAMP_ON" 0 "LAMP_OFF" ;
VAL_ 2558736161 Lamp_NBC_FilterClogged 3 "NOT_AVAILABLE" 2 "LAMP_BLINK" 1 "LAMP_ON" 0 "LAMP_OFF" ;
VAL_ 2558736161 Lamp_Gear_Oil_Temp_High 3 "NOT_AVAILABLE" 2 "LAMP_RED_ON" 1 "LAMP_YELLOW_ON" 0 "LAMP_OFF" ;
VAL_ 2558736161 Lamp_Brake_LowPressure 7 "NOT_USED" 6 "NOT_USED" 5 "NOT_USED" 4 "NOT_USED" 3 "LAMP_ERROR_A" 2 "LAMP_ERROR_2" 1 "LAMP_ERROR_1" 0 "LAMP_OFF" ;
VAL_ 2558736161 Lamp_Alternator 3 "NOT_AVAILABLE" 2 "LAMP_BLINK" 1 "LAMP_ON" 0 "LAMP_OFF" ;
VAL_ 2558736161 Lamp_Fuel_Temp_High 3 "NOT_AVAILABLE" 2 "LAMP_BLINK" 1 "LAMP_ON" 0 "LAMP_OFF" ;
VAL_ 2558736161 Lamp_NBC_FilterInstalled 3 "NOT_AVAILABLE" 2 "LAMP_BLINK" 1 "LAMP_ON" 0 "LAMP_OFF" ;
VAL_ 2558736161 Lamp_Battle_Short 3 "NOT_AVAILABLE" 2 "LAMP_BLINK" 1 "LAMP_ON" 0 "LAMP_OFF" ;
VAL_ 2558736161 Lamp_Battle_Switch 3 "NOT_AVAILABLE" 2 "LAMP_BLINK" 1 "LAMP_ON" 0 "LAMP_OFF" ;
VAL_ 2558736161 Lamp_Brake_LowOilLevel 3 "NOT_AVAILABLE" 2 "LAMP_BLINK" 1 "LAMP_ON" 0 "LAMP_OFF" ;
VAL_ 2558736161 Lamp_EngineCoolant1TempHigh 3 "NOT_AVAILABLE" 2 "LAMP_RED_ON" 1 "LAMP_YELLOW_ON" 0 "LAMP_OFF" ;
VAL_ 2558736161 Lamp_EngineCoolant2TempHigh 3 "NOT_AVAILABLE" 2 "LAMP_RED_ON" 1 "LAMP_YELLOW_ON" 0 "LAMP_OFF" ;
VAL_ 2558998305 POWERSTR_SPEED_TOO_HIGH 1 "WARNING_ACTIVE" 0 "WARNING_NOT_ACTIVE" ;
VAL_ 2558998305 _nu_Warnings_bit63 1 "WARNING_ACTIVE" 0 "WARNING_NOT_ACTIVE" ;
VAL_ 2558998305 _nu_Warnings_bit62 1 "WARNING_ACTIVE" 0 "WARNING_NOT_ACTIVE" ;
VAL_ 2558998305 _nu_Warnings_bit61 1 "WARNING_ACTIVE" 0 "WARNING_NOT_ACTIVE" ;
VAL_ 2558998305 _nu_Warnings_bit60 1 "WARNING_ACTIVE" 0 "WARNING_NOT_ACTIVE" ;
VAL_ 2558998305 _nu_Warnings_bit59 1 "WARNING_ACTIVE" 0 "WARNING_NOT_ACTIVE" ;
VAL_ 2558998305 _nu_Warnings_bit58 1 "WARNING_ACTIVE" 0 "WARNING_NOT_ACTIVE" ;
VAL_ 2558998305 _nu_Warnings_bit57 1 "WARNING_ACTIVE" 0 "WARNING_NOT_ACTIVE" ;
VAL_ 2558998305 _nu_Warnings_bit56 1 "WARNING_ACTIVE" 0 "WARNING_NOT_ACTIVE" ;
VAL_ 2558998305 _nu_Warnings_bit55 1 "WARNING_ACTIVE" 0 "WARNING_NOT_ACTIVE" ;
VAL_ 2558998305 _nu_Warnings_bit54 1 "WARNING_ACTIVE" 0 "WARNING_NOT_ACTIVE" ;
VAL_ 2558998305 _nu_Warnings_bit53 1 "WARNING_ACTIVE" 0 "WARNING_NOT_ACTIVE" ;
VAL_ 2558998305 _nu_Warnings_bit52 1 "WARNING_ACTIVE" 0 "WARNING_NOT_ACTIVE" ;
VAL_ 2558998305 _nu_Warnings_bit51 1 "WARNING_ACTIVE" 0 "WARNING_NOT_ACTIVE" ;
VAL_ 2558998305 _nu_Warnings_bit50 1 "WARNING_ACTIVE" 0 "WARNING_NOT_ACTIVE" ;
VAL_ 2558998305 _nu_Warnings_bit49 1 "WARNING_ACTIVE" 0 "WARNING_NOT_ACTIVE" ;
VAL_ 2558998305 _nu_Warnings_bit48 1 "WARNING_ACTIVE" 0 "WARNING_NOT_ACTIVE" ;
VAL_ 2558998305 _nu_Warnings_bit47 1 "WARNING_ACTIVE" 0 "WARNING_NOT_ACTIVE" ;
VAL_ 2558998305 _nu_Warnings_bit46 1 "WARNING_ACTIVE" 0 "WARNING_NOT_ACTIVE" ;
VAL_ 2558998305 _nu_Warnings_bit45 1 "WARNING_ACTIVE" 0 "WARNING_NOT_ACTIVE" ;
VAL_ 2558998305 _nu_Warnings_bit44 1 "WARNING_ACTIVE" 0 "WARNING_NOT_ACTIVE" ;
VAL_ 2558998305 _nu_Warnings_bit43 1 "WARNING_ACTIVE" 0 "WARNING_NOT_ACTIVE" ;
VAL_ 2558998305 _nu_Warnings_bit42 1 "WARNING_ACTIVE" 0 "WARNING_NOT_ACTIVE" ;
VAL_ 2558998305 _nu_Warnings_bit41 1 "WARNING_ACTIVE" 0 "WARNING_NOT_ACTIVE" ;
VAL_ 2558998305 _nu_Warnings_bit40 1 "WARNING_ACTIVE" 0 "WARNING_NOT_ACTIVE" ;
VAL_ 2558998305 _nu_Warnings_bit39 1 "WARNING_ACTIVE" 0 "WARNING_NOT_ACTIVE" ;
VAL_ 2558998305 _nu_Warnings_bit38 1 "WARNING_ACTIVE" 0 "WARNING_NOT_ACTIVE" ;
VAL_ 2558998305 _nu_Warnings_bit37 1 "WARNING_ACTIVE" 0 "WARNING_NOT_ACTIVE" ;
VAL_ 2558998305 _nu_Warnings_bit36 1 "WARNING_ACTIVE" 0 "WARNING_NOT_ACTIVE" ;
VAL_ 2558998305 _nu_Warnings_bit35 1 "WARNING_ACTIVE" 0 "WARNING_NOT_ACTIVE" ;
VAL_ 2558998305 _nu_Warnings_bit34 1 "WARNING_ACTIVE" 0 "WARNING_NOT_ACTIVE" ;
VAL_ 2558998305 _nu_Warnings_bit33 1 "WARNING_ACTIVE" 0 "WARNING_NOT_ACTIVE" ;
VAL_ 2558998305 _nu_Warnings_bit32 1 "WARNING_ACTIVE" 0 "WARNING_NOT_ACTIVE" ;
VAL_ 2558998305 _nu_Warnings_bit31 1 "WARNING_ACTIVE" 0 "WARNING_NOT_ACTIVE" ;
VAL_ 2558998305 _nu_Warnings_bit30 1 "WARNING_ACTIVE" 0 "WARNING_NOT_ACTIVE" ;
VAL_ 2558998305 _nu_Warnings_bit18 1 "WARNING_ACTIVE" 0 "WARNING_NOT_ACTIVE" ;
VAL_ 2558998305 AUX_HEATER_TO_BE_START 1 "WARNING_ACTIVE" 0 "WARNING_NOT_ACTIVE" ;
VAL_ 2558998305 AUX_HEATER_WARNING 1 "WARNING_ACTIVE" 0 "WARNING_NOT_ACTIVE" ;
VAL_ 2558998305 GEARBOX_OVER_TEMP 1 "WARNING_ACTIVE" 0 "WARNING_NOT_ACTIVE" ;
VAL_ 2558998305 LOW_GEARBOX_OIL_LEVEL 1 "WARNING_ACTIVE" 0 "WARNING_NOT_ACTIVE" ;
VAL_ 2558998305 LOW_ENGINE_OIL_LEVEL 1 "WARNING_ACTIVE" 0 "WARNING_NOT_ACTIVE" ;
VAL_ 2558998305 LOW_BATTERY 1 "WARNING_ACTIVE" 0 "WARNING_NOT_ACTIVE" ;
VAL_ 2558998305 FIRE_ALARM 1 "WARNING_ACTIVE" 0 "WARNING_NOT_ACTIVE" ;
VAL_ 2558998305 ENGINE_COOLANT_LEVEL_TOO_LOW 1 "WARNING_ACTIVE" 0 "WARNING_NOT_ACTIVE" ;
VAL_ 2558998305 ENGINE_TEMPERATURE_TOO_HIGH 1 "WARNING_ACTIVE" 0 "WARNING_NOT_ACTIVE" ;
VAL_ 2558998305 OIL_PRESSURE_LOW 1 "WARNING_ACTIVE" 0 "WARNING_NOT_ACTIVE" ;
VAL_ 2558998305 ENGINE_OVERRUN_RETARDER_ACTIVE 1 "WARNING_ACTIVE" 0 "WARNING_NOT_ACTIVE" ;
VAL_ 2558998305 GEARBOX_NOT_IN_NEUTRAL 1 "WARNING_ACTIVE" 0 "WARNING_NOT_ACTIVE" ;
VAL_ 2558998305 BRAKE_NOT_PRESSED 1 "WARNING_ACTIVE" 0 "WARNING_NOT_ACTIVE" ;
VAL_ 2558998305 SYSTEM_POWERED_FROM_EXT_SUPPLY 1 "WARNING_ACTIVE" 0 "WARNING_NOT_ACTIVE" ;
VAL_ 2558998305 KEY_INSERTED 1 "WARNING_ACTIVE" 0 "WARNING_NOT_ACTIVE" ;
VAL_ 2558998305 STARTER_OVERRIDE_IN_PROGRESS 1 "WARNING_ACTIVE" 0 "WARNING_NOT_ACTIVE" ;
VAL_ 2558998305 HYDRONIC_SHUTDOWN_IN_PROGRESS 1 "WARNING_ACTIVE" 0 "WARNING_NOT_ACTIVE" ;
VAL_ 2558998305 BRAKE_FAULT 1 "WARNING_ACTIVE" 0 "WARNING_NOT_ACTIVE" ;
VAL_ 2558998305 DRIVING_WITH_PARK_BRAKE_ACTIVE 1 "WARNING_ACTIVE" 0 "WARNING_NOT_ACTIVE" ;
VAL_ 2558998305 SERVICES_AIR_PRESS_LOW 1 "WARNING_ACTIVE" 0 "WARNING_NOT_ACTIVE" ;
VAL_ 2558998305 ENGINE_NOT_STOP 1 "WARNING_ACTIVE" 0 "WARNING_NOT_ACTIVE" ;
VAL_ 2558998305 DRIVER_HATCH_OPEN 1 "WARNING_ACTIVE" 0 "WARNING_NOT_ACTIVE" ;
VAL_ 2558998305 DUST_EXTRACTION_OFF 1 "WARNING_ACTIVE" 0 "WARNING_NOT_ACTIVE" ;
VAL_ 2558998305 FORD_MODE_ACTIVE 1 "WARNING_ACTIVE" 0 "WARNING_NOT_ACTIVE" ;
VAL_ 2558998305 DANGEROUS_SPEED 1 "WARNING_ACTIVE" 0 "WARNING_NOT_ACTIVE" ;
VAL_ 2558998305 SPEED_TOO_HIGH 1 "WARNING_ACTIVE" 0 "WARNING_NOT_ACTIVE" ;
VAL_ 2558998305 EMERGENCY_CRANK_IN_PROGRESS 1 "WARNING_ACTIVE" 0 "WARNING_NOT_ACTIVE" ;
VAL_ 2558998305 ENGINE_IS_OFF 1 "WARNING_ACTIVE" 0 "WARNING_NOT_ACTIVE" ;
VAL_ 2558801697 EngineAlarm 3 "NOT_AVAILABLE" 2 "LAMP_RED_ON" 1 "LAMP_YELLOW_ON" 0 "LAMP_OFF" ;
VAL_ 2558801697 EngineOilPressureLow_BC 3 "NOT_AVAILABLE" 2 "NOT_VALID" 1 "LAMP_ON" 0 "LAMP_OFF" ;
VAL_ 2558801697 EngineOilTemperatureHigh_BC 3 "NOT_AVAILABLE" 2 "LAMP_BLINK" 1 "LAMP_ON" 0 "LAMP_OFF" ;
VAL_ 2558801697 NBC_Generic_Fault 3 "NOT_AVAILABLE" 2 "LAMP_BLINK" 1 "LAMP_ON" 0 "LAMP_OFF" ;
VAL_ 2558801697 EngineEoilFilterClogged 3 "NOT_AVAILABLE" 2 "LAMP_BLINK" 1 "ALARM_ON" 0 "ALARM_OFF" ;
VAL_ 2558801697 NBC_FilterClogged_Status 3 "NOT_AVAILABLE" 2 "ALARM_ON" 1 "TEST_IN_PROGRESS" 0 "ALARM_OFF" ;
VAL_ 2558801697 NBC_FilterClogged_Alarm 3 "NOT_AVAILABLE" 2 "LAMP_BLINK" 1 "LAMP_ON" 0 "LAMP_OFF" ;
VAL_ 2558801697 Icon_Emergency_Direction 3 "NOT_AVAILABLE" 2 "LAMP_ON_EMERGENCY" 1 "LAMP_ON_DIRECTION" 0 "LAMP_OFF" ;
VAL_ 2558801697 Icon_Light_Status 7 "NOT_USED" 6 "NOT_USED" 5 "LAMP_WAR_2" 4 "LAMP_WAR_1" 3 "LAMP_HIGH_BEAM" 2 "LAMP_LOW_BEAM" 1 "LAMP_MARKER" 0 "LAMP_OFF" ;
VAL_ 2558801697 Icon_Left_Ammunition_Door 3 "NOT_AVAILABLE" 2 "NOT_USED" 1 "LAMP_OPEN_ON" 0 "LAMP_CLOSE_OFF" ;
VAL_ 2558801697 Icon_Retarder 15 "NOT_AVAILABLE" 14 "NOT_USED" 13 "NOT_USED" 12 "NOT_USED" 11 "NOT_USED" 10 "NOT_USED" 9 "NOT_USED" 8 "NOT_USED" 7 "NOT_USED" 6 "NOT_USED" 5 "125" 4 "100" 3 "075" 2 "050" 1 "025" 0 "OFF" ;
VAL_ 2558801697 Icon_Battery_Selected 3 "BATT_N_OFF_A_OFF" 2 "BATT_N_ON_A_ON" 1 "BATT_N_OFF_A_ON" 0 "BATT_N_ON_A_OFF" ;
VAL_ 2558801697 Icon_Battery_Status 3 "LAMP_BLACK" 2 "LAMP_RED_ERROR" 1 "LAMP_YELLOW_WARNING" 0 "LAMP_GREEN_OK" ;
VAL_ 2558801697 Icon_Driver_Hatch 3 "NOT_AVAILABLE" 2 "NOT_USED" 1 "LAMP_OPEN_ON" 0 "LAMP_CLOSE_OFF" ;
VAL_ 2558801697 Icon_Turret_Hatch_Right_Sts 3 "NOT_AVAILABLE" 2 "NOT_USED" 1 "LAMP_OPEN_ON" 0 "LAMP_CLOSE_OFF" ;
VAL_ 2558801697 Icon_Turret_Hatch_Left_Sts 3 "NOT_AVAILABLE" 2 "NOT_USED" 1 "LAMP_OPEN_ON" 0 "LAMP_CLOSE_OFF" ;
VAL_ 2558801697 Icon_Right_Ammunition_Door 3 "NOT_AVAILABLE" 2 "NOT_USED" 1 "LAMP_OPEN_ON" 0 "LAMP_CLOSE_OFF" ;
VAL_ 2558801697 Icon_Rear_Door 3 "NOT_AVAILABLE" 2 "NOT_USED" 1 "LAMP_OPEN_ON" 0 "LAMP_CLOSE_OFF" ;
VAL_ 2558801697 Icon_Rear_Lock 3 "NOT_AVAILABLE" 2 "NOT_USED" 1 "LAMP_LOCKED_ON" 0 "LAMP_LOCKED_OFF" ;
VAL_ 2558801697 ColdStartHeaterStatus_BC 15 "NotUsed_-_Lamp_Off" 14 "NotUsed_-_Lamp_Off" 13 "NotUsed_-_Lamp_Off" 12 "NotUsed_-_Lamp_Off" 11 "NotUsed_-_Lamp_Off" 10 "NotUsed_-_Lamp_Off" 9 "NotUsed_-_Lamp_Off" 8 "TestOfGridHeaterVoltageInProgres_-_Lamp_Off" 7 "Initialization_-_Lamp_Off" 6 "PostHeating_-_Lamp_Off" 5 "CrankWithExtraHeating_-_Lamp_Off" 4 "CrankPhase_-_Lamp_Off" 3 "StandbyWithoutHeating_-_Lamp_Off" 2 "StanbyWithHeating_-_Lamp_Blink" 1 "PreHeatingPhase_-_Lamp_On" 0 "OffPhase_-_Lamp_Off" ;
VAL_ 2558801697 Icon_Payload_Door 3 "NOT_AVAILABLE" 2 "NOT_USED" 1 "LAMP_OPEN_ON" 0 "LAMP_CLOSE_OFF" ;
VAL_ 2558801697 Icon_CTIS_ProcessMode 15 "NotAvailable" 14 "Over_speed_access_denied" 13 "Over_speed_condition" 12 "Over_speed_automatic_inflation" 11 "NotUsed" 10 "NotUsed" 9 "NotUsed" 8 "NotUsed" 7 "NotUsed" 6 "Pressure_Check_Cycle" 5 "NotUsed" 4 "NotUsed" 3 "CTIS_Process_Operation" 2 "Deflating" 1 "Inflating" 0 "Standby" ;
VAL_ 2558670625 Fbk_Clima_Menu 3 "NOT_AVAILABLE" 2 "FBK_BLINK" 1 "FBK_ON" 0 "FBK_OFF" ;
VAL_ 2558670625 Fbk_Clima_Compressor 3 "NOT_AVAILABLE" 2 "FBK_BLINK" 1 "FBK_ON" 0 "FBK_OFF" ;
VAL_ 2558670625 Fbk_Clima_ON_AUTO_MAN 3 "NOT_AVAILABLE_OFF" 2 "CLIMA_MANUAL" 1 "CLIMA_AUTO" 0 "CLIMA_OFF" ;
VAL_ 2558670625 Fbk_Camera_Menu 3 "NOT_AVAILABLE" 2 "FBK_BLINK" 1 "FBK_ON" 0 "FBK_OFF" ;
VAL_ 2558670625 Fbk_CrewAreaHeater 3 "NOT_AVAILABLE" 2 "FBK_BLINK" 1 "FBK_ON" 0 "FBK_OFF" ;
VAL_ 2558670625 Fbk_NUC_Enable 3 "NOT_AVAILABLE" 2 "FBK_BLINK" 1 "FBK_ON" 0 "FBK_OFF" ;
VAL_ 2558670625 Fbk_Polarity 3 "NOT_AVAILABLE" 2 "FBK_BLINK" 1 "BLACK_HOT" 0 "WHITE_HOT" ;
VAL_ 2558670625 Fbk_ROI 3 "FULL_SCREEN" 2 "BOTTOM_HALF" 1 "CENTER_BLOCK" 0 "TOP_HALF" ;
VAL_ 2558670625 Fbk_TYPE 3 "NOT_AVAILABLE_OFF" 2 "FBK_BLINK" 1 "FBK_THERMAL" 0 "FBK_OPTICAL" ;
VAL_ 2558670625 Fbk_ChangeView 3 "CFG_04" 2 "CFG_03" 1 "CFG_02" 0 "CFG_01" ;
VAL_ 2558670625 Fbk_Sights_Washer 3 "NOT_AVAILABLE" 2 "FBK_BLINK" 1 "FBK_ON" 0 "FBK_OFF" ;
VAL_ 2558670625 _nu_Fbk_Not_Used_3_16 3 "NOT_AVAILABLE" 2 "FBK_BLINK" 1 "FBK_ON" 0 "FBK_OFF" ;
VAL_ 2558670625 _nu_Fbk_Not_Used_3_18 3 "NOT_AVAILABLE" 2 "FBK_BLINK" 1 "FBK_ON" 0 "FBK_OFF" ;
VAL_ 2558670625 _nu_Fbk_Not_Used_3_20 3 "NOT_AVAILABLE" 2 "FBK_BLINK" 1 "FBK_ON" 0 "FBK_OFF" ;
VAL_ 2558670625 _nu_Fbk_Not_Used_1_22 3 "NOT_AVAILABLE" 2 "FBK_BLINK" 1 "FBK_ON" 0 "FBK_OFF" ;
VAL_ 2558670625 _nu_Fbk_Not_Used_3_24 3 "NOT_AVAILABLE" 2 "FBK_BLINK" 1 "FBK_ON" 0 "FBK_OFF" ;
VAL_ 2558670625 _nu_Fbk_Not_Used_3_26 3 "NOT_AVAILABLE" 2 "FBK_BLINK" 1 "FBK_ON" 0 "FBK_OFF" ;
VAL_ 2558670625 _nu_Fbk_Not_Used_3_28 3 "NOT_AVAILABLE" 2 "FBK_BLINK" 1 "FBK_ON" 0 "FBK_OFF" ;
VAL_ 2558670625 _nu_Fbk_Not_Used_3_30 3 "NOT_AVAILABLE" 2 "FBK_BLINK" 1 "FBK_ON" 0 "FBK_OFF" ;
VAL_ 2558670625 Fbk_PerimetralVision 3 "NOT_AVAILABLE" 2 "FBK_BLINK" 1 "FBK_ON" 0 "FBK_OFF" ;
VAL_ 2558670625 Fbk_SelMonitor 3 "RIGHT" 2 "CENTRAL" 1 "LEFT" 0 "OFF_NO_MONITOR" ;
VAL_ 2558670625 Fbk_SelTlc 3 "NOT_AVAILABLE" 2 "FBK_BLINK" 1 "FBK_ON" 0 "FBK_OFF" ;
VAL_ 2558670625 Fbk_SelCfg 3 "CFG_04" 2 "CFG_03" 1 "CFG_02" 0 "CFG_01" ;
VAL_ 2558670625 Fbk_SaveCfg 3 "NOT_AVAILABLE" 2 "FBK_BLINK" 1 "FBK_ON" 0 "FBK_OFF" ;
VAL_ 2558670625 Fbk_RestoreCfg 3 "NOT_AVAILABLE" 2 "FBK_BLINK" 1 "FBK_ON" 0 "FBK_OFF" ;
VAL_ 2558670625 Fbk_HeaterTlc 3 "NOT_AVAILABLE" 2 "FBK_BLINK" 1 "FBK_ON" 0 "FBK_OFF" ;
VAL_ 2558670625 Fbk_Overlay 3 "VUHLCAN_VIEWER_ON" 2 "VUHLCAN_VIEWER_OFF" 1 "OVERLAY_ON" 0 "OVERLAY_OFF" ;
VAL_ 2558670625 Fbk_CameraCfg_Menu 3 "NOT_AVAILABLE" 2 "FBK_BLINK" 1 "FBK_ON" 0 "FBK_OFF" ;
VAL_ 2558605089 Fbk_NBC_Menu 3 "NOT_AVAILABLE" 2 "FBK_BLINK" 1 "FBK_ON" 0 "FBK_OFF" ;
VAL_ 2558605089 Fbk_Mask 3 "NOT_AVAILABLE" 2 "FBK_BLINK" 1 "FBK_ON" 0 "FBK_OFF" ;
VAL_ 2558605089 Fbk_NBC_Ventilation_Low 3 "NOT_AVAILABLE" 2 "FBK_BLINK" 1 "FBK_ON" 0 "FBK_OFF" ;
VAL_ 2558605089 Fbk_NBC_Ventilation_Fast 3 "NOT_AVAILABLE" 2 "FBK_BLINK" 1 "FBK_ON" 0 "FBK_OFF" ;
VAL_ 2558605089 Fbk_NBC_FilterMode 3 "NOT_AVAILABLE" 2 "FBK_BLINK" 1 "FBK_ON" 0 "FBK_OFF" ;
VAL_ 2558605089 Fbk_MechParkingBrake 3 "FBK_BLINK_2_OFF" 2 "FBK_BLINK_2_ON" 1 "FBK_ON" 0 "FBK_OFF" ;
VAL_ 2558605089 Fbk_Retarder_Up 3 "NOT_AVAILABLE" 2 "FBK_BLINK" 1 "FBK_ON" 0 "FBK_OFF" ;
VAL_ 2558605089 Fbk_Retarder_OnOff 3 "NOT_AVAILABLE" 2 "FBK_BLINK" 1 "FBK_ON" 0 "FBK_OFF" ;
VAL_ 2558605089 Fbk_Retarder_Down 3 "NOT_AVAILABLE" 2 "FBK_BLINK" 1 "FBK_ON" 0 "FBK_OFF" ;
VAL_ 2558605089 Fbk_CTIS_Menu 3 "NOT_AVAILABLE" 2 "FBK_BLINK" 1 "FBK_ON" 0 "FBK_OFF" ;
VAL_ 2558605089 Fbk_Retarder_Menu 3 "NOT_AVAILABLE" 2 "FBK_BLINK" 1 "FBK_ON" 0 "FBK_OFF" ;
VAL_ 2558605089 Fbk_CTIS_Check 3 "NOT_AVAILABLE" 2 "FBK_BLINK" 1 "FBK_ON" 0 "FBK_OFF" ;
VAL_ 2558605089 Fbk_CTIS_Load 3 "LOAD_FULL" 2 "LOAD_HALF" 1 "LOAD_EMPTY" 0 "LOAD_OFF" ;
VAL_ 2558605089 Fbk_CTIS_Emergency 3 "NOT_AVAILABLE" 2 "FBK_BLINK" 1 "FBK_ON" 0 "FBK_OFF" ;
VAL_ 2558605089 Fbk_CTIS_Sand 3 "NOT_AVAILABLE" 2 "FBK_BLINK" 1 "FBK_ON" 0 "FBK_OFF" ;
VAL_ 2558605089 Fbk_CTIS_Track 3 "NOT_AVAILABLE" 2 "FBK_BLINK" 1 "FBK_ON" 0 "FBK_OFF" ;
VAL_ 2558605089 Fbk_CTIS_Road 3 "NOT_AVAILABLE" 2 "FBK_BLINK" 1 "FBK_ON" 0 "FBK_OFF" ;
VAL_ 2558605089 Fbk_CTIS_ON 3 "NOT_AVAILABLE" 2 "FBK_BLINK" 1 "FBK_ON" 0 "FBK_OFF" ;
VAL_ 2558605089 _nu_Fbk_Not_Used_2_06 3 "NOT_AVAILABLE" 2 "FBK_BLINK" 1 "FBK_ON" 0 "FBK_OFF" ;
VAL_ 2558605089 _nu_Fbk_Not_Used_2_08 3 "NOT_AVAILABLE" 2 "FBK_BLINK" 1 "FBK_ON" 0 "FBK_OFF" ;
VAL_ 2558605089 _nu_Fbk_Not_Used_2_10 3 "NOT_AVAILABLE" 2 "FBK_BLINK" 1 "FBK_ON" 0 "FBK_OFF" ;
VAL_ 2558605089 _nu_Fbk_Not_Used_2_38 3 "NOT_AVAILABLE" 2 "FBK_BLINK" 1 "FBK_ON" 0 "FBK_OFF" ;
VAL_ 2558605089 Fbk_NBCReset 3 "NOT_AVAILABLE" 2 "FBK_BLINK" 1 "FBK_ON" 0 "FBK_OFF" ;
VAL_ 2558605089 _nu_Fbk_Not_Used_2_42 3 "NOT_AVAILABLE" 2 "FBK_BLINK" 1 "FBK_ON" 0 "FBK_OFF" ;
VAL_ 2558605089 _nu_Fbk_Not_Used_2_48 3 "NOT_AVAILABLE" 2 "FBK_BLINK" 1 "FBK_ON" 0 "FBK_OFF" ;
VAL_ 2558605089 _nu_Fbk_Not_Used_2_50 3 "NOT_AVAILABLE" 2 "FBK_BLINK" 1 "FBK_ON" 0 "FBK_OFF" ;
VAL_ 2558605089 _nu_Fbk_Not_Used_2_52 3 "NOT_AVAILABLE" 2 "FBK_BLINK" 1 "FBK_ON" 0 "FBK_OFF" ;
VAL_ 2558605089 _nu_Fbk_Not_Used_2_54 3 "NOT_AVAILABLE" 2 "FBK_BLINK" 1 "FBK_ON" 0 "FBK_OFF" ;
VAL_ 2558605089 _nu_Fbk_Not_Used_2_56 3 "NOT_AVAILABLE" 2 "FBK_BLINK" 1 "FBK_ON" 0 "FBK_OFF" ;
VAL_ 2558605089 _nu_Fbk_Not_Used_2_58 3 "NOT_AVAILABLE" 2 "FBK_BLINK" 1 "FBK_ON" 0 "FBK_OFF" ;
VAL_ 2558605089 _nu_Fbk_Not_Used_2_60 3 "NOT_AVAILABLE" 2 "FBK_BLINK" 1 "FBK_ON" 0 "FBK_OFF" ;
VAL_ 2558605089 _nu_Fbk_Not_Used_2_62 3 "NOT_AVAILABLE" 2 "FBK_BLINK" 1 "FBK_ON" 0 "FBK_OFF" ;
VAL_ 2558539553 Fbk_Emergency_Blinker 3 "NOT_AVAILABLE" 2 "FBK_BLINK" 1 "FBK_ON" 0 "FBK_OFF" ;
VAL_ 2558539553 Fbk_Engine_Aux_Heater 3 "NOT_AVAILABLE" 2 "FBK_BLINK" 1 "FBK_ON" 0 "FBK_OFF" ;
VAL_ 2558539553 Fbk_Driveline_Menu 3 "NOT_AVAILABLE" 2 "FBK_BLINK" 1 "FBK_ON" 0 "FBK_OFF" ;
VAL_ 2558539553 Fbk_Aux_Menu 3 "NOT_AVAILABLE" 2 "FBK_BLINK" 1 "FBK_ON" 0 "FBK_OFF" ;
VAL_ 2558539553 Fbk_Light_Menu 3 "NOT_AVAILABLE" 2 "FBK_BLINK" 1 "FBK_ON" 0 "FBK_OFF" ;
VAL_ 2558539553 Fbk_Four_Axle 3 "FBK_BLINK_2_OFF" 2 "FBK_BLINK_2_ON" 1 "FBK_ON" 0 "FBK_OFF" ;
VAL_ 2558539553 Fbk_Lock_Diff 3 "FBK_BLINK_2_OFF" 2 "FBK_BLINK_2_ON" 1 "FBK_ON" 0 "FBK_OFF" ;
VAL_ 2558539553 Fbk_All_Wheel_Drive 3 "FBK_BLINK_2_OFF" 2 "FBK_BLINK_2_ON" 1 "FBK_ON" 0 "FBK_OFF" ;
VAL_ 2558539553 Fbk_Ford_Mode 3 "FBK_BLINK_2_OFF" 2 "FBK_BLINK_2_ON" 1 "FBK_ON" 0 "FBK_OFF" ;
VAL_ 2558539553 Fbk_Bilge_Pump_EngineBay 3 "NOT_AVAILABLE" 2 "FBK_BLINK" 1 "FBK_ON" 0 "FBK_OFF" ;
VAL_ 2558539553 Fbk_Dust_Fan 3 "NOT_AVAILABLE" 2 "FBK_BLINK" 1 "FBK_ON" 0 "FBK_OFF" ;
VAL_ 2558539553 Fbk_Warlight_B2 3 "NOT_AVAILABLE" 2 "FBK_BLINK" 1 "FBK_ON" 0 "FBK_OFF" ;
VAL_ 2558539553 Fbk_Warlight_B1 3 "NOT_AVAILABLE" 2 "FBK_BLINK" 1 "FBK_ON" 0 "FBK_OFF" ;
VAL_ 2558539553 Fbk_Low_Beam_Light 3 "NOT_AVAILABLE" 2 "FBK_BLINK" 1 "FBK_ON" 0 "FBK_OFF" ;
VAL_ 2558539553 Fbk_Marker_Light 3 "NOT_AVAILABLE" 2 "FBK_BLINK" 1 "FBK_ON" 0 "FBK_OFF" ;
VAL_ 2558539553 _nu_Fbk_Not_Used_1_02 3 "NOT_AVAILABLE" 2 "FBK_BLINK" 1 "FBK_ON" 0 "FBK_OFF" ;
VAL_ 2558539553 _nu_Fbk_Not_Used_1_08 3 "NOT_AVAILABLE" 2 "FBK_BLINK" 1 "FBK_ON" 0 "FBK_OFF" ;
VAL_ 2558539553 Fbk_Fuel_Pump 3 "NOT_AVAILABLE" 2 "FBK_BLINK" 1 "FBK_ON" 0 "FBK_OFF" ;
VAL_ 2558539553 _nu_Fbk_Not_Used_1_26 3 "NOT_AVAILABLE" 2 "FBK_BLINK" 1 "FBK_ON" 0 "FBK_OFF" ;
VAL_ 2558539553 Fbk_TripReset 3 "NOT_AVAILABLE" 2 "FBK_BLINK" 1 "FBK_ON" 0 "FBK_OFF" ;
VAL_ 2558539553 _nu_Fbk_Not_Used_1_32 3 "NOT_AVAILABLE" 2 "FBK_BLINK" 1 "FBK_ON" 0 "FBK_OFF" ;
VAL_ 2558539553 _nu_Fbk_Not_Used_1_34 3 "NOT_AVAILABLE" 2 "FBK_BLINK" 1 "FBK_ON" 0 "FBK_OFF" ;
VAL_ 2558539553 _nu_Fbk_Not_Used_1_36 3 "NOT_AVAILABLE" 2 "FBK_BLINK" 1 "FBK_ON" 0 "FBK_OFF" ;
VAL_ 2558539553 _nu_Fbk_Not_Used_1_38 3 "NOT_AVAILABLE" 2 "FBK_BLINK" 1 "FBK_ON" 0 "FBK_OFF" ;
VAL_ 2558539553 _nu_Fbk_Not_Used_1_40 3 "NOT_AVAILABLE" 2 "FBK_BLINK" 1 "FBK_ON" 0 "FBK_OFF" ;
VAL_ 2558539553 _nu_Fbk_Not_Used_1_42 3 "NOT_AVAILABLE" 2 "FBK_BLINK" 1 "FBK_ON" 0 "FBK_OFF" ;
VAL_ 2558539553 _nu_Fbk_Not_Used_1_44 3 "NOT_AVAILABLE" 2 "FBK_BLINK" 1 "FBK_ON" 0 "FBK_OFF" ;
VAL_ 2558539553 _nu_Fbk_Not_Used_1_46 3 "NOT_AVAILABLE" 2 "FBK_BLINK" 1 "FBK_ON" 0 "FBK_OFF" ;
VAL_ 2558539553 _nu_Fbk_Not_Used_1_54 3 "NOT_AVAILABLE" 2 "FBK_BLINK" 1 "FBK_ON" 0 "FBK_OFF" ;
VAL_ 2558539553 _nu_Fbk_Not_Used_1_56 3 "NOT_AVAILABLE" 2 "FBK_BLINK" 1 "FBK_ON" 0 "FBK_OFF" ;
VAL_ 2558539553 _nu_Fbk_Not_Used_1_58 3 "NOT_AVAILABLE" 2 "FBK_BLINK" 1 "FBK_ON" 0 "FBK_OFF" ;
VAL_ 2558539553 _nu_Fbk_Not_Used_1_60 3 "NOT_AVAILABLE" 2 "FBK_BLINK" 1 "FBK_ON" 0 "FBK_OFF" ;
VAL_ 2558599447 Btn_Clima_Vent_Up_CP6 1 "PRESSED" 0 "RELEASED" ;
VAL_ 2558599447 Btn_Clima_Vent_Down_CP6 1 "PRESSED" 0 "RELEASED" ;
VAL_ 2558599447 Btn_Clima_Temp_Up_CP6 1 "PRESSED" 0 "RELEASED" ;
VAL_ 2558599447 Btn_Clima_Temp_Down_CP6 1 "PRESSED" 0 "RELEASED" ;
VAL_ 2558599447 Btn_Clima_ON_AUTO_MAN_CP6 1 "PRESSED" 0 "RELEASED" ;
VAL_ 2558599447 Btn_Clima_Compressor_CP6 1 "PRESSED" 0 "RELEASED" ;
VAL_ 2558599447 Btn_CrewAreaHeater_CP6 1 "PRESSED" 0 "RELEASED" ;
VAL_ 2558599447 Btn_NBC_Ventilation_Low_CP6 1 "PRESSED" 0 "RELEASED" ;
VAL_ 2558599447 Btn_NBC_Ventilation_Fast_CP6 1 "PRESSED" 0 "RELEASED" ;
VAL_ 2558599447 Btn_NBC_FilterMode_CP6 1 "PRESSED" 0 "RELEASED" ;
VAL_ 2558599447 Btn_Mask_CP6 1 "PRESSED" 0 "RELEASED" ;
VAL_ 2558599447 Btn_NUC_Enable_CP6 1 "PRESSED" 0 "RELEASED" ;
VAL_ 2558599447 Btn_Polarity_CP6 1 "PRESSED" 0 "RELEASED" ;
VAL_ 2558599447 Btn_ROI_CP6 1 "PRESSED" 0 "RELEASED" ;
VAL_ 2558599447 Btn_TYPE_CP6 1 "PRESSED" 0 "RELEASED" ;
VAL_ 2558599447 Btn_ChangeView_CP6 1 "PRESSED" 0 "RELEASED" ;
VAL_ 2558599447 _nu_Btn_1_03_CP6 1 "PRESSED" 0 "RELEASED" ;
VAL_ 2558599447 Btn_NBCReset_CP6 1 "PRESSED" 0 "RELEASED" ;
VAL_ 2558599447 _nu_Btn_1_05_CP6 1 "PRESSED" 0 "RELEASED" ;
VAL_ 2558599447 _nu_Btn_1_07_CP6 1 "PRESSED" 0 "RELEASED" ;
VAL_ 2558599447 _nu_Btn_1_08_CP6 1 "PRESSED" 0 "RELEASED" ;
VAL_ 2558599447 _nu_Btn_1_09_CP6 1 "PRESSED" 0 "RELEASED" ;
VAL_ 2558599447 _nu_Btn_1_10_CP6 1 "PRESSED" 0 "RELEASED" ;
VAL_ 2558599447 _nu_Btn_1_11_CP6 1 "PRESSED" 0 "RELEASED" ;
VAL_ 2558599447 _nu_Btn_1_12_CP6 1 "PRESSED" 0 "RELEASED" ;
VAL_ 2558599447 _nu_Btn_1_13_CP6 1 "PRESSED" 0 "RELEASED" ;
VAL_ 2558599447 _nu_Btn_1_14_CP6 1 "PRESSED" 0 "RELEASED" ;
VAL_ 2558599447 _nu_Btn_1_15_CP6 1 "PRESSED" 0 "RELEASED" ;
VAL_ 2558599447 _nu_Btn_1_23_CP6 1 "PRESSED" 0 "RELEASED" ;
VAL_ 2558599447 _nu_Btn_1_24_CP6 1 "PRESSED" 0 "RELEASED" ;
VAL_ 2558599447 _nu_Btn_1_25_CP6 1 "PRESSED" 0 "RELEASED" ;
VAL_ 2558599447 _nu_Btn_1_26_CP6 1 "PRESSED" 0 "RELEASED" ;
VAL_ 2558599447 _nu_Btn_1_27_CP6 1 "PRESSED" 0 "RELEASED" ;
VAL_ 2558599447 _nu_Btn_1_28_CP6 1 "PRESSED" 0 "RELEASED" ;
VAL_ 2558599447 _nu_Btn_1_29_CP6 1 "PRESSED" 0 "RELEASED" ;
VAL_ 2558599447 _nu_Btn_1_30_CP6 1 "PRESSED" 0 "RELEASED" ;
VAL_ 2558599447 _nu_Btn_1_31_CP6 1 "PRESSED" 0 "RELEASED" ;
VAL_ 2558599447 Btn_PerimetralVision_CP6 1 "PRESSED" 0 "RELEASED" ;
VAL_ 2558599447 Btn_SelMonitor_CP6 1 "PRESSED" 0 "RELEASED" ;
VAL_ 2558599447 _nu_Btn_1_39_CP6 1 "PRESSED" 0 "RELEASED" ;
VAL_ 2558599447 Btn_Sights_Washer_CP6 1 "PRESSED" 0 "RELEASED" ;
VAL_ 2558599447 Btn_SelTlc_CP6 1 "PRESSED" 0 "RELEASED" ;
VAL_ 2558599447 Btn_SelCfg_CP6 1 "PRESSED" 0 "RELEASED" ;
VAL_ 2558599447 Btn_SaveCfg_CP6 1 "PRESSED" 0 "RELEASED" ;
VAL_ 2558599447 Btn_RestoreCfg_CP6 1 "PRESSED" 0 "RELEASED" ;
VAL_ 2558599447 Btn_HeaterTlc_CP6 1 "PRESSED" 0 "RELEASED" ;
VAL_ 2558599447 Btn_Overlay_CP6 1 "PRESSED" 0 "RELEASED" ;
VAL_ 2558599447 _nu_Btn_1_47_CP6 1 "PRESSED" 0 "RELEASED" ;
VAL_ 2558599447 _nu_Btn_1_48_CP6 1 "PRESSED" 0 "RELEASED" ;
VAL_ 2558599447 _nu_Btn_1_49_CP6 1 "PRESSED" 0 "RELEASED" ;
VAL_ 2558599447 _nu_Btn_1_50_CP6 1 "PRESSED" 0 "RELEASED" ;
VAL_ 2558599447 _nu_Btn_1_51_CP6 1 "PRESSED" 0 "RELEASED" ;
VAL_ 2558599447 _nu_Btn_1_52_CP6 1 "PRESSED" 0 "RELEASED" ;
VAL_ 2558599447 _nu_Btn_1_53_CP6 1 "PRESSED" 0 "RELEASED" ;
VAL_ 2558599447 _nu_Btn_1_54_CP6 1 "PRESSED" 0 "RELEASED" ;
VAL_ 2558599447 _nu_Btn_1_55_CP6 1 "PRESSED" 0 "RELEASED" ;
VAL_ 2558599447 _nu_Btn_1_56_CP6 1 "PRESSED" 0 "RELEASED" ;
VAL_ 2558599447 _nu_Btn_1_57_CP6 1 "PRESSED" 0 "RELEASED" ;
VAL_ 2558599447 _nu_Btn_1_58_CP6 1 "PRESSED" 0 "RELEASED" ;
VAL_ 2558599447 _nu_Btn_1_59_CP6 1 "PRESSED" 0 "RELEASED" ;
VAL_ 2558599447 _nu_Btn_1_60_CP6 1 "PRESSED" 0 "RELEASED" ;
VAL_ 2558599447 _nu_Btn_1_61_CP6 1 "PRESSED" 0 "RELEASED" ;
VAL_ 2558599447 _nu_Btn_1_62_CP6 1 "PRESSED" 0 "RELEASED" ;
VAL_ 2558599447 _nu_Btn_1_63_CP6 1 "PRESSED" 0 "RELEASED" ;
VAL_ 2558533911 Btn_EngineHeater_CP6 1 "PRESSED" 0 "RELEASED" ;
VAL_ 2558533911 Btn_ParkingBrake_CP6 1 "PRESSED" 0 "RELEASED" ;
VAL_ 2558533911 Btn_CTIS_Check_CP6 1 "PRESSED" 0 "RELEASED" ;
VAL_ 2558533911 Btn_CTIS_Load_CP6 1 "PRESSED" 0 "RELEASED" ;
VAL_ 2558533911 Btn_CTIS_Emergency_CP6 1 "PRESSED" 0 "RELEASED" ;
VAL_ 2558533911 Btn_CTIS_Sand_CP6 1 "PRESSED" 0 "RELEASED" ;
VAL_ 2558533911 Btn_CTIS_Track_CP6 1 "PRESSED" 0 "RELEASED" ;
VAL_ 2558533911 Btn_CTIS_Road_Cp6 1 "PRESSED" 0 "RELEASED" ;
VAL_ 2558533911 Btn_CTIS_ON_CP6 1 "PRESSED" 0 "RELEASED" ;
VAL_ 2558533911 Btn_Retarder_Down_CP6 1 "PRESSED" 0 "RELEASED" ;
VAL_ 2558533911 Btn_Retarder_Up_CP6 1 "PRESSED" 0 "RELEASED" ;
VAL_ 2558533911 Btn_Retarder_Off_CP6 1 "PRESSED" 0 "RELEASED" ;
VAL_ 2558533911 Btn_4th_Steering_Axle_CP6 1 "PRESSED" 0 "RELEASED" ;
VAL_ 2558533911 Btn_Lock_Front_Diff_CP6 1 "PRESSED" 0 "RELEASED" ;
VAL_ 2558533911 Btn_All_Wheel_Drive_CP6 1 "PRESSED" 0 "RELEASED" ;
VAL_ 2558533911 Btn_Ford_Mode_CP6 1 "PRESSED" 0 "RELEASED" ;
VAL_ 2558533911 Btn_Bilge_Pump_EngineBay_CP6 1 "PRESSED" 0 "RELEASED" ;
VAL_ 2558533911 Btn_TripReset_CP6 1 "PRESSED" 0 "RELEASED" ;
VAL_ 2558533911 Btn_Dust_Fan_CP6 1 "PRESSED" 0 "RELEASED" ;
VAL_ 2558533911 Btn_FuelPumpCP6 1 "PRESSED" 0 "RELEASED" ;
VAL_ 2558533911 Btn_Warlight_B2_CP6 1 "PRESSED" 0 "RELEASED" ;
VAL_ 2558533911 Btn_Warlight_B1_CP6 1 "PRESSED" 0 "RELEASED" ;
VAL_ 2558533911 Btn_Low_Beam_Light_CP6 1 "PRESSED" 0 "RELEASED" ;
VAL_ 2558533911 Btn_Marker_Light_CP6 1 "PRESSED" 0 "RELEASED" ;
VAL_ 2558533911 Btn_Emergency_Blinker_CP6 1 "PRESSED" 0 "RELEASED" ;
VAL_ 2558533911 _nu_Btn_2_01_CP6 1 "PRESSED" 0 "RELEASED" ;
VAL_ 2558533911 _nu_Btn_2_04_CP6 1 "PRESSED" 0 "RELEASED" ;
VAL_ 2558533911 _nu_Btn_2_07_CP6 1 "PRESSED" 0 "RELEASED" ;
VAL_ 2558533911 Btn_Change_h_km_CP6 1 "PRESSED" 0 "RELEASED" ;
VAL_ 2558533911 _nu_Btn_2_15_CP6 1 "PRESSED" 0 "RELEASED" ;
VAL_ 2558533911 _nu_Btn_2_16_CP6 1 "PRESSED" 0 "RELEASED" ;
VAL_ 2558533911 _nu_Btn_2_17_CP6 1 "PRESSED" 0 "RELEASED" ;
VAL_ 2558533911 _nu_Btn_2_18_CP6 1 "PRESSED" 0 "RELEASED" ;
VAL_ 2558533911 _nu_Btn_2_19_CP6 1 "PRESSED" 0 "RELEASED" ;
VAL_ 2558533911 _nu_Btn_2_20_CP6 1 "PRESSED" 0 "RELEASED" ;
VAL_ 2558533911 _nu_Btn_2_21_CP6 1 "PRESSED" 0 "RELEASED" ;
VAL_ 2558533911 _nu_Btn_2_22_CP6 1 "PRESSED" 0 "RELEASED" ;
VAL_ 2558533911 _nu_Btn_2_23_CP6 1 "PRESSED" 0 "RELEASED" ;
VAL_ 2558533911 _nu_Btn_2_27_CP6 1 "PRESSED" 0 "RELEASED" ;
VAL_ 2558533911 _nu_Btn_2_28_CP6 1 "PRESSED" 0 "RELEASED" ;
VAL_ 2558533911 _nu_Btn_2_29_CP6 1 "PRESSED" 0 "RELEASED" ;
VAL_ 2558533911 _nu_Btn_2_30_CP6 1 "PRESSED" 0 "RELEASED" ;
VAL_ 2558533911 _nu_Btn_2_31_CP6 1 "PRESSED" 0 "RELEASED" ;
VAL_ 2558533911 _nu_Btn_2_35_CP6 1 "PRESSED" 0 "RELEASED" ;
VAL_ 2558533911 _nu_Btn_2_36_CP6 1 "PRESSED" 0 "RELEASED" ;
VAL_ 2558533911 _nu_Btn_2_37_CP6 1 "PRESSED" 0 "RELEASED" ;
VAL_ 2558533911 _nu_Btn_2_39_CP6 1 "PRESSED" 0 "RELEASED" ;
VAL_ 2558533911 _nu_Btn_2_47_CP6 1 "PRESSED" 0 "RELEASED" ;
VAL_ 2558533911 _nu_Btn_2_48_CP6 1 "PRESSED" 0 "RELEASED" ;
VAL_ 2558533911 _nu_Btn_2_49_CP6 1 "PRESSED" 0 "RELEASED" ;
VAL_ 2558533911 _nu_Btn_2_50_CP6 1 "PRESSED" 0 "RELEASED" ;
VAL_ 2558533911 _nu_Btn_2_51_CP6 1 "PRESSED" 0 "RELEASED" ;
VAL_ 2558533911 _nu_Btn_2_52_CP6 1 "PRESSED" 0 "RELEASED" ;
VAL_ 2558533911 _nu_Btn_2_53_CP6 1 "PRESSED" 0 "RELEASED" ;
VAL_ 2558533911 _nu_Btn_2_54_CP6 1 "PRESSED" 0 "RELEASED" ;
VAL_ 2558533911 _nu_Btn_2_55_CP6 1 "PRESSED" 0 "RELEASED" ;
VAL_ 2558533911 _nu_Btn_2_56_CP6 1 "PRESSED" 0 "RELEASED" ;
VAL_ 2558533911 _nu_Btn_2_57_CP6 1 "PRESSED" 0 "RELEASED" ;
VAL_ 2558533911 _nu_Btn_2_58_CP6 1 "PRESSED" 0 "RELEASED" ;
VAL_ 2558533911 _nu_Btn_2_59_CP6 1 "PRESSED" 0 "RELEASED" ;
VAL_ 2558533911 _nu_Btn_2_60_CP6 1 "PRESSED" 0 "RELEASED" ;
VAL_ 2558533911 _nu_Btn_2_61_CP6 1 "PRESSED" 0 "RELEASED" ;
VAL_ 2558533911 _nu_Btn_2_62_CP6 1 "PRESSED" 0 "RELEASED" ;
VAL_ 2558533911 _nu_Btn_2_63_CP6 1 "PRESSED" 0 "RELEASED" ;
VAL_ 2558599479 Btn_NBC_Ventilation_Low_CP10 1 "PRESSED" 0 "RELEASED" ;
VAL_ 2558599479 Btn_NBC_Ventilation_Fast_CP10 1 "PRESSED" 0 "RELEASED" ;
VAL_ 2558599479 Btn_NBC_FilterMode_CP10 1 "PRESSED" 0 "RELEASED" ;
VAL_ 2558599479 Btn_Mask_CP10 1 "PRESSED" 0 "RELEASED" ;
VAL_ 2558599479 Btn_CrewAreaHeater_CP10 1 "PRESSED" 0 "RELEASED" ;
VAL_ 2558599479 Btn_Clima_Vent_Up_CP10 1 "PRESSED" 0 "RELEASED" ;
VAL_ 2558599479 Btn_Clima_Vent_Down_CP10 1 "PRESSED" 0 "RELEASED" ;
VAL_ 2558599479 Btn_Clima_Temp_Up_CP10 1 "PRESSED" 0 "RELEASED" ;
VAL_ 2558599479 Btn_Clima_Temp_Down_CP10 1 "PRESSED" 0 "RELEASED" ;
VAL_ 2558599479 Btn_Clima_ON_AUTO_MAN_CP10 1 "PRESSED" 0 "RELEASED" ;
VAL_ 2558599479 Btn_Clima_Compressor_CP10 1 "PRESSED" 0 "RELEASED" ;
VAL_ 2558599479 Btn_NUC_Enable_CP10 1 "PRESSED" 0 "RELEASED" ;
VAL_ 2558599479 Btn_Polarity_CP10 1 "PRESSED" 0 "RELEASED" ;
VAL_ 2558599479 Btn_ROI_CP10 1 "PRESSED" 0 "RELEASED" ;
VAL_ 2558599479 Btn_TYPE_CP10 1 "PRESSED" 0 "RELEASED" ;
VAL_ 2558599479 Btn_ChangeView_CP10 1 "PRESSED" 0 "RELEASED" ;
VAL_ 2558599479 _nu_Btn_1_03_CP10 1 "PRESSED" 0 "RELEASED" ;
VAL_ 2558599479 Btn_NBCReset_CP10 1 "PRESSED" 0 "RELEASED" ;
VAL_ 2558599479 _nu_Btn_1_05_CP10 1 "PRESSED" 0 "RELEASED" ;
VAL_ 2558599479 _nu_Btn_1_07_CP10 1 "PRESSED" 0 "RELEASED" ;
VAL_ 2558599479 _nu_Btn_1_08_CP10 1 "PRESSED" 0 "RELEASED" ;
VAL_ 2558599479 _nu_Btn_1_09_CP10 1 "PRESSED" 0 "RELEASED" ;
VAL_ 2558599479 _nu_Btn_1_10_CP10 1 "PRESSED" 0 "RELEASED" ;
VAL_ 2558599479 _nu_Btn_1_11_CP10 1 "PRESSED" 0 "RELEASED" ;
VAL_ 2558599479 _nu_Btn_1_12_CP10 1 "PRESSED" 0 "RELEASED" ;
VAL_ 2558599479 _nu_Btn_1_13_CP10 1 "PRESSED" 0 "RELEASED" ;
VAL_ 2558599479 _nu_Btn_1_14_CP10 1 "PRESSED" 0 "RELEASED" ;
VAL_ 2558599479 _nu_Btn_1_15_CP10 1 "PRESSED" 0 "RELEASED" ;
VAL_ 2558599479 _nu_Btn_1_23_CP10 1 "PRESSED" 0 "RELEASED" ;
VAL_ 2558599479 _nu_Btn_1_24_CP10 1 "PRESSED" 0 "RELEASED" ;
VAL_ 2558599479 _nu_Btn_1_25_CP10 1 "PRESSED" 0 "RELEASED" ;
VAL_ 2558599479 _nu_Btn_1_26_CP10 1 "PRESSED" 0 "RELEASED" ;
VAL_ 2558599479 _nu_Btn_1_27_CP10 1 "PRESSED" 0 "RELEASED" ;
VAL_ 2558599479 _nu_Btn_1_28_CP10 1 "PRESSED" 0 "RELEASED" ;
VAL_ 2558599479 _nu_Btn_1_29_CP10 1 "PRESSED" 0 "RELEASED" ;
VAL_ 2558599479 _nu_Btn_1_30_CP10 1 "PRESSED" 0 "RELEASED" ;
VAL_ 2558599479 _nu_Btn_1_31_CP10 1 "PRESSED" 0 "RELEASED" ;
VAL_ 2558599479 Btn_PerimetralVision_CP10 1 "PRESSED" 0 "RELEASED" ;
VAL_ 2558599479 Btn_SelMonitor_CP10 1 "PRESSED" 0 "RELEASED" ;
VAL_ 2558599479 _nu_Btn_1_39_CP10 1 "PRESSED" 0 "RELEASED" ;
VAL_ 2558599479 Btn_Sights_Washer_CP10 1 "PRESSED" 0 "RELEASED" ;
VAL_ 2558599479 Btn_SelTlc_CP10 1 "PRESSED" 0 "RELEASED" ;
VAL_ 2558599479 Btn_SelCfg_CP10 1 "PRESSED" 0 "RELEASED" ;
VAL_ 2558599479 Btn_SaveCfg_CP10 1 "PRESSED" 0 "RELEASED" ;
VAL_ 2558599479 Btn_RestoreCfg_CP10 1 "PRESSED" 0 "RELEASED" ;
VAL_ 2558599479 Btn_HeaterTlc_CP10 1 "PRESSED" 0 "RELEASED" ;
VAL_ 2558599479 Btn_Overlay_CP10 1 "PRESSED" 0 "RELEASED" ;
VAL_ 2558599479 _nu_Btn_1_47_CP10 1 "PRESSED" 0 "RELEASED" ;
VAL_ 2558599479 _nu_Btn_1_48_CP10 1 "PRESSED" 0 "RELEASED" ;
VAL_ 2558599479 _nu_Btn_1_49_CP10 1 "PRESSED" 0 "RELEASED" ;
VAL_ 2558599479 _nu_Btn_1_50_CP10 1 "PRESSED" 0 "RELEASED" ;
VAL_ 2558599479 _nu_Btn_1_51_CP10 1 "PRESSED" 0 "RELEASED" ;
VAL_ 2558599479 _nu_Btn_1_52_CP10 1 "PRESSED" 0 "RELEASED" ;
VAL_ 2558599479 _nu_Btn_1_53_CP10 1 "PRESSED" 0 "RELEASED" ;
VAL_ 2558599479 _nu_Btn_1_54_CP10 1 "PRESSED" 0 "RELEASED" ;
VAL_ 2558599479 _nu_Btn_1_55_CP10 1 "PRESSED" 0 "RELEASED" ;
VAL_ 2558599479 _nu_Btn_1_56_CP10 1 "PRESSED" 0 "RELEASED" ;
VAL_ 2558599479 _nu_Btn_1_57_CP10 1 "PRESSED" 0 "RELEASED" ;
VAL_ 2558599479 _nu_Btn_1_58_CP10 1 "PRESSED" 0 "RELEASED" ;
VAL_ 2558599479 _nu_Btn_1_59_CP10 1 "PRESSED" 0 "RELEASED" ;
VAL_ 2558599479 _nu_Btn_1_60_CP10 1 "PRESSED" 0 "RELEASED" ;
VAL_ 2558599479 _nu_Btn_1_61_CP10 1 "PRESSED" 0 "RELEASED" ;
VAL_ 2558599479 _nu_Btn_1_62_CP10 1 "PRESSED" 0 "RELEASED" ;
VAL_ 2558599479 _nu_Btn_1_63_CP10 1 "PRESSED" 0 "RELEASED" ;
